VERSION ""

NS_ :

BS_:

BU_: WSGW VCM TBIOM RCIOM FCIOM CCIOM BPMU

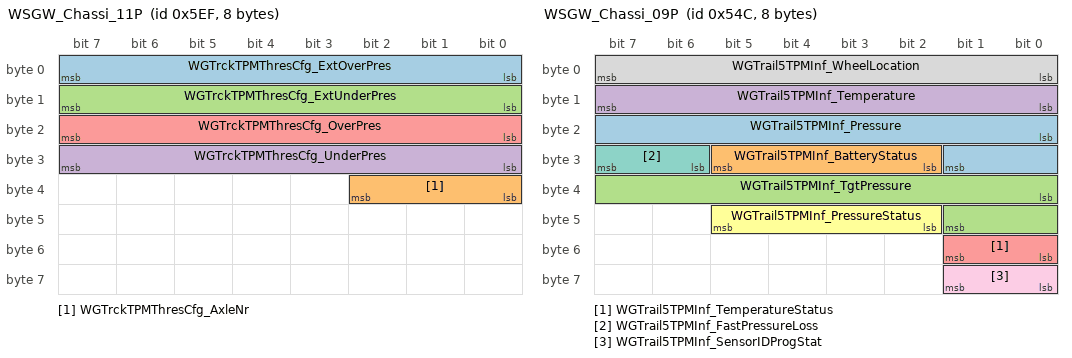
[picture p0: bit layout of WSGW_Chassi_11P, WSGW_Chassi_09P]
BO_ 1519 WSGW_Chassi_11P: 8 WSGW
 SG_ WGTrckTPMThresCfg_ExtOverPres : 0|8@1+ (1,-125) [-125|130] "Percent"  VCM
 SG_ WGTrckTPMThresCfg_AxleNr : 32|3@1+ (1,0) [0|0] ""  VCM
 SG_ WGTrckTPMThresCfg_ExtUnderPres : 8|8@1+ (1,-125) [-125|130] "Percent"  VCM
 SG_ WGTrckTPMThresCfg_UnderPres : 24|8@1+ (1,-125) [-125|130] "Percent"  VCM
 SG_ WGTrckTPMThresCfg_OverPres : 16|8@1+ (1,-125) [-125|130] "Percent"  VCM

BO_ 1513 WSGW_Chassi_10S_C04_FCM: 8 VCM
 SG_ WSGW_Chassi_10S_FCS : 0|64@1+ (1,0) [0|0] ""  WSGW

BO_ 1512 WSGW_Chassi_10S_C04: 21 WSGW
 SG_ PhyDiagTPM2BrkReqSig_ISig_4 : 0|168@1+ (1,0) [0|0] ""  VCM

BO_ 1356 WSGW_Chassi_09P: 8 WSGW
 SG_ WGTrail5TPMInf_Pressure : 16|10@1+ (2,0) [0|2046] "kPa"  VCM
 SG_ WGTrail5TPMInf_BatteryStatus : 26|4@1+ (1,0) [0|0] ""  VCM
 SG_ WGTrail5TPMInf_TgtPressure : 32|10@1+ (2,0) [0|2046] "kPa"  VCM
 SG_ WGTrail5TPMInf_Temperature : 8|8@1+ (1,-40) [-40|215] "DegreeC"  VCM
 SG_ WGTrail5TPMInf_TemperatureStatus : 48|2@1+ (1,0) [0|0] ""  VCM
 SG_ WGTrail5TPMInf_PressureStatus : 42|4@1+ (1,0) [0|0] ""  VCM
 SG_ WGTrail5TPMInf_FastPressureLoss : 30|2@1+ (1,0) [0|0] ""  VCM
 SG_ WGTrail5TPMInf_WheelLocation : 0|8@1+ (1,0) [0|255] "NotApplicable"  VCM
 SG_ WGTrail5TPMInf_SensorIDProgStat : 56|2@1+ (1,0) [0|0] ""  VCM

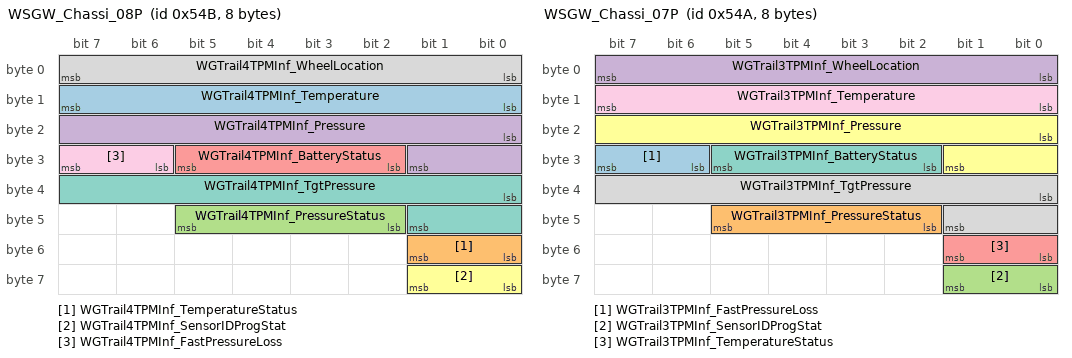
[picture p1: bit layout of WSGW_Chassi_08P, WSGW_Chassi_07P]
BO_ 1355 WSGW_Chassi_08P: 8 WSGW
 SG_ WGTrail4TPMInf_Temperature : 8|8@1+ (1,-40) [-40|215] "DegreeC"  VCM
 SG_ WGTrail4TPMInf_TemperatureStatus : 48|2@1+ (1,0) [0|0] ""  VCM
 SG_ WGTrail4TPMInf_PressureStatus : 42|4@1+ (1,0) [0|0] ""  VCM
 SG_ WGTrail4TPMInf_Pressure : 16|10@1+ (2,0) [0|2046] "kPa"  VCM
 SG_ WGTrail4TPMInf_BatteryStatus : 26|4@1+ (1,0) [0|0] ""  VCM
 SG_ WGTrail4TPMInf_SensorIDProgStat : 56|2@1+ (1,0) [0|0] ""  VCM
 SG_ WGTrail4TPMInf_TgtPressure : 32|10@1+ (2,0) [0|2046] "kPa"  VCM
 SG_ WGTrail4TPMInf_WheelLocation : 0|8@1+ (1,0) [0|255] "NotApplicable"  VCM
 SG_ WGTrail4TPMInf_FastPressureLoss : 30|2@1+ (1,0) [0|0] ""  VCM

BO_ 1354 WSGW_Chassi_07P: 8 WSGW
 SG_ WGTrail3TPMInf_FastPressureLoss : 30|2@1+ (1,0) [0|0] ""  VCM
 SG_ WGTrail3TPMInf_PressureStatus : 42|4@1+ (1,0) [0|0] ""  VCM
 SG_ WGTrail3TPMInf_SensorIDProgStat : 56|2@1+ (1,0) [0|0] ""  VCM
 SG_ WGTrail3TPMInf_WheelLocation : 0|8@1+ (1,0) [0|255] "NotApplicable"  VCM
 SG_ WGTrail3TPMInf_TemperatureStatus : 48|2@1+ (1,0) [0|0] ""  VCM
 SG_ WGTrail3TPMInf_Pressure : 16|10@1+ (2,0) [0|2046] "kPa"  VCM
 SG_ WGTrail3TPMInf_BatteryStatus : 26|4@1+ (1,0) [0|0] ""  VCM
 SG_ WGTrail3TPMInf_TgtPressure : 32|10@1+ (2,0) [0|2046] "kPa"  VCM
 SG_ WGTrail3TPMInf_Temperature : 8|8@1+ (1,-40) [-40|215] "DegreeC"  VCM

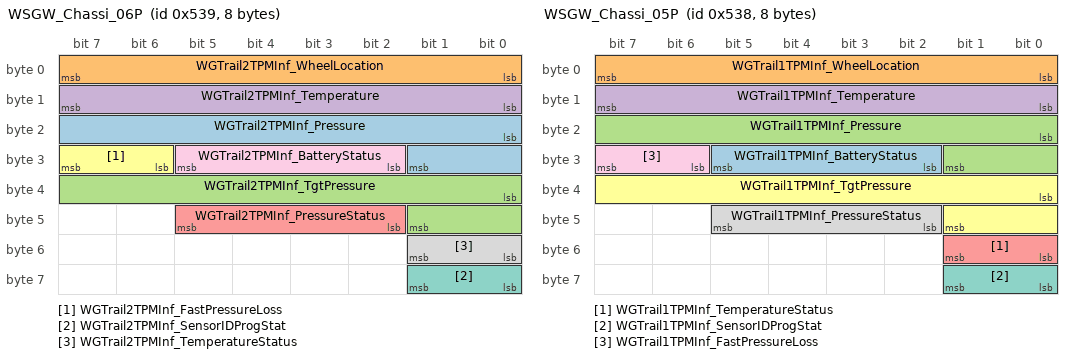
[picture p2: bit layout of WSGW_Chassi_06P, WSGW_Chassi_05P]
BO_ 1337 WSGW_Chassi_06P: 8 WSGW
 SG_ WGTrail2TPMInf_Pressure : 16|10@1+ (2,0) [0|2046] "kPa"  VCM
 SG_ WGTrail2TPMInf_WheelLocation : 0|8@1+ (1,0) [0|255] "NotApplicable"  VCM
 SG_ WGTrail2TPMInf_TgtPressure : 32|10@1+ (2,0) [0|2046] "kPa"  VCM
 SG_ WGTrail2TPMInf_Temperature : 8|8@1+ (1,-40) [-40|215] "DegreeC"  VCM
 SG_ WGTrail2TPMInf_PressureStatus : 42|4@1+ (1,0) [0|0] ""  VCM
 SG_ WGTrail2TPMInf_FastPressureLoss : 30|2@1+ (1,0) [0|0] ""  VCM
 SG_ WGTrail2TPMInf_SensorIDProgStat : 56|2@1+ (1,0) [0|0] ""  VCM
 SG_ WGTrail2TPMInf_TemperatureStatus : 48|2@1+ (1,0) [0|0] ""  VCM
 SG_ WGTrail2TPMInf_BatteryStatus : 26|4@1+ (1,0) [0|0] ""  VCM

BO_ 1336 WSGW_Chassi_05P: 8 WSGW
 SG_ WGTrail1TPMInf_BatteryStatus : 26|4@1+ (1,0) [0|0] ""  VCM
 SG_ WGTrail1TPMInf_WheelLocation : 0|8@1+ (1,0) [0|255] "NotApplicable"  VCM
 SG_ WGTrail1TPMInf_Pressure : 16|10@1+ (2,0) [0|2046] "kPa"  VCM
 SG_ WGTrail1TPMInf_Temperature : 8|8@1+ (1,-40) [-40|215] "DegreeC"  VCM
 SG_ WGTrail1TPMInf_TemperatureStatus : 48|2@1+ (1,0) [0|0] ""  VCM
 SG_ WGTrail1TPMInf_TgtPressure : 32|10@1+ (2,0) [0|2046] "kPa"  VCM
 SG_ WGTrail1TPMInf_SensorIDProgStat : 56|2@1+ (1,0) [0|0] ""  VCM
 SG_ WGTrail1TPMInf_PressureStatus : 42|4@1+ (1,0) [0|0] ""  VCM
 SG_ WGTrail1TPMInf_FastPressureLoss : 30|2@1+ (1,0) [0|0] ""  VCM

BO_ 1283 WSGW_Chassi_04P: 8 WSGW
 SG_ WGTPMPosOfWMResp_VehiclePos : 11|3@1+ (1,0) [0|0] ""  VCM
 SG_ WGTrailer4TPMLostCom : 32|2@1+ (1,0) [0|0] ""  VCM
 SG_ WGTruckTPMFailure : 14|2@1+ (1,0) [0|0] ""  VCM
 SG_ WGTrailer5TPMLostCom : 34|2@1+ (1,0) [0|0] ""  VCM
 SG_ WGTrlr1TPMMatedStatus : 36|2@1+ (1,0) [0|0] ""  VCM
 SG_ WGTrailer5TPMFailure : 24|2@1+ (1,0) [0|0] ""  VCM
 SG_ WGTrlr5TPMMatedStatus : 44|2@1+ (1,0) [0|0] ""  VCM
 SG_ WGTrailer1TPMLostCom : 26|2@1+ (1,0) [0|0] ""  VCM
 SG_ WGTrailer1TPMFailure : 16|2@1+ (1,0) [0|0] ""  VCM
 SG_ WGTrailer2TPMFailure : 18|2@1+ (1,0) [0|0] ""  VCM
 SG_ WGTrailer4TPMFailure : 22|2@1+ (1,0) [0|0] ""  VCM
 SG_ WGTrailer2TPMLostCom : 28|2@1+ (1,0) [0|0] ""  VCM
 SG_ WGTrailer3TPMFailure : 20|2@1+ (1,0) [0|0] ""  VCM
 SG_ WGTrlr3TPMMatedStatus : 40|2@1+ (1,0) [0|0] ""  VCM
 SG_ WGTPMPosOfWMResp_TireId : 0|8@1+ (1,0) [0|255] "NotApplicable"  VCM
 SG_ WGTrailer3TPMLostCom : 30|2@1+ (1,0) [0|0] ""  VCM
 SG_ WGTrlr4TPMMatedStatus : 42|2@1+ (1,0) [0|0] ""  VCM
 SG_ WGTrlr2TPMMatedStatus : 38|2@1+ (1,0) [0|0] ""  VCM
 SG_ WGTPMPosOfWMResp_Status : 8|3@1+ (1,0) [0|0] ""  VCM

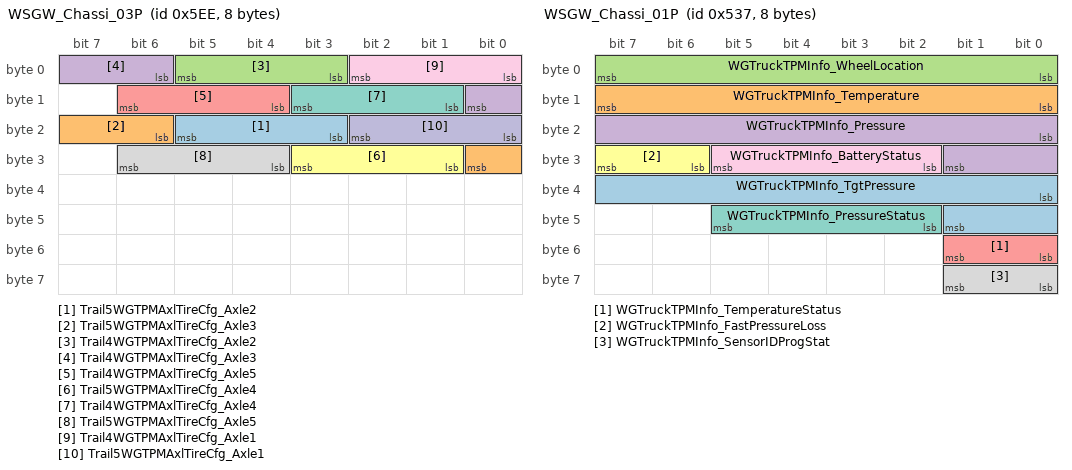
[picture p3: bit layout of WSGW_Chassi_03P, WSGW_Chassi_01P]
BO_ 1518 WSGW_Chassi_03P: 8 WSGW
 SG_ Trail5WGTPMAxlTireCfg_Axle2 : 19|3@1+ (1,0) [0|0] ""  VCM
 SG_ Trail5WGTPMAxlTireCfg_Axle3 : 22|3@1+ (1,0) [0|0] ""  VCM
 SG_ Trail4WGTPMAxlTireCfg_Axle2 : 3|3@1+ (1,0) [0|0] ""  VCM
 SG_ Trail4WGTPMAxlTireCfg_Axle3 : 6|3@1+ (1,0) [0|0] ""  VCM
 SG_ Trail4WGTPMAxlTireCfg_Axle5 : 12|3@1+ (1,0) [0|0] ""  VCM
 SG_ Trail5WGTPMAxlTireCfg_Axle4 : 25|3@1+ (1,0) [0|0] ""  VCM
 SG_ Trail4WGTPMAxlTireCfg_Axle4 : 9|3@1+ (1,0) [0|0] ""  VCM
 SG_ Trail5WGTPMAxlTireCfg_Axle5 : 28|3@1+ (1,0) [0|0] ""  VCM
 SG_ Trail4WGTPMAxlTireCfg_Axle1 : 0|3@1+ (1,0) [0|0] ""  VCM
 SG_ Trail5WGTPMAxlTireCfg_Axle1 : 16|3@1+ (1,0) [0|0] ""  VCM

BO_ 1520 WSGW_Chassi_02P: 8 WSGW
 SG_ WGTruckTPMAxlTireCfg_Axle5 : 12|3@1+ (1,0) [0|0] ""  VCM
 SG_ Trail3WGTPMAxlTireCfg_Axle2 : 51|3@1+ (1,0) [0|0] ""  VCM
 SG_ WGTruckTPMAxlTireCfg_Axle4 : 9|3@1+ (1,0) [0|0] ""  VCM
 SG_ WGTruckTPMAxlTireCfg_Axle3 : 6|3@1+ (1,0) [0|0] ""  VCM
 SG_ Trail3WGTPMAxlTireCfg_Axle3 : 54|3@1+ (1,0) [0|0] ""  VCM
 SG_ Trail1WGTPMAxlTireCfg_Axle4 : 25|3@1+ (1,0) [0|0] ""  VCM
 SG_ WGTruckTPMAxlTireCfg_Axle2 : 3|3@1+ (1,0) [0|0] ""  VCM
 SG_ Trail2WGTPMAxlTireCfg_Axle3 : 38|3@1+ (1,0) [0|0] ""  VCM
 SG_ Trail3WGTPMAxlTireCfg_Axle1 : 48|3@1+ (1,0) [0|0] ""  VCM
 SG_ Trail2WGTPMAxlTireCfg_Axle2 : 35|3@1+ (1,0) [0|0] ""  VCM
 SG_ Trail1WGTPMAxlTireCfg_Axle1 : 16|3@1+ (1,0) [0|0] ""  VCM
 SG_ Trail1WGTPMAxlTireCfg_Axle5 : 28|3@1+ (1,0) [0|0] ""  VCM
 SG_ Trail3WGTPMAxlTireCfg_Axle4 : 57|3@1+ (1,0) [0|0] ""  VCM
 SG_ Trail2WGTPMAxlTireCfg_Axle5 : 44|3@1+ (1,0) [0|0] ""  VCM
 SG_ Trail1WGTPMAxlTireCfg_Axle3 : 22|3@1+ (1,0) [0|0] ""  VCM
 SG_ WGTruckTPMAxlTireCfg_Axle1 : 0|3@1+ (1,0) [0|0] ""  VCM
 SG_ Trail2WGTPMAxlTireCfg_Axle1 : 32|3@1+ (1,0) [0|0] ""  VCM
 SG_ Trail2WGTPMAxlTireCfg_Axle4 : 41|3@1+ (1,0) [0|0] ""  VCM
 SG_ Trail3WGTPMAxlTireCfg_Axle5 : 60|3@1+ (1,0) [0|0] ""  VCM
 SG_ Trail1WGTPMAxlTireCfg_Axle2 : 19|3@1+ (1,0) [0|0] ""  VCM

BO_ 1335 WSGW_Chassi_01P: 8 WSGW
 SG_ WGTruckTPMInfo_TgtPressure : 32|10@1+ (2,0) [0|2046] "kPa"  VCM
 SG_ WGTruckTPMInfo_Temperature : 8|8@1+ (1,-40) [-40|215] "DegreeC"  VCM
 SG_ WGTruckTPMInfo_WheelLocation : 0|8@1+ (1,0) [0|255] "NotApplicable"  VCM
 SG_ WGTruckTPMInfo_Pressure : 16|10@1+ (2,0) [0|2046] "kPa"  VCM
 SG_ WGTruckTPMInfo_TemperatureStatus : 48|2@1+ (1,0) [0|0] ""  VCM
 SG_ WGTruckTPMInfo_FastPressureLoss : 30|2@1+ (1,0) [0|0] ""  VCM
 SG_ WGTruckTPMInfo_PressureStatus : 42|4@1+ (1,0) [0|0] ""  VCM
 SG_ WGTruckTPMInfo_SensorIDProgStat : 56|2@1+ (1,0) [0|0] ""  VCM
 SG_ WGTruckTPMInfo_BatteryStatus : 26|4@1+ (1,0) [0|0] ""  VCM

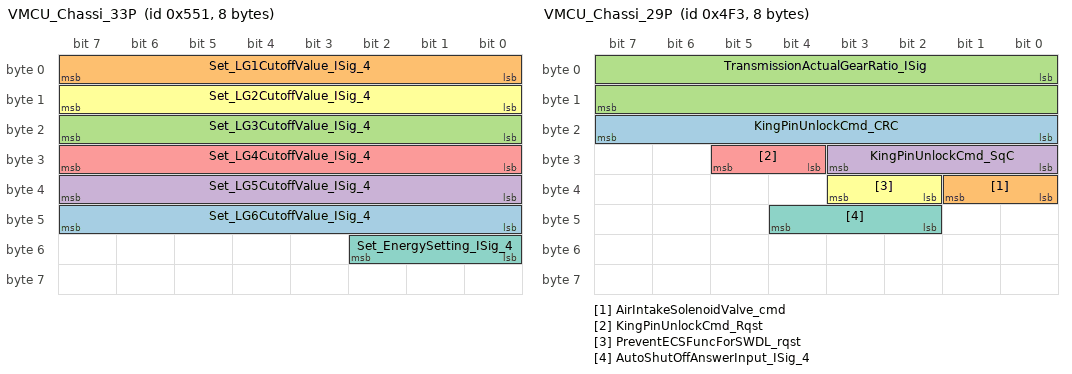
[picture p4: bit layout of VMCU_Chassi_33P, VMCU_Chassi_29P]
BO_ 1361 VMCU_Chassi_33P: 8 VCM
 SG_ Set_LG6CutoffValue_ISig_4 : 40|8@1+ (1,0) [0|255] "Percent"  CCIOM
 SG_ Set_LG1CutoffValue_ISig_4 : 0|8@1+ (1,0) [0|255] "Percent"  CCIOM
 SG_ Set_LG3CutoffValue_ISig_4 : 16|8@1+ (1,0) [0|255] "Percent"  CCIOM
 SG_ Set_LG5CutoffValue_ISig_4 : 32|8@1+ (1,0) [0|255] "Percent"  CCIOM
 SG_ Set_LG4CutoffValue_ISig_4 : 24|8@1+ (1,0) [0|255] "Percent"  CCIOM
 SG_ Set_LG2CutoffValue_ISig_4 : 8|8@1+ (1,0) [0|255] "Percent"  CCIOM
 SG_ Set_EnergySetting_ISig_4 : 48|3@1+ (1,0) [0|0] ""  CCIOM

BO_ 1267 VMCU_Chassi_29P: 8 VCM
 SG_ KingPinUnlockCmd_CRC : 16|8@1+ (1,0) [0|255] ""  CCIOM
 SG_ AirIntakeSolenoidValve_cmd : 32|2@1+ (1,0) [0|0] ""  CCIOM
 SG_ TransmissionActualGearRatio_ISig : 0|16@1+ (0.001,0) [0|65.535] "NotApplicable"  RCIOM
 SG_ KingPinUnlockCmd_SqC : 24|4@1+ (1,0) [0|14] "NotApplicable"  CCIOM
 SG_ KingPinUnlockCmd_Rqst : 28|2@1+ (1,0) [0|0] ""  CCIOM
 SG_ PreventECSFuncForSWDL_rqst : 34|2@1+ (1,0) [0|0] ""  RCIOM
 SG_ AutoShutOffAnswerInput_ISig_4 : 42|3@1+ (1,0) [0|0] ""  CCIOM

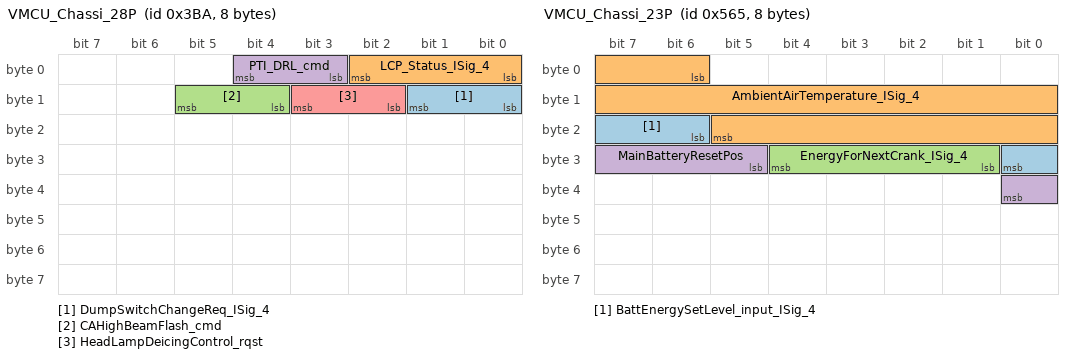
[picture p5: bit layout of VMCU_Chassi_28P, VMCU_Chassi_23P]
BO_ 954 VMCU_Chassi_28P: 8 VCM
 SG_ DumpSwitchChangeReq_ISig_4 : 8|2@1+ (1,0) [0|0] ""  RCIOM
 SG_ LCP_Status_ISig_4 : 0|3@1+ (1,0) [0|0] ""  FCIOM,RCIOM
 SG_ CAHighBeamFlash_cmd : 12|2@1+ (1,0) [0|0] ""  FCIOM
 SG_ PTI_DRL_cmd : 3|2@1+ (1,0) [0|0] ""  FCIOM
 SG_ HeadLampDeicingControl_rqst : 10|2@1+ (1,0) [0|0] ""  FCIOM

BO_ 677 VMCU_Chassi_27P: 8 VCM
 SG_ EngineStarterMode_ISig_4 : 0|4@1+ (1,0) [0|0] ""  CCIOM

BO_ 1363 VMCU_Chassi_26P: 8 VCM
 SG_ PredeliveryModeIndication_cmd_IS : 56|2@1+ (1,0) [0|0] ""  CCIOM

BO_ 535 VMCU_Chassi_24P: 8 VCM
 SG_ DirectionIndicatorLightsStatus_I : 2|4@1+ (1,0) [0|0] ""  FCIOM,RCIOM
 SG_ HeadlightAngle_cmd : 56|8@1+ (0.025,-4) [-4|2.375] "deg"  FCIOM

BO_ 1381 VMCU_Chassi_23P: 8 VCM
 SG_ BattEnergySetLevel_input_ISig_4 : 22|3@1+ (1,0) [0|0] ""  CCIOM
 SG_ AmbientAirTemperature_ISig_4 : 6|16@1+ (0.03125,-273) [-273|1774.96875] "DegreeC"  FCIOM,BPMU,RCIOM,WSGW,CCIOM
 SG_ EnergyForNextCrank_ISig_4 : 25|4@1+ (1,0) [0|15] "Wh"  CCIOM
 SG_ MainBatteryResetPos : 29|4@1+ (1,0) [0|0] ""  CCIOM

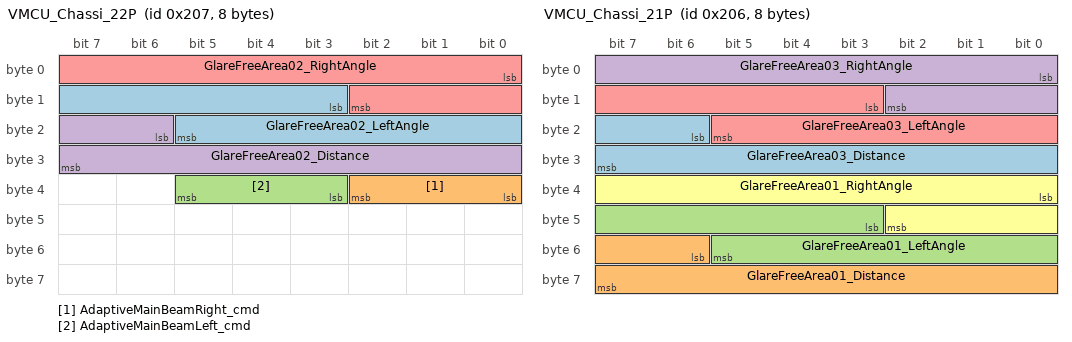
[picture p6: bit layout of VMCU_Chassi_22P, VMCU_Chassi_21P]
BO_ 519 VMCU_Chassi_22P: 8 VCM
 SG_ GlareFreeArea02_LeftAngle : 11|11@1+ (0.0494,-31.65) [-31.65|69.4718] "deg"  FCIOM
 SG_ AdaptiveMainBeamRight_cmd : 32|3@1+ (1,0) [0|0] ""  FCIOM
 SG_ AdaptiveMainBeamLeft_cmd : 35|3@1+ (1,0) [0|0] ""  FCIOM
 SG_ GlareFreeArea02_Distance : 22|10@1+ (0.5,0) [0|511.5] "m"  FCIOM
 SG_ GlareFreeArea02_RightAngle : 0|11@1+ (0.0494,-31.65) [-31.65|69.4718] "deg"  FCIOM

BO_ 518 VMCU_Chassi_21P: 8 VCM
 SG_ GlareFreeArea03_Distance : 22|10@1+ (0.5,0) [0|511.5] "m"  FCIOM
 SG_ GlareFreeArea01_Distance : 54|10@1+ (0.5,0) [0|511.5] "m"  FCIOM
 SG_ GlareFreeArea01_LeftAngle : 43|11@1+ (0.0494,-31.65) [-31.65|69.4718] "deg"  FCIOM
 SG_ GlareFreeArea03_RightAngle : 0|11@1+ (0.0494,-31.65) [-31.65|69.4718] "deg"  FCIOM
 SG_ GlareFreeArea03_LeftAngle : 11|11@1+ (0.0494,-31.65) [-31.65|69.4718] "deg"  FCIOM
 SG_ GlareFreeArea01_RightAngle : 32|11@1+ (0.0494,-31.65) [-31.65|69.4718] "deg"  FCIOM

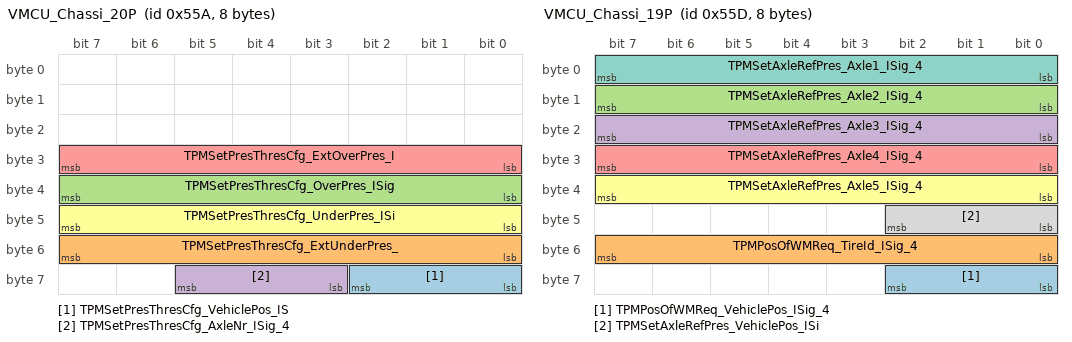
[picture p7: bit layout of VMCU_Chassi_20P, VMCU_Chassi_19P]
BO_ 1370 VMCU_Chassi_20P: 8 VCM
 SG_ TPMSetPresThresCfg_VehiclePos_IS : 56|3@1+ (1,0) [0|0] ""  WSGW
 SG_ TPMSetPresThresCfg_ExtUnderPres_ : 48|8@1+ (1,-125) [-125|130] "Percent"  WSGW
 SG_ TPMSetPresThresCfg_OverPres_ISig : 32|8@1+ (1,-125) [-125|130] "Percent"  WSGW
 SG_ TPMSetPresThresCfg_AxleNr_ISig_4 : 59|3@1+ (1,0) [0|0] ""  WSGW
 SG_ TPMSetPresThresCfg_ExtOverPres_I : 24|8@1+ (1,-125) [-125|130] "Percent"  WSGW
 SG_ TPMSetPresThresCfg_UnderPres_ISi : 40|8@1+ (1,-125) [-125|130] "Percent"  WSGW

BO_ 1373 VMCU_Chassi_19P: 8 VCM
 SG_ TPMPosOfWMReq_VehiclePos_ISig_4 : 56|3@1+ (1,0) [0|0] ""  WSGW
 SG_ TPMPosOfWMReq_TireId_ISig_4 : 48|8@1+ (1,0) [0|255] "NotApplicable"  WSGW
 SG_ TPMSetAxleRefPres_Axle2_ISig_4 : 8|8@1+ (10,0) [0|2550] "kPa"  WSGW
 SG_ TPMSetAxleRefPres_Axle3_ISig_4 : 16|8@1+ (10,0) [0|2550] "kPa"  WSGW
 SG_ TPMSetAxleRefPres_Axle4_ISig_4 : 24|8@1+ (10,0) [0|2550] "kPa"  WSGW
 SG_ TPMSetAxleRefPres_Axle5_ISig_4 : 32|8@1+ (10,0) [0|2550] "kPa"  WSGW
 SG_ TPMSetAxleRefPres_Axle1_ISig_4 : 0|8@1+ (10,0) [0|2550] "kPa"  WSGW
 SG_ TPMSetAxleRefPres_VehiclePos_ISi : 40|3@1+ (1,0) [0|0] ""  WSGW

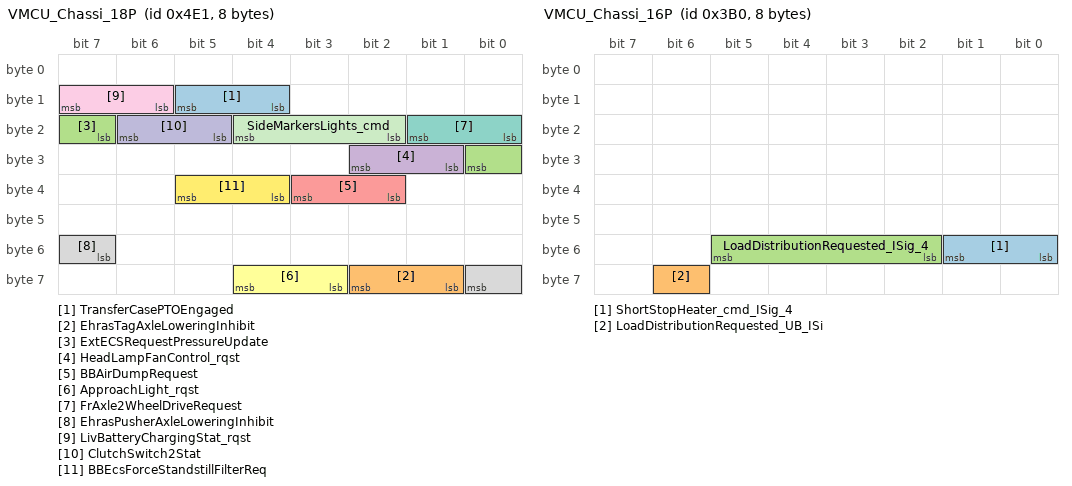
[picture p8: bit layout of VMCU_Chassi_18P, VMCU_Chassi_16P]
BO_ 1249 VMCU_Chassi_18P: 8 VCM
 SG_ TransferCasePTOEngaged : 12|2@1+ (1,0) [0|0] ""  RCIOM
 SG_ EhrasTagAxleLoweringInhibit : 57|2@1+ (1,0) [0|0] ""  RCIOM
 SG_ ExtECSRequestPressureUpdate : 23|2@1+ (1,0) [0|0] ""  RCIOM
 SG_ HeadLampFanControl_rqst : 25|2@1+ (1,0) [0|0] ""  FCIOM
 SG_ BBAirDumpRequest : 34|2@1+ (1,0) [0|0] ""  RCIOM
 SG_ ApproachLight_rqst : 59|2@1+ (1,0) [0|0] ""  RCIOM
 SG_ FrAxle2WheelDriveRequest : 16|2@1+ (1,0) [0|0] ""  CCIOM
 SG_ EhrasPusherAxleLoweringInhibit : 55|2@1+ (1,0) [0|0] ""  RCIOM
 SG_ LivBatteryChargingStat_rqst : 14|2@1+ (1,0) [0|0] ""  CCIOM
 SG_ ClutchSwitch2Stat : 21|2@1+ (1,0) [0|0] ""  CCIOM
 SG_ SideMarkersLights_cmd : 18|3@1+ (1,0) [0|0] ""  CCIOM
 SG_ BBEcsForceStandstillFilterReq : 36|2@1+ (1,0) [0|0] ""  RCIOM,CCIOM

BO_ 944 VMCU_Chassi_16P: 8 VCM
 SG_ ShortStopHeater_cmd_ISig_4 : 48|2@1+ (1,0) [0|0] ""  CCIOM
 SG_ LoadDistributionRequested_UB_ISi : 62|1@1+ (1,0) [0|0] ""  RCIOM
 SG_ LoadDistributionRequested_ISig_4 : 50|4@1+ (1,0) [0|0] ""  RCIOM

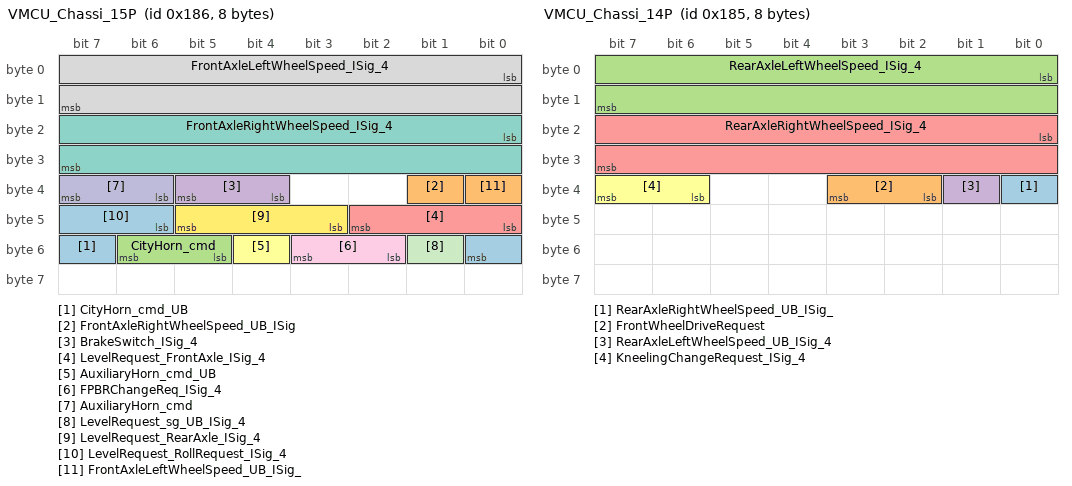
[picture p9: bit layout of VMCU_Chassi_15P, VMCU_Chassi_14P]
BO_ 390 VMCU_Chassi_15P: 8 VCM
 SG_ CityHorn_cmd_UB : 55|1@1+ (1,0) [0|0] ""  FCIOM
 SG_ FrontAxleRightWheelSpeed_UB_ISig : 33|1@1+ (1,0) [0|0] ""  CCIOM
 SG_ CityHorn_cmd : 53|2@1+ (1,0) [0|0] ""  FCIOM
 SG_ BrakeSwitch_ISig_4 : 36|2@1+ (1,0) [0|0] ""  CCIOM
 SG_ LevelRequest_FrontAxle_ISig_4 : 40|3@1+ (1,0) [0|0] ""  RCIOM
 SG_ AuxiliaryHorn_cmd_UB : 52|1@1+ (1,0) [0|0] ""  FCIOM
 SG_ FrontAxleRightWheelSpeed_ISig_4 : 16|16@1+ (0.00390625,0) [0|255.99609375] "Km_per_h"  CCIOM
 SG_ FrontAxleLeftWheelSpeed_ISig_4 : 0|16@1+ (0.00390625,0) [0|255.99609375] "Km_per_h"  CCIOM
 SG_ FPBRChangeReq_ISig_4 : 50|2@1+ (1,0) [0|0] ""  RCIOM
 SG_ AuxiliaryHorn_cmd : 38|2@1+ (1,0) [0|0] ""  FCIOM
 SG_ LevelRequest_sg_UB_ISig_4 : 49|1@1+ (1,0) [0|0] ""  RCIOM
 SG_ LevelRequest_RearAxle_ISig_4 : 43|3@1+ (1,0) [0|0] ""  RCIOM
 SG_ LevelRequest_RollRequest_ISig_4 : 46|3@1+ (1,0) [0|0] ""  RCIOM
 SG_ FrontAxleLeftWheelSpeed_UB_ISig_ : 32|1@1+ (1,0) [0|0] ""  CCIOM

BO_ 389 VMCU_Chassi_14P: 8 VCM
 SG_ RearAxleRightWheelSpeed_UB_ISig_ : 32|1@1+ (1,0) [0|0] ""  CCIOM,RCIOM
 SG_ FrontWheelDriveRequest : 34|2@1+ (1,0) [0|0] ""  CCIOM
 SG_ RearAxleLeftWheelSpeed_ISig_4 : 0|16@1+ (0.00390625,0) [0|255.99609375] "Km_per_h"  RCIOM,CCIOM
 SG_ RearAxleLeftWheelSpeed_UB_ISig_4 : 33|1@1+ (1,0) [0|0] ""  CCIOM,RCIOM
 SG_ RearAxleRightWheelSpeed_ISig_4 : 16|16@1+ (0.00390625,0) [0|255.99609375] "Km_per_h"  RCIOM,CCIOM
 SG_ KneelingChangeRequest_ISig_4 : 38|2@1+ (1,0) [0|0] ""  RCIOM

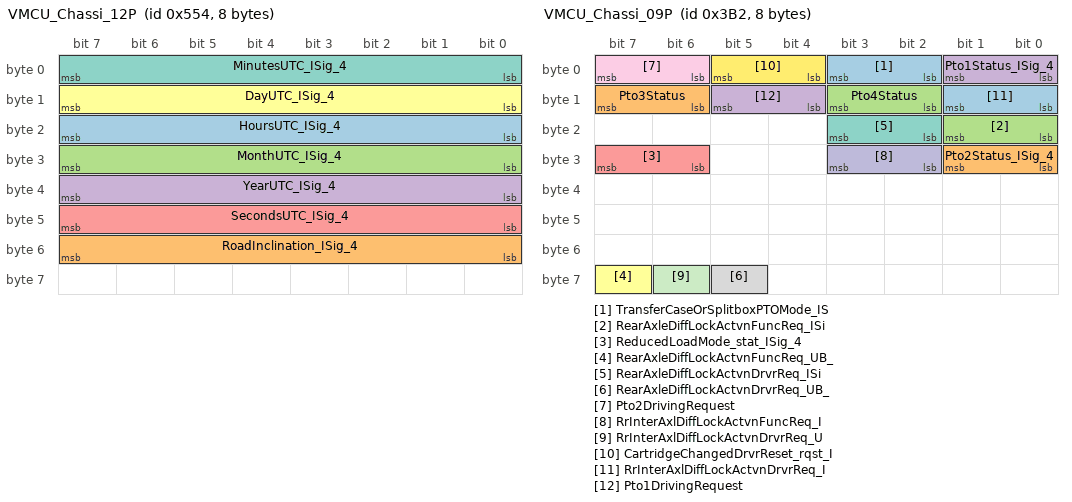
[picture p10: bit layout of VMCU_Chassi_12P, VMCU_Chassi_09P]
BO_ 1364 VMCU_Chassi_12P: 8 VCM
 SG_ HoursUTC_ISig_4 : 16|8@1+ (1,0) [0|255] "h"  FCIOM,RCIOM,CCIOM,BPMU,WSGW
 SG_ RoadInclination_ISig_4 : 48|8@1+ (0.2,-25) [-25|26] "Percent"  RCIOM
 SG_ MonthUTC_ISig_4 : 24|8@1+ (1,0) [0|255] "Months"  BPMU,WSGW,RCIOM,FCIOM,CCIOM
 SG_ YearUTC_ISig_4 : 32|8@1+ (1,1985) [1985|2240] "Years"  CCIOM,FCIOM,RCIOM,WSGW,BPMU
 SG_ SecondsUTC_ISig_4 : 40|8@1+ (0.25,0) [0|63.75] "s"  WSGW,RCIOM,FCIOM,BPMU,CCIOM
 SG_ DayUTC_ISig_4 : 8|8@1+ (0.25,0) [0|63.75] "Days"  RCIOM,CCIOM,FCIOM,BPMU,WSGW
 SG_ MinutesUTC_ISig_4 : 0|8@1+ (1,0) [0|255] "min"  BPMU,CCIOM,RCIOM,WSGW,FCIOM

BO_ 826 VMCU_Chassi_11P: 8 VCM
 SG_ BBContUnlockCmd : 12|2@1+ (1,0) [0|0] ""  CCIOM
 SG_ LampCheck_cmd : 46|2@1+ (1,0) [0|0] ""  FCIOM
 SG_ LampCheck_rqst_ISig_4 : 51|2@1+ (1,0) [0|0] ""  RCIOM
 SG_ BatteryCapacity_ISig_4 : 16|4@1+ (1,0) [0|0] ""  CCIOM
 SG_ AreaInhibit : 10|2@1+ (1,0) [0|0] ""  CCIOM
 SG_ LEDAnimation_cmd : 53|3@1+ (1,0) [0|0] ""  FCIOM
 SG_ ActualDrvlnRetdrPercentTorque_IS : 24|8@1+ (1,-125) [-125|130] "Percent"  RCIOM
 SG_ PloughLampModeStatus_ISig_4 : 56|2@1+ (1,0) [0|0] ""  FCIOM
 SG_ RangeInhibit : 14|2@1+ (1,0) [0|0] ""  CCIOM
 SG_ TrailerBrakeNoEbs_stat : 22|2@1+ (1,0) [0|0] ""  RCIOM
 SG_ LiftAxle1DirectControl_ISig_4 : 60|3@1+ (1,0) [0|0] ""  RCIOM
 SG_ DoorsAjar_stat_ISig_4 : 43|3@1+ (1,0) [0|0] ""  CCIOM
 SG_ BrakeLight_rqst : 32|3@1+ (1,0) [0|0] ""  RCIOM,TBIOM
 SG_ BlackOutandConvoyMode_rqst : 40|3@1+ (1,0) [0|0] ""  RCIOM,CCIOM
 SG_ DoorsAjar_stat_UB_ISig_4 : 7|1@1+ (1,0) [0|0] ""  CCIOM
 SG_ RevLight_cmd : 3|2@1+ (1,0) [0|0] ""  RCIOM,CCIOM
 SG_ LiftAxle1DirectControl_UB_ISig_4 : 63|1@1+ (1,0) [0|0] ""  RCIOM
 SG_ ECSStandByRequest_ISig_4 : 48|3@1+ (1,0) [0|0] ""  RCIOM
 SG_ ChassisInstepLight_cmd : 8|2@1+ (1,0) [0|0] ""  FCIOM
 SG_ BBSlidable5thWheelCmd : 1|2@1+ (1,0) [0|0] ""  CCIOM
 SG_ ParkingBrake_stat_ISig_4 : 58|2@1+ (1,0) [0|0] ""  RCIOM,CCIOM,WSGW
 SG_ MaintBatteryReset : 20|2@1+ (1,0) [0|0] ""  CCIOM

BO_ 1369 VMCU_Chassi_10P: 8 VCM
 SG_ TotalVehicleDistanceHighRes_ISig : 32|32@1+ (5,0) [0|21474836475] "m"  RCIOM,WSGW,CCIOM,FCIOM,BPMU

BO_ 946 VMCU_Chassi_09P: 8 VCM
 SG_ TransferCaseOrSplitboxPTOMode_IS : 2|2@1+ (1,0) [0|0] ""  RCIOM
 SG_ Pto3Status : 14|2@1+ (1,0) [0|0] ""  RCIOM
 SG_ RearAxleDiffLockActvnFuncReq_ISi : 16|2@1+ (1,0) [0|0] ""  RCIOM
 SG_ Pto1Status_ISig_4 : 0|2@1+ (1,0) [0|0] ""  RCIOM
 SG_ ReducedLoadMode_stat_ISig_4 : 30|2@1+ (1,0) [0|0] ""  CCIOM
 SG_ RearAxleDiffLockActvnFuncReq_UB_ : 63|1@1+ (1,0) [0|0] ""  RCIOM
 SG_ RearAxleDiffLockActvnDrvrReq_ISi : 18|2@1+ (1,0) [0|0] ""  RCIOM
 SG_ RearAxleDiffLockActvnDrvrReq_UB_ : 61|1@1+ (1,0) [0|0] ""  RCIOM
 SG_ Pto2DrivingRequest : 6|2@1+ (1,0) [0|0] ""  CCIOM
 SG_ RrInterAxlDiffLockActvnFuncReq_I : 26|2@1+ (1,0) [0|0] ""  RCIOM
 SG_ RrInterAxlDiffLockActvnDrvrReq_U : 62|1@1+ (1,0) [0|0] ""  RCIOM
 SG_ CartridgeChangedDrvrReset_rqst_I : 4|2@1+ (1,0) [0|0] ""  CCIOM
 SG_ RrInterAxlDiffLockActvnDrvrReq_I : 8|2@1+ (1,0) [0|0] ""  RCIOM
 SG_ Pto2Status_ISig_4 : 24|2@1+ (1,0) [0|0] ""  RCIOM
 SG_ Pto4Status : 10|2@1+ (1,0) [0|0] ""  RCIOM
 SG_ Pto1DrivingRequest : 12|2@1+ (1,0) [0|0] ""  CCIOM

CM_ "COM_MATRIX_T3_2.3.0";
CM_ BU_ WSGW "Wireless Sensor Gateway";
CM_ BU_ VCM "Vehicle Control Module";
CM_ BU_ TBIOM "Trailer Body Input Output Module";
CM_ BU_ RCIOM "Rear Chassis Input Output Module";
CM_ BU_ FCIOM "Front Chassis Input Output Module";
CM_ BU_ CCIOM "Center Chassis Input Output Module";
CM_ BU_ BPMU "Battery Power Management Unit";
CM_ BO_ 519 "Sporadic defined on this net, but periodic in reality since triggered every 20ms due to cyclic on BB2";
CM_ BO_ 518 "Sporadic defined on this net, but periodic in reality since triggered every 20ms due to cyclic on BB2";
BA_DEF_ BO_  "GenMsgStartDelayTime" INT 0 0;
BA_DEF_ BO_  "GenMsgDelayTime" INT 0 0;
BA_DEF_ BO_  "GenMsgCycleTime" INT 0 0;
BA_DEF_ BO_  "GenMsgSendType" ENUM  "Cyclic","NotUsed","NotUsed","NotUsed","NotUsed","NotUsed","NotUsed","IfActive","NoMsgSendType","NotUsed";
BA_DEF_ SG_  "GenSigStartValue" INT 0 0;
BA_DEF_ SG_  "GenSigInactiveValue" INT 0 0;
BA_DEF_ SG_  "GenSigCycleTimeActive" INT 0 0;
BA_DEF_ SG_  "GenSigCycleTime" INT 0 0;
BA_DEF_ SG_  "GenSigSendType" ENUM  "Cyclic","OnWrite","OnWriteWithRepetition","OnChange","OnChangeWithRepetition","IfActive","IfActiveWithRepetition","NoSigSendType","NotUsed","NotUsed","NotUsed","NotUsed","NotUsed";
BA_DEF_  "Baudrate" INT 0 1000000;
BA_DEF_  "NmType" STRING ;
BA_DEF_  "Manufacturer" STRING ;
BA_DEF_  "VersionYear" INT 0 99;
BA_DEF_  "VersionNumber" INT 0 99;
BA_DEF_  "VersionMonth" INT 1 12;
BA_DEF_  "VersionDay" INT 1 31;
BA_DEF_ BO_  "VFrameFormat" ENUM  "StandardCAN","ExtendedCAN","reserved","J1939PG","reserved","reserved","reserved","reserved","reserved","reserved","reserved","reserved","reserved","reserved","StandardCAN_FD","ExtendedCAN_FD";
BA_DEF_ BU_  "TpOwnSystemEcuNumber" HEX 0 255;
BA_DEF_ SG_  "SigType" ENUM  "Default","Range","RangeSigned","ASCII","Discrete","Control","ReferencePGN","DTC","StringDelimiter","StringLength","StringLengthControl";
BA_DEF_ SG_  "Platform_Vivis2_Sig" ENUM  "No","Yes";
BA_DEF_ SG_  "Platform_VMCU1_Sig" ENUM  "No","Yes";
BA_DEF_ BU_  "NmStationAddress" INT 0 255;
BA_DEF_  "NmAsrWaitBusSleepTime" INT 0 65535;
BA_DEF_  "NmAsrTimeoutTime" INT 0 65535;
BA_DEF_  "NmAsrRepeatMessageTime" INT 0 65535;
BA_DEF_ BU_  "NmAsrNodeIdentifier" HEX 0 253;
BA_DEF_ BU_  "NmAsrNode" ENUM  "No","Yes";
BA_DEF_  "NmAsrMessageCount" INT 1 256;
BA_DEF_ BO_  "NmAsrMessage" ENUM  "No","Yes";
BA_DEF_  "NmAsrCanMsgCycleTime" INT 0 65535;
BA_DEF_  "NmAsrBaseAddress" HEX 0 536870911;
BA_DEF_ SG_  "NeedsUpdateBit" ENUM  "No","Yes";
BA_DEF_ SG_  "MmAnSignal" ENUM  "No","Yes";
BA_DEF_ BU_  "IsOBDrelevant" ENUM  "No","Yes";
BA_DEF_ SG_  "GenSigMaxLatency" INT 0 65535;
BA_DEF_ SG_  "GenSigILSupport" ENUM  "Yes","No";
BA_DEF_ BO_  "GenMsgILSupport" ENUM  "No","Yes";
BA_DEF_ SG_  "E2EProfile" STRING ;
BA_DEF_  "E2EP05WindowSize" INT 0 65535;
BA_DEF_  "E2EP05ProfileName" STRING ;
BA_DEF_  "E2EP05MinOkStateValid" INT 0 65535;
BA_DEF_  "E2EP05MinOkStateInvalid" INT 0 65535;
BA_DEF_  "E2EP05MinOkStateInit" INT 0 65535;
BA_DEF_  "E2EP05MaxErrorStateValid" INT 0 65535;
BA_DEF_  "E2EP05MaxErrorStateInvalid" INT 0 65535;
BA_DEF_  "E2EP05MaxErrorStateInit" INT 0 65535;
BA_DEF_  "E2EP05MaxDeltaCounter" INT 0 65535;
BA_DEF_  "E2EP01WindowSize" INT 0 65535;
BA_DEF_  "E2EP01SyncCounterInit" INT 0 65535;
BA_DEF_  "E2EP01ProfileName" STRING ;
BA_DEF_  "E2EP01MinOkStateValid" INT 0 65535;
BA_DEF_  "E2EP01MinOkStateInvalid" INT 0 65535;
BA_DEF_  "E2EP01MinOkStateInit" INT 0 65535;
BA_DEF_  "E2EP01MaxNoNewOrRepeatedData" INT 0 65535;
BA_DEF_  "E2EP01MaxErrorStateValid" INT 0 65535;
BA_DEF_  "E2EP01MaxErrorStateInvalid" INT 0 65535;
BA_DEF_  "E2EP01MaxErrorStateInit" INT 0 65535;
BA_DEF_  "E2EP01MaxDeltaCounter" INT 0 65535;
BA_DEF_  "E2EP01DataIdMode" ENUM  "all16Bit","alternating8Bit","lower12Bit","lower8Bit";
BA_DEF_  "E2EP01CounterOffset" INT 0 65535;
BA_DEF_ SG_  "E2EDataLength" INT 0 65535;
BA_DEF_ SG_  "E2EDataId" INT 0 65535;
BA_DEF_ BU_  "DiagnosticClientAddress" HEX 0 255;
BA_DEF_ BO_  "DiagUUDTResponse" ENUM  "No","Yes";
BA_DEF_ BO_  "DiagState" ENUM  "No","Yes";
BA_DEF_ BU_  "DiagRole" ENUM  "None","OBDTester","ExternalTester","InternalTester";
BA_DEF_ BO_  "DiagResponse" ENUM  "No","Yes";
BA_DEF_ BO_  "DiagRequest" ENUM  "No","Yes";
BA_DEF_ BO_  "DiagConnection" HEX 0 65535;
BA_DEF_  "DBName" STRING ;
BA_DEF_ BO_  "CanTpFcFrameId" HEX 0 2147483647;
BA_DEF_ BO_  "CanTpBs" INT 0 255;
BA_DEF_  "BusType" STRING ;
BA_DEF_ SG_  "SystemSignalLongSymbol" STRING ;
BA_DEF_REL_ BU_SG_REL_  "GenSigTimeoutTime" INT 0 65535;
BA_DEF_REL_ BU_SG_REL_  "GenSigFirstTimeoutTime" INT 0 65535;
BA_DEF_DEF_  "GenMsgStartDelayTime" 0;
BA_DEF_DEF_  "GenMsgDelayTime" 0;
BA_DEF_DEF_  "GenMsgCycleTime" 0;
BA_DEF_DEF_  "GenMsgSendType" "Cyclic";
BA_DEF_DEF_  "GenSigStartValue" 0;
BA_DEF_DEF_  "GenSigInactiveValue" 0;
BA_DEF_DEF_  "GenSigCycleTimeActive" 0;
BA_DEF_DEF_  "GenSigCycleTime" 0;
BA_DEF_DEF_  "GenSigSendType" "Cyclic";
BA_DEF_DEF_  "Baudrate" 500000;
BA_DEF_DEF_  "NmType" "";
BA_DEF_DEF_  "Manufacturer" "VOLVO_AB";
BA_DEF_DEF_  "VersionYear" 0;
BA_DEF_DEF_  "VersionNumber" 0;
BA_DEF_DEF_  "VersionMonth" 1;
BA_DEF_DEF_  "VersionDay" 1;
BA_DEF_DEF_  "VFrameFormat" "ExtendedCAN";
BA_DEF_DEF_  "TpOwnSystemEcuNumber" 0;
BA_DEF_DEF_  "SigType" "Default";
BA_DEF_DEF_  "Platform_Vivis2_Sig" "No";
BA_DEF_DEF_  "Platform_VMCU1_Sig" "No";
BA_DEF_DEF_  "NmStationAddress" 254;
BA_DEF_DEF_  "NmAsrWaitBusSleepTime" 750;
BA_DEF_DEF_  "NmAsrTimeoutTime" 5000;
BA_DEF_DEF_  "NmAsrRepeatMessageTime" 300;
BA_DEF_DEF_  "NmAsrNodeIdentifier" 0;
BA_DEF_DEF_  "NmAsrNode" "Yes";
BA_DEF_DEF_  "NmAsrMessageCount" 256;
BA_DEF_DEF_  "NmAsrMessage" "No";
BA_DEF_DEF_  "NmAsrCanMsgCycleTime" 200;
BA_DEF_DEF_  "NmAsrBaseAddress" 486506496;
BA_DEF_DEF_  "NeedsUpdateBit" "No";
BA_DEF_DEF_  "MmAnSignal" "No";
BA_DEF_DEF_  "IsOBDrelevant" "No";
BA_DEF_DEF_  "GenSigMaxLatency" 0;
BA_DEF_DEF_  "GenSigILSupport" "Yes";
BA_DEF_DEF_  "GenMsgILSupport" "Yes";
BA_DEF_DEF_  "E2EProfile" "none";
BA_DEF_DEF_  "E2EP05WindowSize" 5;
BA_DEF_DEF_  "E2EP05ProfileName" "PROFILE_05";
BA_DEF_DEF_  "E2EP05MinOkStateValid" 1;
BA_DEF_DEF_  "E2EP05MinOkStateInvalid" 3;
BA_DEF_DEF_  "E2EP05MinOkStateInit" 1;
BA_DEF_DEF_  "E2EP05MaxErrorStateValid" 3;
BA_DEF_DEF_  "E2EP05MaxErrorStateInvalid" 1;
BA_DEF_DEF_  "E2EP05MaxErrorStateInit" 2;
BA_DEF_DEF_  "E2EP05MaxDeltaCounter" 3;
BA_DEF_DEF_  "E2EP01WindowSize" 5;
BA_DEF_DEF_  "E2EP01SyncCounterInit" 1;
BA_DEF_DEF_  "E2EP01ProfileName" "PROFILE_01";
BA_DEF_DEF_  "E2EP01MinOkStateValid" 1;
BA_DEF_DEF_  "E2EP01MinOkStateInvalid" 3;
BA_DEF_DEF_  "E2EP01MinOkStateInit" 1;
BA_DEF_DEF_  "E2EP01MaxNoNewOrRepeatedData" 5;
BA_DEF_DEF_  "E2EP01MaxErrorStateValid" 3;
BA_DEF_DEF_  "E2EP01MaxErrorStateInvalid" 1;
BA_DEF_DEF_  "E2EP01MaxErrorStateInit" 2;
BA_DEF_DEF_  "E2EP01MaxDeltaCounter" 3;
BA_DEF_DEF_  "E2EP01DataIdMode" "all16Bit";
BA_DEF_DEF_  "E2EP01CounterOffset" 8;
BA_DEF_DEF_  "E2EDataLength" 0;
BA_DEF_DEF_  "E2EDataId" 0;
BA_DEF_DEF_  "DiagnosticClientAddress" 0;
BA_DEF_DEF_  "DiagUUDTResponse" "No";
BA_DEF_DEF_  "DiagState" "No";
BA_DEF_DEF_  "DiagRole" "None";
BA_DEF_DEF_  "DiagResponse" "No";
BA_DEF_DEF_  "DiagRequest" "No";
BA_DEF_DEF_  "DiagConnection" 0;
BA_DEF_DEF_  "DBName" "";
BA_DEF_DEF_  "CanTpFcFrameId" 2147483647;
BA_DEF_DEF_  "CanTpBs" 255;
BA_DEF_DEF_  "BusType" "";
BA_DEF_DEF_REL_ "GenSigTimeoutTime" 0;
BA_DEF_DEF_REL_ "GenSigFirstTimeoutTime" 0;
BA_DEF_DEF_  "SystemSignalLongSymbol" "";
BA_ "NmType" "NmAsr";
BA_ "BusType" "CAN";
BA_ "VersionDay" 27;
BA_ "VersionMonth" 2;
BA_ "VersionNumber" 1;
BA_ "VersionYear" 23;
BA_ "DBName" "CAN04";
BA_ "TpOwnSystemEcuNumber" BU_ WSGW 115;
BA_ "NmAsrNodeIdentifier" BU_ WSGW 115;
BA_ "DiagRole" BU_ VCM 3;
BA_ "DiagnosticClientAddress" BU_ VCM 244;
BA_ "IsOBDrelevant" BU_ VCM 1;
BA_ "TpOwnSystemEcuNumber" BU_ VCM 36;
BA_ "NmAsrNodeIdentifier" BU_ VCM 36;
BA_ "TpOwnSystemEcuNumber" BU_ TBIOM 39;
BA_ "NmAsrNodeIdentifier" BU_ TBIOM 39;
BA_ "TpOwnSystemEcuNumber" BU_ RCIOM 34;
BA_ "NmAsrNodeIdentifier" BU_ RCIOM 34;
BA_ "TpOwnSystemEcuNumber" BU_ FCIOM 33;
BA_ "NmAsrNodeIdentifier" BU_ FCIOM 33;
BA_ "TpOwnSystemEcuNumber" BU_ CCIOM 32;
BA_ "NmAsrNodeIdentifier" BU_ CCIOM 32;
BA_ "TpOwnSystemEcuNumber" BU_ BPMU 26;
BA_ "NmAsrNodeIdentifier" BU_ BPMU 26;
BA_ "VFrameFormat" BO_ 1519 0;
BA_ "GenMsgCycleTime" BO_ 1519 1000;
BA_ "GenMsgStartDelayTime" BO_ 1519 50;
BA_ "GenMsgILSupport" BO_ 1513 0;
BA_ "VFrameFormat" BO_ 1513 0;
BA_ "GenMsgSendType" BO_ 1513 8;
BA_ "CanTpFcFrameId" BO_ 1512 1513;
BA_ "VFrameFormat" BO_ 1512 0;
BA_ "GenMsgSendType" BO_ 1512 8;
BA_ "VFrameFormat" BO_ 1356 0;
BA_ "GenMsgCycleTime" BO_ 1356 200;
BA_ "GenMsgStartDelayTime" BO_ 1356 110;
BA_ "VFrameFormat" BO_ 1355 0;
BA_ "GenMsgCycleTime" BO_ 1355 200;
BA_ "GenMsgStartDelayTime" BO_ 1355 85;
BA_ "VFrameFormat" BO_ 1354 0;
BA_ "GenMsgCycleTime" BO_ 1354 200;
BA_ "GenMsgStartDelayTime" BO_ 1354 60;
BA_ "VFrameFormat" BO_ 1337 0;
BA_ "GenMsgCycleTime" BO_ 1337 200;
BA_ "GenMsgStartDelayTime" BO_ 1337 45;
BA_ "VFrameFormat" BO_ 1336 0;
BA_ "GenMsgCycleTime" BO_ 1336 200;
BA_ "GenMsgStartDelayTime" BO_ 1336 25;
BA_ "VFrameFormat" BO_ 1283 0;
BA_ "GenMsgCycleTime" BO_ 1283 200;
BA_ "GenMsgStartDelayTime" BO_ 1283 10;
BA_ "VFrameFormat" BO_ 1518 0;
BA_ "GenMsgCycleTime" BO_ 1518 1000;
BA_ "GenMsgStartDelayTime" BO_ 1518 40;
BA_ "VFrameFormat" BO_ 1520 0;
BA_ "GenMsgCycleTime" BO_ 1520 1000;
BA_ "GenMsgStartDelayTime" BO_ 1520 30;
BA_ "VFrameFormat" BO_ 1335 0;
BA_ "GenMsgCycleTime" BO_ 1335 200;
BA_ "VFrameFormat" BO_ 1361 0;
BA_ "GenMsgCycleTime" BO_ 1361 500;
BA_ "GenMsgStartDelayTime" BO_ 1361 10;
BA_ "VFrameFormat" BO_ 1267 0;
BA_ "GenMsgCycleTime" BO_ 1267 100;
BA_ "GenMsgStartDelayTime" BO_ 1267 75;
BA_ "VFrameFormat" BO_ 954 0;
BA_ "GenMsgCycleTime" BO_ 954 50;
BA_ "GenMsgStartDelayTime" BO_ 954 25;
BA_ "VFrameFormat" BO_ 677 0;
BA_ "GenMsgCycleTime" BO_ 677 20;
BA_ "GenMsgStartDelayTime" BO_ 677 10;
BA_ "VFrameFormat" BO_ 1363 0;
BA_ "GenMsgCycleTime" BO_ 1363 1000;
BA_ "GenMsgStartDelayTime" BO_ 1363 55;
BA_ "VFrameFormat" BO_ 535 0;
BA_ "GenMsgCycleTime" BO_ 535 30;
BA_ "GenMsgStartDelayTime" BO_ 535 25;
BA_ "VFrameFormat" BO_ 1381 0;
BA_ "GenMsgCycleTime" BO_ 1381 500;
BA_ "GenMsgStartDelayTime" BO_ 1381 65;
BA_ "VFrameFormat" BO_ 519 0;
BA_ "GenMsgSendType" BO_ 519 8;
BA_ "VFrameFormat" BO_ 518 0;
BA_ "GenMsgSendType" BO_ 518 8;
BA_ "VFrameFormat" BO_ 1370 0;
BA_ "GenMsgCycleTime" BO_ 1370 500;
BA_ "GenMsgStartDelayTime" BO_ 1370 180;
BA_ "VFrameFormat" BO_ 1373 0;
BA_ "GenMsgCycleTime" BO_ 1373 500;
BA_ "GenMsgStartDelayTime" BO_ 1373 165;
BA_ "VFrameFormat" BO_ 1249 0;
BA_ "GenMsgCycleTime" BO_ 1249 100;
BA_ "GenMsgStartDelayTime" BO_ 1249 70;
BA_ "VFrameFormat" BO_ 944 0;
BA_ "GenMsgCycleTime" BO_ 944 50;
BA_ "GenMsgStartDelayTime" BO_ 944 20;
BA_ "VFrameFormat" BO_ 390 0;
BA_ "GenMsgCycleTime" BO_ 390 10;
BA_ "GenMsgStartDelayTime" BO_ 390 5;
BA_ "VFrameFormat" BO_ 389 0;
BA_ "GenMsgCycleTime" BO_ 389 10;
BA_ "VFrameFormat" BO_ 1364 0;
BA_ "GenMsgCycleTime" BO_ 1364 250;
BA_ "GenMsgStartDelayTime" BO_ 1364 50;
BA_ "VFrameFormat" BO_ 826 0;
BA_ "GenMsgCycleTime" BO_ 826 30;
BA_ "GenMsgStartDelayTime" BO_ 826 5;
BA_ "VFrameFormat" BO_ 1369 0;
BA_ "GenMsgCycleTime" BO_ 1369 500;
BA_ "GenMsgStartDelayTime" BO_ 1369 135;
BA_ "VFrameFormat" BO_ 946 0;
BA_ "GenMsgCycleTime" BO_ 946 50;
BA_ "GenMsgStartDelayTime" BO_ 946 40;
BA_ "GenSigCycleTime" SG_ 1519 WGTrckTPMThresCfg_ExtOverPres 100;
BA_ "GenSigCycleTimeActive" SG_ 1519 WGTrckTPMThresCfg_ExtOverPres 100;
BA_ "GenSigStartValue" SG_ 1519 WGTrckTPMThresCfg_ExtOverPres 255;
BA_ "GenSigCycleTime" SG_ 1519 WGTrckTPMThresCfg_AxleNr 100;
BA_ "GenSigCycleTimeActive" SG_ 1519 WGTrckTPMThresCfg_AxleNr 100;
BA_ "GenSigStartValue" SG_ 1519 WGTrckTPMThresCfg_AxleNr 7;
BA_ "GenSigCycleTime" SG_ 1519 WGTrckTPMThresCfg_ExtUnderPres 100;
BA_ "GenSigCycleTimeActive" SG_ 1519 WGTrckTPMThresCfg_ExtUnderPres 100;
BA_ "GenSigStartValue" SG_ 1519 WGTrckTPMThresCfg_ExtUnderPres 255;
BA_ "GenSigCycleTime" SG_ 1519 WGTrckTPMThresCfg_UnderPres 100;
BA_ "GenSigCycleTimeActive" SG_ 1519 WGTrckTPMThresCfg_UnderPres 100;
BA_ "GenSigStartValue" SG_ 1519 WGTrckTPMThresCfg_UnderPres 255;
BA_ "GenSigCycleTime" SG_ 1519 WGTrckTPMThresCfg_OverPres 100;
BA_ "GenSigCycleTimeActive" SG_ 1519 WGTrckTPMThresCfg_OverPres 100;
BA_ "GenSigStartValue" SG_ 1519 WGTrckTPMThresCfg_OverPres 255;
BA_ "GenSigSendType" SG_ 1513 WSGW_Chassi_10S_FCS 7;
BA_ "GenSigSendType" SG_ 1512 PhyDiagTPM2BrkReqSig_ISig_4 1;
BA_ "GenSigCycleTime" SG_ 1512 PhyDiagTPM2BrkReqSig_ISig_4 100;
BA_ "GenSigCycleTimeActive" SG_ 1512 PhyDiagTPM2BrkReqSig_ISig_4 100;
BA_ "GenSigCycleTime" SG_ 1356 WGTrail5TPMInf_Pressure 100;
BA_ "GenSigCycleTimeActive" SG_ 1356 WGTrail5TPMInf_Pressure 100;
BA_ "GenSigStartValue" SG_ 1356 WGTrail5TPMInf_Pressure 1023;
BA_ "GenSigCycleTime" SG_ 1356 WGTrail5TPMInf_BatteryStatus 100;
BA_ "GenSigCycleTimeActive" SG_ 1356 WGTrail5TPMInf_BatteryStatus 100;
BA_ "GenSigStartValue" SG_ 1356 WGTrail5TPMInf_BatteryStatus 15;
BA_ "GenSigCycleTime" SG_ 1356 WGTrail5TPMInf_TgtPressure 100;
BA_ "GenSigCycleTimeActive" SG_ 1356 WGTrail5TPMInf_TgtPressure 100;
BA_ "GenSigStartValue" SG_ 1356 WGTrail5TPMInf_TgtPressure 1023;
BA_ "GenSigCycleTime" SG_ 1356 WGTrail5TPMInf_Temperature 100;
BA_ "GenSigCycleTimeActive" SG_ 1356 WGTrail5TPMInf_Temperature 100;
BA_ "GenSigStartValue" SG_ 1356 WGTrail5TPMInf_Temperature 255;
BA_ "GenSigCycleTime" SG_ 1356 WGTrail5TPMInf_TemperatureStatus 100;
BA_ "GenSigCycleTimeActive" SG_ 1356 WGTrail5TPMInf_TemperatureStatus 100;
BA_ "GenSigStartValue" SG_ 1356 WGTrail5TPMInf_TemperatureStatus 3;
BA_ "GenSigCycleTime" SG_ 1356 WGTrail5TPMInf_PressureStatus 100;
BA_ "GenSigCycleTimeActive" SG_ 1356 WGTrail5TPMInf_PressureStatus 100;
BA_ "GenSigStartValue" SG_ 1356 WGTrail5TPMInf_PressureStatus 15;
BA_ "GenSigCycleTime" SG_ 1356 WGTrail5TPMInf_FastPressureLoss 100;
BA_ "GenSigCycleTimeActive" SG_ 1356 WGTrail5TPMInf_FastPressureLoss 100;
BA_ "GenSigStartValue" SG_ 1356 WGTrail5TPMInf_FastPressureLoss 3;
BA_ "GenSigCycleTime" SG_ 1356 WGTrail5TPMInf_WheelLocation 100;
BA_ "GenSigCycleTimeActive" SG_ 1356 WGTrail5TPMInf_WheelLocation 100;
BA_ "GenSigStartValue" SG_ 1356 WGTrail5TPMInf_WheelLocation 255;
BA_ "GenSigCycleTime" SG_ 1356 WGTrail5TPMInf_SensorIDProgStat 100;
BA_ "GenSigCycleTimeActive" SG_ 1356 WGTrail5TPMInf_SensorIDProgStat 100;
BA_ "GenSigStartValue" SG_ 1356 WGTrail5TPMInf_SensorIDProgStat 3;
BA_ "GenSigCycleTime" SG_ 1355 WGTrail4TPMInf_Temperature 100;
BA_ "GenSigCycleTimeActive" SG_ 1355 WGTrail4TPMInf_Temperature 100;
BA_ "GenSigStartValue" SG_ 1355 WGTrail4TPMInf_Temperature 255;
BA_ "GenSigCycleTime" SG_ 1355 WGTrail4TPMInf_TemperatureStatus 100;
BA_ "GenSigCycleTimeActive" SG_ 1355 WGTrail4TPMInf_TemperatureStatus 100;
BA_ "GenSigStartValue" SG_ 1355 WGTrail4TPMInf_TemperatureStatus 3;
BA_ "GenSigCycleTime" SG_ 1355 WGTrail4TPMInf_PressureStatus 100;
BA_ "GenSigCycleTimeActive" SG_ 1355 WGTrail4TPMInf_PressureStatus 100;
BA_ "GenSigStartValue" SG_ 1355 WGTrail4TPMInf_PressureStatus 15;
BA_ "GenSigCycleTime" SG_ 1355 WGTrail4TPMInf_Pressure 100;
BA_ "GenSigCycleTimeActive" SG_ 1355 WGTrail4TPMInf_Pressure 100;
BA_ "GenSigStartValue" SG_ 1355 WGTrail4TPMInf_Pressure 1023;
BA_ "GenSigCycleTime" SG_ 1355 WGTrail4TPMInf_BatteryStatus 100;
BA_ "GenSigCycleTimeActive" SG_ 1355 WGTrail4TPMInf_BatteryStatus 100;
BA_ "GenSigStartValue" SG_ 1355 WGTrail4TPMInf_BatteryStatus 15;
BA_ "GenSigCycleTime" SG_ 1355 WGTrail4TPMInf_SensorIDProgStat 100;
BA_ "GenSigCycleTimeActive" SG_ 1355 WGTrail4TPMInf_SensorIDProgStat 100;
BA_ "GenSigStartValue" SG_ 1355 WGTrail4TPMInf_SensorIDProgStat 3;
BA_ "GenSigCycleTime" SG_ 1355 WGTrail4TPMInf_TgtPressure 100;
BA_ "GenSigCycleTimeActive" SG_ 1355 WGTrail4TPMInf_TgtPressure 100;
BA_ "GenSigStartValue" SG_ 1355 WGTrail4TPMInf_TgtPressure 1023;
BA_ "GenSigCycleTime" SG_ 1355 WGTrail4TPMInf_WheelLocation 100;
BA_ "GenSigCycleTimeActive" SG_ 1355 WGTrail4TPMInf_WheelLocation 100;
BA_ "GenSigStartValue" SG_ 1355 WGTrail4TPMInf_WheelLocation 255;
BA_ "GenSigCycleTime" SG_ 1355 WGTrail4TPMInf_FastPressureLoss 100;
BA_ "GenSigCycleTimeActive" SG_ 1355 WGTrail4TPMInf_FastPressureLoss 100;
BA_ "GenSigStartValue" SG_ 1355 WGTrail4TPMInf_FastPressureLoss 3;
BA_ "GenSigCycleTime" SG_ 1354 WGTrail3TPMInf_FastPressureLoss 100;
BA_ "GenSigCycleTimeActive" SG_ 1354 WGTrail3TPMInf_FastPressureLoss 100;
BA_ "GenSigStartValue" SG_ 1354 WGTrail3TPMInf_FastPressureLoss 3;
BA_ "GenSigCycleTime" SG_ 1354 WGTrail3TPMInf_PressureStatus 100;
BA_ "GenSigCycleTimeActive" SG_ 1354 WGTrail3TPMInf_PressureStatus 100;
BA_ "GenSigStartValue" SG_ 1354 WGTrail3TPMInf_PressureStatus 15;
BA_ "GenSigCycleTime" SG_ 1354 WGTrail3TPMInf_SensorIDProgStat 100;
BA_ "GenSigCycleTimeActive" SG_ 1354 WGTrail3TPMInf_SensorIDProgStat 100;
BA_ "GenSigStartValue" SG_ 1354 WGTrail3TPMInf_SensorIDProgStat 3;
BA_ "GenSigCycleTime" SG_ 1354 WGTrail3TPMInf_WheelLocation 100;
BA_ "GenSigCycleTimeActive" SG_ 1354 WGTrail3TPMInf_WheelLocation 100;
BA_ "GenSigStartValue" SG_ 1354 WGTrail3TPMInf_WheelLocation 255;
BA_ "GenSigCycleTime" SG_ 1354 WGTrail3TPMInf_TemperatureStatus 100;
BA_ "GenSigCycleTimeActive" SG_ 1354 WGTrail3TPMInf_TemperatureStatus 100;
BA_ "GenSigStartValue" SG_ 1354 WGTrail3TPMInf_TemperatureStatus 3;
BA_ "GenSigCycleTime" SG_ 1354 WGTrail3TPMInf_Pressure 100;
BA_ "GenSigCycleTimeActive" SG_ 1354 WGTrail3TPMInf_Pressure 100;
BA_ "GenSigStartValue" SG_ 1354 WGTrail3TPMInf_Pressure 1023;
BA_ "GenSigCycleTime" SG_ 1354 WGTrail3TPMInf_BatteryStatus 100;
BA_ "GenSigCycleTimeActive" SG_ 1354 WGTrail3TPMInf_BatteryStatus 100;
BA_ "GenSigStartValue" SG_ 1354 WGTrail3TPMInf_BatteryStatus 15;
BA_ "GenSigCycleTime" SG_ 1354 WGTrail3TPMInf_TgtPressure 100;
BA_ "GenSigCycleTimeActive" SG_ 1354 WGTrail3TPMInf_TgtPressure 100;
BA_ "GenSigStartValue" SG_ 1354 WGTrail3TPMInf_TgtPressure 1023;
BA_ "GenSigCycleTime" SG_ 1354 WGTrail3TPMInf_Temperature 100;
BA_ "GenSigCycleTimeActive" SG_ 1354 WGTrail3TPMInf_Temperature 100;
BA_ "GenSigStartValue" SG_ 1354 WGTrail3TPMInf_Temperature 255;
BA_ "GenSigCycleTime" SG_ 1337 WGTrail2TPMInf_Pressure 100;
BA_ "GenSigCycleTimeActive" SG_ 1337 WGTrail2TPMInf_Pressure 100;
BA_ "GenSigStartValue" SG_ 1337 WGTrail2TPMInf_Pressure 1023;
BA_ "GenSigCycleTime" SG_ 1337 WGTrail2TPMInf_WheelLocation 100;
BA_ "GenSigCycleTimeActive" SG_ 1337 WGTrail2TPMInf_WheelLocation 100;
BA_ "GenSigStartValue" SG_ 1337 WGTrail2TPMInf_WheelLocation 255;
BA_ "GenSigCycleTime" SG_ 1337 WGTrail2TPMInf_TgtPressure 100;
BA_ "GenSigCycleTimeActive" SG_ 1337 WGTrail2TPMInf_TgtPressure 100;
BA_ "GenSigStartValue" SG_ 1337 WGTrail2TPMInf_TgtPressure 1023;
BA_ "GenSigCycleTime" SG_ 1337 WGTrail2TPMInf_Temperature 100;
BA_ "GenSigCycleTimeActive" SG_ 1337 WGTrail2TPMInf_Temperature 100;
BA_ "GenSigStartValue" SG_ 1337 WGTrail2TPMInf_Temperature 255;
BA_ "GenSigCycleTime" SG_ 1337 WGTrail2TPMInf_PressureStatus 100;
BA_ "GenSigCycleTimeActive" SG_ 1337 WGTrail2TPMInf_PressureStatus 100;
BA_ "GenSigStartValue" SG_ 1337 WGTrail2TPMInf_PressureStatus 15;
BA_ "GenSigCycleTime" SG_ 1337 WGTrail2TPMInf_FastPressureLoss 100;
BA_ "GenSigCycleTimeActive" SG_ 1337 WGTrail2TPMInf_FastPressureLoss 100;
BA_ "GenSigStartValue" SG_ 1337 WGTrail2TPMInf_FastPressureLoss 3;
BA_ "GenSigCycleTime" SG_ 1337 WGTrail2TPMInf_SensorIDProgStat 100;
BA_ "GenSigCycleTimeActive" SG_ 1337 WGTrail2TPMInf_SensorIDProgStat 100;
BA_ "GenSigStartValue" SG_ 1337 WGTrail2TPMInf_SensorIDProgStat 3;
BA_ "GenSigCycleTime" SG_ 1337 WGTrail2TPMInf_TemperatureStatus 100;
BA_ "GenSigCycleTimeActive" SG_ 1337 WGTrail2TPMInf_TemperatureStatus 100;
BA_ "GenSigStartValue" SG_ 1337 WGTrail2TPMInf_TemperatureStatus 3;
BA_ "GenSigCycleTime" SG_ 1337 WGTrail2TPMInf_BatteryStatus 100;
BA_ "GenSigCycleTimeActive" SG_ 1337 WGTrail2TPMInf_BatteryStatus 100;
BA_ "GenSigStartValue" SG_ 1337 WGTrail2TPMInf_BatteryStatus 15;
BA_ "GenSigCycleTime" SG_ 1336 WGTrail1TPMInf_BatteryStatus 100;
BA_ "GenSigCycleTimeActive" SG_ 1336 WGTrail1TPMInf_BatteryStatus 100;
BA_ "GenSigStartValue" SG_ 1336 WGTrail1TPMInf_BatteryStatus 15;
BA_ "GenSigCycleTime" SG_ 1336 WGTrail1TPMInf_WheelLocation 100;
BA_ "GenSigCycleTimeActive" SG_ 1336 WGTrail1TPMInf_WheelLocation 100;
BA_ "GenSigStartValue" SG_ 1336 WGTrail1TPMInf_WheelLocation 255;
BA_ "GenSigCycleTime" SG_ 1336 WGTrail1TPMInf_Pressure 100;
BA_ "GenSigCycleTimeActive" SG_ 1336 WGTrail1TPMInf_Pressure 100;
BA_ "GenSigStartValue" SG_ 1336 WGTrail1TPMInf_Pressure 1023;
BA_ "GenSigCycleTime" SG_ 1336 WGTrail1TPMInf_Temperature 100;
BA_ "GenSigCycleTimeActive" SG_ 1336 WGTrail1TPMInf_Temperature 100;
BA_ "GenSigStartValue" SG_ 1336 WGTrail1TPMInf_Temperature 255;
BA_ "GenSigCycleTime" SG_ 1336 WGTrail1TPMInf_TemperatureStatus 100;
BA_ "GenSigCycleTimeActive" SG_ 1336 WGTrail1TPMInf_TemperatureStatus 100;
BA_ "GenSigStartValue" SG_ 1336 WGTrail1TPMInf_TemperatureStatus 3;
BA_ "GenSigCycleTime" SG_ 1336 WGTrail1TPMInf_TgtPressure 100;
BA_ "GenSigCycleTimeActive" SG_ 1336 WGTrail1TPMInf_TgtPressure 100;
BA_ "GenSigStartValue" SG_ 1336 WGTrail1TPMInf_TgtPressure 1023;
BA_ "GenSigCycleTime" SG_ 1336 WGTrail1TPMInf_SensorIDProgStat 100;
BA_ "GenSigCycleTimeActive" SG_ 1336 WGTrail1TPMInf_SensorIDProgStat 100;
BA_ "GenSigStartValue" SG_ 1336 WGTrail1TPMInf_SensorIDProgStat 3;
BA_ "GenSigCycleTime" SG_ 1336 WGTrail1TPMInf_PressureStatus 100;
BA_ "GenSigCycleTimeActive" SG_ 1336 WGTrail1TPMInf_PressureStatus 100;
BA_ "GenSigStartValue" SG_ 1336 WGTrail1TPMInf_PressureStatus 15;
BA_ "GenSigCycleTime" SG_ 1336 WGTrail1TPMInf_FastPressureLoss 100;
BA_ "GenSigCycleTimeActive" SG_ 1336 WGTrail1TPMInf_FastPressureLoss 100;
BA_ "GenSigStartValue" SG_ 1336 WGTrail1TPMInf_FastPressureLoss 3;
BA_ "GenSigCycleTime" SG_ 1283 WGTPMPosOfWMResp_VehiclePos 100;
BA_ "GenSigCycleTimeActive" SG_ 1283 WGTPMPosOfWMResp_VehiclePos 100;
BA_ "GenSigStartValue" SG_ 1283 WGTPMPosOfWMResp_VehiclePos 7;
BA_ "GenSigCycleTime" SG_ 1283 WGTrailer4TPMLostCom 100;
BA_ "GenSigCycleTimeActive" SG_ 1283 WGTrailer4TPMLostCom 100;
BA_ "GenSigStartValue" SG_ 1283 WGTrailer4TPMLostCom 3;
BA_ "GenSigCycleTime" SG_ 1283 WGTruckTPMFailure 100;
BA_ "GenSigCycleTimeActive" SG_ 1283 WGTruckTPMFailure 100;
BA_ "GenSigStartValue" SG_ 1283 WGTruckTPMFailure 3;
BA_ "GenSigCycleTime" SG_ 1283 WGTrailer5TPMLostCom 100;
BA_ "GenSigCycleTimeActive" SG_ 1283 WGTrailer5TPMLostCom 100;
BA_ "GenSigStartValue" SG_ 1283 WGTrailer5TPMLostCom 3;
BA_ "GenSigCycleTime" SG_ 1283 WGTrlr1TPMMatedStatus 100;
BA_ "GenSigCycleTimeActive" SG_ 1283 WGTrlr1TPMMatedStatus 100;
BA_ "GenSigStartValue" SG_ 1283 WGTrlr1TPMMatedStatus 3;
BA_ "GenSigCycleTime" SG_ 1283 WGTrailer5TPMFailure 100;
BA_ "GenSigCycleTimeActive" SG_ 1283 WGTrailer5TPMFailure 100;
BA_ "GenSigStartValue" SG_ 1283 WGTrailer5TPMFailure 3;
BA_ "GenSigCycleTime" SG_ 1283 WGTrlr5TPMMatedStatus 100;
BA_ "GenSigCycleTimeActive" SG_ 1283 WGTrlr5TPMMatedStatus 100;
BA_ "GenSigStartValue" SG_ 1283 WGTrlr5TPMMatedStatus 3;
BA_ "GenSigCycleTime" SG_ 1283 WGTrailer1TPMLostCom 100;
BA_ "GenSigCycleTimeActive" SG_ 1283 WGTrailer1TPMLostCom 100;
BA_ "GenSigStartValue" SG_ 1283 WGTrailer1TPMLostCom 3;
BA_ "GenSigCycleTime" SG_ 1283 WGTrailer1TPMFailure 100;
BA_ "GenSigCycleTimeActive" SG_ 1283 WGTrailer1TPMFailure 100;
BA_ "GenSigStartValue" SG_ 1283 WGTrailer1TPMFailure 3;
BA_ "GenSigCycleTime" SG_ 1283 WGTrailer2TPMFailure 100;
BA_ "GenSigCycleTimeActive" SG_ 1283 WGTrailer2TPMFailure 100;
BA_ "GenSigStartValue" SG_ 1283 WGTrailer2TPMFailure 3;
BA_ "GenSigCycleTime" SG_ 1283 WGTrailer4TPMFailure 100;
BA_ "GenSigCycleTimeActive" SG_ 1283 WGTrailer4TPMFailure 100;
BA_ "GenSigStartValue" SG_ 1283 WGTrailer4TPMFailure 3;
BA_ "GenSigCycleTime" SG_ 1283 WGTrailer2TPMLostCom 100;
BA_ "GenSigCycleTimeActive" SG_ 1283 WGTrailer2TPMLostCom 100;
BA_ "GenSigStartValue" SG_ 1283 WGTrailer2TPMLostCom 3;
BA_ "GenSigCycleTime" SG_ 1283 WGTrailer3TPMFailure 100;
BA_ "GenSigCycleTimeActive" SG_ 1283 WGTrailer3TPMFailure 100;
BA_ "GenSigStartValue" SG_ 1283 WGTrailer3TPMFailure 3;
BA_ "GenSigCycleTime" SG_ 1283 WGTrlr3TPMMatedStatus 100;
BA_ "GenSigCycleTimeActive" SG_ 1283 WGTrlr3TPMMatedStatus 100;
BA_ "GenSigStartValue" SG_ 1283 WGTrlr3TPMMatedStatus 3;
BA_ "GenSigCycleTime" SG_ 1283 WGTPMPosOfWMResp_TireId 100;
BA_ "GenSigCycleTimeActive" SG_ 1283 WGTPMPosOfWMResp_TireId 100;
BA_ "GenSigCycleTime" SG_ 1283 WGTrailer3TPMLostCom 100;
BA_ "GenSigCycleTimeActive" SG_ 1283 WGTrailer3TPMLostCom 100;
BA_ "GenSigStartValue" SG_ 1283 WGTrailer3TPMLostCom 3;
BA_ "GenSigCycleTime" SG_ 1283 WGTrlr4TPMMatedStatus 100;
BA_ "GenSigCycleTimeActive" SG_ 1283 WGTrlr4TPMMatedStatus 100;
BA_ "GenSigStartValue" SG_ 1283 WGTrlr4TPMMatedStatus 3;
BA_ "GenSigCycleTime" SG_ 1283 WGTrlr2TPMMatedStatus 100;
BA_ "GenSigCycleTimeActive" SG_ 1283 WGTrlr2TPMMatedStatus 100;
BA_ "GenSigStartValue" SG_ 1283 WGTrlr2TPMMatedStatus 3;
BA_ "GenSigCycleTime" SG_ 1283 WGTPMPosOfWMResp_Status 100;
BA_ "GenSigCycleTimeActive" SG_ 1283 WGTPMPosOfWMResp_Status 100;
BA_ "GenSigStartValue" SG_ 1283 WGTPMPosOfWMResp_Status 7;
BA_ "GenSigCycleTime" SG_ 1518 Trail5WGTPMAxlTireCfg_Axle2 100;
BA_ "GenSigCycleTimeActive" SG_ 1518 Trail5WGTPMAxlTireCfg_Axle2 100;
BA_ "GenSigStartValue" SG_ 1518 Trail5WGTPMAxlTireCfg_Axle2 7;
BA_ "GenSigCycleTime" SG_ 1518 Trail5WGTPMAxlTireCfg_Axle3 100;
BA_ "GenSigCycleTimeActive" SG_ 1518 Trail5WGTPMAxlTireCfg_Axle3 100;
BA_ "GenSigStartValue" SG_ 1518 Trail5WGTPMAxlTireCfg_Axle3 7;
BA_ "GenSigCycleTime" SG_ 1518 Trail4WGTPMAxlTireCfg_Axle2 100;
BA_ "GenSigCycleTimeActive" SG_ 1518 Trail4WGTPMAxlTireCfg_Axle2 100;
BA_ "GenSigStartValue" SG_ 1518 Trail4WGTPMAxlTireCfg_Axle2 7;
BA_ "GenSigCycleTime" SG_ 1518 Trail4WGTPMAxlTireCfg_Axle3 100;
BA_ "GenSigCycleTimeActive" SG_ 1518 Trail4WGTPMAxlTireCfg_Axle3 100;
BA_ "GenSigStartValue" SG_ 1518 Trail4WGTPMAxlTireCfg_Axle3 7;
BA_ "GenSigCycleTime" SG_ 1518 Trail4WGTPMAxlTireCfg_Axle5 100;
BA_ "GenSigCycleTimeActive" SG_ 1518 Trail4WGTPMAxlTireCfg_Axle5 100;
BA_ "GenSigStartValue" SG_ 1518 Trail4WGTPMAxlTireCfg_Axle5 7;
BA_ "GenSigCycleTime" SG_ 1518 Trail5WGTPMAxlTireCfg_Axle4 100;
BA_ "GenSigCycleTimeActive" SG_ 1518 Trail5WGTPMAxlTireCfg_Axle4 100;
BA_ "GenSigStartValue" SG_ 1518 Trail5WGTPMAxlTireCfg_Axle4 7;
BA_ "GenSigCycleTime" SG_ 1518 Trail4WGTPMAxlTireCfg_Axle4 100;
BA_ "GenSigCycleTimeActive" SG_ 1518 Trail4WGTPMAxlTireCfg_Axle4 100;
BA_ "GenSigStartValue" SG_ 1518 Trail4WGTPMAxlTireCfg_Axle4 7;
BA_ "GenSigCycleTime" SG_ 1518 Trail5WGTPMAxlTireCfg_Axle5 100;
BA_ "GenSigCycleTimeActive" SG_ 1518 Trail5WGTPMAxlTireCfg_Axle5 100;
BA_ "GenSigStartValue" SG_ 1518 Trail5WGTPMAxlTireCfg_Axle5 7;
BA_ "GenSigCycleTime" SG_ 1518 Trail4WGTPMAxlTireCfg_Axle1 100;
BA_ "GenSigCycleTimeActive" SG_ 1518 Trail4WGTPMAxlTireCfg_Axle1 100;
BA_ "GenSigStartValue" SG_ 1518 Trail4WGTPMAxlTireCfg_Axle1 7;
BA_ "GenSigCycleTime" SG_ 1518 Trail5WGTPMAxlTireCfg_Axle1 100;
BA_ "GenSigCycleTimeActive" SG_ 1518 Trail5WGTPMAxlTireCfg_Axle1 100;
BA_ "GenSigStartValue" SG_ 1518 Trail5WGTPMAxlTireCfg_Axle1 7;
BA_ "GenSigCycleTime" SG_ 1520 WGTruckTPMAxlTireCfg_Axle5 100;
BA_ "GenSigCycleTimeActive" SG_ 1520 WGTruckTPMAxlTireCfg_Axle5 100;
BA_ "GenSigStartValue" SG_ 1520 WGTruckTPMAxlTireCfg_Axle5 7;
BA_ "GenSigCycleTime" SG_ 1520 Trail3WGTPMAxlTireCfg_Axle2 100;
BA_ "GenSigCycleTimeActive" SG_ 1520 Trail3WGTPMAxlTireCfg_Axle2 100;
BA_ "GenSigStartValue" SG_ 1520 Trail3WGTPMAxlTireCfg_Axle2 7;
BA_ "GenSigCycleTime" SG_ 1520 WGTruckTPMAxlTireCfg_Axle4 100;
BA_ "GenSigCycleTimeActive" SG_ 1520 WGTruckTPMAxlTireCfg_Axle4 100;
BA_ "GenSigStartValue" SG_ 1520 WGTruckTPMAxlTireCfg_Axle4 7;
BA_ "GenSigCycleTime" SG_ 1520 WGTruckTPMAxlTireCfg_Axle3 100;
BA_ "GenSigCycleTimeActive" SG_ 1520 WGTruckTPMAxlTireCfg_Axle3 100;
BA_ "GenSigStartValue" SG_ 1520 WGTruckTPMAxlTireCfg_Axle3 7;
BA_ "GenSigCycleTime" SG_ 1520 Trail3WGTPMAxlTireCfg_Axle3 100;
BA_ "GenSigCycleTimeActive" SG_ 1520 Trail3WGTPMAxlTireCfg_Axle3 100;
BA_ "GenSigStartValue" SG_ 1520 Trail3WGTPMAxlTireCfg_Axle3 7;
BA_ "GenSigCycleTime" SG_ 1520 Trail1WGTPMAxlTireCfg_Axle4 100;
BA_ "GenSigCycleTimeActive" SG_ 1520 Trail1WGTPMAxlTireCfg_Axle4 100;
BA_ "GenSigStartValue" SG_ 1520 Trail1WGTPMAxlTireCfg_Axle4 7;
BA_ "GenSigCycleTime" SG_ 1520 WGTruckTPMAxlTireCfg_Axle2 100;
BA_ "GenSigCycleTimeActive" SG_ 1520 WGTruckTPMAxlTireCfg_Axle2 100;
BA_ "GenSigStartValue" SG_ 1520 WGTruckTPMAxlTireCfg_Axle2 7;
BA_ "GenSigCycleTime" SG_ 1520 Trail2WGTPMAxlTireCfg_Axle3 100;
BA_ "GenSigCycleTimeActive" SG_ 1520 Trail2WGTPMAxlTireCfg_Axle3 100;
BA_ "GenSigStartValue" SG_ 1520 Trail2WGTPMAxlTireCfg_Axle3 7;
BA_ "GenSigCycleTime" SG_ 1520 Trail3WGTPMAxlTireCfg_Axle1 100;
BA_ "GenSigCycleTimeActive" SG_ 1520 Trail3WGTPMAxlTireCfg_Axle1 100;
BA_ "GenSigStartValue" SG_ 1520 Trail3WGTPMAxlTireCfg_Axle1 7;
BA_ "GenSigCycleTime" SG_ 1520 Trail2WGTPMAxlTireCfg_Axle2 100;
BA_ "GenSigCycleTimeActive" SG_ 1520 Trail2WGTPMAxlTireCfg_Axle2 100;
BA_ "GenSigStartValue" SG_ 1520 Trail2WGTPMAxlTireCfg_Axle2 7;
BA_ "GenSigCycleTime" SG_ 1520 Trail1WGTPMAxlTireCfg_Axle1 100;
BA_ "GenSigCycleTimeActive" SG_ 1520 Trail1WGTPMAxlTireCfg_Axle1 100;
BA_ "GenSigStartValue" SG_ 1520 Trail1WGTPMAxlTireCfg_Axle1 7;
BA_ "GenSigCycleTime" SG_ 1520 Trail1WGTPMAxlTireCfg_Axle5 100;
BA_ "GenSigCycleTimeActive" SG_ 1520 Trail1WGTPMAxlTireCfg_Axle5 100;
BA_ "GenSigStartValue" SG_ 1520 Trail1WGTPMAxlTireCfg_Axle5 7;
BA_ "GenSigCycleTime" SG_ 1520 Trail3WGTPMAxlTireCfg_Axle4 100;
BA_ "GenSigCycleTimeActive" SG_ 1520 Trail3WGTPMAxlTireCfg_Axle4 100;
BA_ "GenSigStartValue" SG_ 1520 Trail3WGTPMAxlTireCfg_Axle4 7;
BA_ "GenSigCycleTime" SG_ 1520 Trail2WGTPMAxlTireCfg_Axle5 100;
BA_ "GenSigCycleTimeActive" SG_ 1520 Trail2WGTPMAxlTireCfg_Axle5 100;
BA_ "GenSigStartValue" SG_ 1520 Trail2WGTPMAxlTireCfg_Axle5 7;
BA_ "GenSigCycleTime" SG_ 1520 Trail1WGTPMAxlTireCfg_Axle3 100;
BA_ "GenSigCycleTimeActive" SG_ 1520 Trail1WGTPMAxlTireCfg_Axle3 100;
BA_ "GenSigStartValue" SG_ 1520 Trail1WGTPMAxlTireCfg_Axle3 7;
BA_ "GenSigCycleTime" SG_ 1520 WGTruckTPMAxlTireCfg_Axle1 100;
BA_ "GenSigCycleTimeActive" SG_ 1520 WGTruckTPMAxlTireCfg_Axle1 100;
BA_ "GenSigStartValue" SG_ 1520 WGTruckTPMAxlTireCfg_Axle1 7;
BA_ "GenSigCycleTime" SG_ 1520 Trail2WGTPMAxlTireCfg_Axle1 100;
BA_ "GenSigCycleTimeActive" SG_ 1520 Trail2WGTPMAxlTireCfg_Axle1 100;
BA_ "GenSigStartValue" SG_ 1520 Trail2WGTPMAxlTireCfg_Axle1 7;
BA_ "GenSigCycleTime" SG_ 1520 Trail2WGTPMAxlTireCfg_Axle4 100;
BA_ "GenSigCycleTimeActive" SG_ 1520 Trail2WGTPMAxlTireCfg_Axle4 100;
BA_ "GenSigStartValue" SG_ 1520 Trail2WGTPMAxlTireCfg_Axle4 7;
BA_ "GenSigCycleTime" SG_ 1520 Trail3WGTPMAxlTireCfg_Axle5 100;
BA_ "GenSigCycleTimeActive" SG_ 1520 Trail3WGTPMAxlTireCfg_Axle5 100;
BA_ "GenSigStartValue" SG_ 1520 Trail3WGTPMAxlTireCfg_Axle5 7;
BA_ "GenSigCycleTime" SG_ 1520 Trail1WGTPMAxlTireCfg_Axle2 100;
BA_ "GenSigCycleTimeActive" SG_ 1520 Trail1WGTPMAxlTireCfg_Axle2 100;
BA_ "GenSigStartValue" SG_ 1520 Trail1WGTPMAxlTireCfg_Axle2 7;
BA_ "GenSigCycleTime" SG_ 1335 WGTruckTPMInfo_TgtPressure 100;
BA_ "GenSigCycleTimeActive" SG_ 1335 WGTruckTPMInfo_TgtPressure 100;
BA_ "GenSigStartValue" SG_ 1335 WGTruckTPMInfo_TgtPressure 1023;
BA_ "GenSigCycleTime" SG_ 1335 WGTruckTPMInfo_Temperature 100;
BA_ "GenSigCycleTimeActive" SG_ 1335 WGTruckTPMInfo_Temperature 100;
BA_ "GenSigStartValue" SG_ 1335 WGTruckTPMInfo_Temperature 255;
BA_ "GenSigCycleTime" SG_ 1335 WGTruckTPMInfo_WheelLocation 100;
BA_ "GenSigCycleTimeActive" SG_ 1335 WGTruckTPMInfo_WheelLocation 100;
BA_ "GenSigStartValue" SG_ 1335 WGTruckTPMInfo_WheelLocation 255;
BA_ "GenSigCycleTime" SG_ 1335 WGTruckTPMInfo_Pressure 100;
BA_ "GenSigCycleTimeActive" SG_ 1335 WGTruckTPMInfo_Pressure 100;
BA_ "GenSigStartValue" SG_ 1335 WGTruckTPMInfo_Pressure 1023;
BA_ "GenSigCycleTime" SG_ 1335 WGTruckTPMInfo_TemperatureStatus 100;
BA_ "GenSigCycleTimeActive" SG_ 1335 WGTruckTPMInfo_TemperatureStatus 100;
BA_ "GenSigStartValue" SG_ 1335 WGTruckTPMInfo_TemperatureStatus 3;
BA_ "GenSigCycleTime" SG_ 1335 WGTruckTPMInfo_FastPressureLoss 100;
BA_ "GenSigCycleTimeActive" SG_ 1335 WGTruckTPMInfo_FastPressureLoss 100;
BA_ "GenSigStartValue" SG_ 1335 WGTruckTPMInfo_FastPressureLoss 3;
BA_ "GenSigCycleTime" SG_ 1335 WGTruckTPMInfo_PressureStatus 100;
BA_ "GenSigCycleTimeActive" SG_ 1335 WGTruckTPMInfo_PressureStatus 100;
BA_ "GenSigStartValue" SG_ 1335 WGTruckTPMInfo_PressureStatus 15;
BA_ "GenSigCycleTime" SG_ 1335 WGTruckTPMInfo_SensorIDProgStat 100;
BA_ "GenSigCycleTimeActive" SG_ 1335 WGTruckTPMInfo_SensorIDProgStat 100;
BA_ "GenSigStartValue" SG_ 1335 WGTruckTPMInfo_SensorIDProgStat 3;
BA_ "GenSigCycleTime" SG_ 1335 WGTruckTPMInfo_BatteryStatus 100;
BA_ "GenSigCycleTimeActive" SG_ 1335 WGTruckTPMInfo_BatteryStatus 100;
BA_ "GenSigStartValue" SG_ 1335 WGTruckTPMInfo_BatteryStatus 15;
BA_ "GenSigCycleTime" SG_ 1361 Set_LG6CutoffValue_ISig_4 100;
BA_ "GenSigCycleTimeActive" SG_ 1361 Set_LG6CutoffValue_ISig_4 100;
BA_ "GenSigStartValue" SG_ 1361 Set_LG6CutoffValue_ISig_4 255;
BA_ "Platform_Vivis2_Sig" SG_ 1361 Set_LG6CutoffValue_ISig_4 1;
BA_ "GenSigCycleTime" SG_ 1361 Set_LG1CutoffValue_ISig_4 100;
BA_ "GenSigCycleTimeActive" SG_ 1361 Set_LG1CutoffValue_ISig_4 100;
BA_ "GenSigStartValue" SG_ 1361 Set_LG1CutoffValue_ISig_4 255;
BA_ "Platform_Vivis2_Sig" SG_ 1361 Set_LG1CutoffValue_ISig_4 1;
BA_ "GenSigCycleTime" SG_ 1361 Set_LG3CutoffValue_ISig_4 100;
BA_ "GenSigCycleTimeActive" SG_ 1361 Set_LG3CutoffValue_ISig_4 100;
BA_ "GenSigStartValue" SG_ 1361 Set_LG3CutoffValue_ISig_4 255;
BA_ "Platform_Vivis2_Sig" SG_ 1361 Set_LG3CutoffValue_ISig_4 1;
BA_ "GenSigCycleTime" SG_ 1361 Set_LG5CutoffValue_ISig_4 100;
BA_ "GenSigCycleTimeActive" SG_ 1361 Set_LG5CutoffValue_ISig_4 100;
BA_ "GenSigStartValue" SG_ 1361 Set_LG5CutoffValue_ISig_4 255;
BA_ "Platform_Vivis2_Sig" SG_ 1361 Set_LG5CutoffValue_ISig_4 1;
BA_ "GenSigCycleTime" SG_ 1361 Set_LG4CutoffValue_ISig_4 100;
BA_ "GenSigCycleTimeActive" SG_ 1361 Set_LG4CutoffValue_ISig_4 100;
BA_ "GenSigStartValue" SG_ 1361 Set_LG4CutoffValue_ISig_4 255;
BA_ "Platform_Vivis2_Sig" SG_ 1361 Set_LG4CutoffValue_ISig_4 1;
BA_ "GenSigCycleTime" SG_ 1361 Set_LG2CutoffValue_ISig_4 100;
BA_ "GenSigCycleTimeActive" SG_ 1361 Set_LG2CutoffValue_ISig_4 100;
BA_ "GenSigStartValue" SG_ 1361 Set_LG2CutoffValue_ISig_4 255;
BA_ "Platform_Vivis2_Sig" SG_ 1361 Set_LG2CutoffValue_ISig_4 1;
BA_ "GenSigCycleTime" SG_ 1361 Set_EnergySetting_ISig_4 100;
BA_ "GenSigCycleTimeActive" SG_ 1361 Set_EnergySetting_ISig_4 100;
BA_ "GenSigStartValue" SG_ 1361 Set_EnergySetting_ISig_4 7;
BA_ "Platform_Vivis2_Sig" SG_ 1361 Set_EnergySetting_ISig_4 1;
BA_ "GenSigCycleTime" SG_ 1267 KingPinUnlockCmd_CRC 100;
BA_ "GenSigCycleTimeActive" SG_ 1267 KingPinUnlockCmd_CRC 100;
BA_ "Platform_Vivis2_Sig" SG_ 1267 KingPinUnlockCmd_CRC 1;
BA_ "E2EDataId" SG_ 1267 KingPinUnlockCmd_CRC 179;
BA_ "E2EDataLength" SG_ 1267 KingPinUnlockCmd_CRC 16;
BA_ "E2EProfile" SG_ 1267 KingPinUnlockCmd_CRC "P01";
BA_ "GenSigCycleTime" SG_ 1267 AirIntakeSolenoidValve_cmd 100;
BA_ "GenSigCycleTimeActive" SG_ 1267 AirIntakeSolenoidValve_cmd 100;
BA_ "GenSigStartValue" SG_ 1267 AirIntakeSolenoidValve_cmd 3;
BA_ "Platform_Vivis2_Sig" SG_ 1267 AirIntakeSolenoidValve_cmd 1;
BA_ "GenSigCycleTime" SG_ 1267 TransmissionActualGearRatio_ISig 100;
BA_ "GenSigCycleTimeActive" SG_ 1267 TransmissionActualGearRatio_ISig 100;
BA_ "GenSigStartValue" SG_ 1267 TransmissionActualGearRatio_ISig 65535;
BA_ "Platform_Vivis2_Sig" SG_ 1267 TransmissionActualGearRatio_ISig 1;
BA_ "SystemSignalLongSymbol" SG_ 1267 TransmissionActualGearRatio_ISig "TransmissionActualGearRatio_ISig_4";
BA_ "GenSigCycleTime" SG_ 1267 KingPinUnlockCmd_SqC 100;
BA_ "GenSigCycleTimeActive" SG_ 1267 KingPinUnlockCmd_SqC 100;
BA_ "Platform_Vivis2_Sig" SG_ 1267 KingPinUnlockCmd_SqC 1;
BA_ "GenSigCycleTime" SG_ 1267 KingPinUnlockCmd_Rqst 100;
BA_ "GenSigCycleTimeActive" SG_ 1267 KingPinUnlockCmd_Rqst 100;
BA_ "GenSigStartValue" SG_ 1267 KingPinUnlockCmd_Rqst 3;
BA_ "Platform_Vivis2_Sig" SG_ 1267 KingPinUnlockCmd_Rqst 1;
BA_ "GenSigCycleTime" SG_ 1267 PreventECSFuncForSWDL_rqst 100;
BA_ "GenSigCycleTimeActive" SG_ 1267 PreventECSFuncForSWDL_rqst 100;
BA_ "GenSigStartValue" SG_ 1267 PreventECSFuncForSWDL_rqst 3;
BA_ "Platform_Vivis2_Sig" SG_ 1267 PreventECSFuncForSWDL_rqst 1;
BA_ "GenSigCycleTime" SG_ 1267 AutoShutOffAnswerInput_ISig_4 100;
BA_ "GenSigCycleTimeActive" SG_ 1267 AutoShutOffAnswerInput_ISig_4 100;
BA_ "GenSigStartValue" SG_ 1267 AutoShutOffAnswerInput_ISig_4 7;
BA_ "Platform_Vivis2_Sig" SG_ 1267 AutoShutOffAnswerInput_ISig_4 1;
BA_ "GenSigCycleTime" SG_ 954 DumpSwitchChangeReq_ISig_4 100;
BA_ "GenSigCycleTimeActive" SG_ 954 DumpSwitchChangeReq_ISig_4 100;
BA_ "GenSigStartValue" SG_ 954 DumpSwitchChangeReq_ISig_4 3;
BA_ "Platform_Vivis2_Sig" SG_ 954 DumpSwitchChangeReq_ISig_4 1;
BA_ "GenSigCycleTime" SG_ 954 LCP_Status_ISig_4 100;
BA_ "GenSigCycleTimeActive" SG_ 954 LCP_Status_ISig_4 100;
BA_ "GenSigStartValue" SG_ 954 LCP_Status_ISig_4 7;
BA_ "GenSigCycleTime" SG_ 954 CAHighBeamFlash_cmd 100;
BA_ "GenSigCycleTimeActive" SG_ 954 CAHighBeamFlash_cmd 100;
BA_ "GenSigStartValue" SG_ 954 CAHighBeamFlash_cmd 3;
BA_ "Platform_Vivis2_Sig" SG_ 954 CAHighBeamFlash_cmd 1;
BA_ "GenSigCycleTime" SG_ 954 PTI_DRL_cmd 100;
BA_ "GenSigCycleTimeActive" SG_ 954 PTI_DRL_cmd 100;
BA_ "GenSigStartValue" SG_ 954 PTI_DRL_cmd 3;
BA_ "GenSigCycleTime" SG_ 954 HeadLampDeicingControl_rqst 100;
BA_ "GenSigCycleTimeActive" SG_ 954 HeadLampDeicingControl_rqst 100;
BA_ "GenSigStartValue" SG_ 954 HeadLampDeicingControl_rqst 3;
BA_ "Platform_Vivis2_Sig" SG_ 954 HeadLampDeicingControl_rqst 1;
BA_ "GenSigCycleTime" SG_ 677 EngineStarterMode_ISig_4 100;
BA_ "GenSigCycleTimeActive" SG_ 677 EngineStarterMode_ISig_4 100;
BA_ "GenSigStartValue" SG_ 677 EngineStarterMode_ISig_4 15;
BA_ "GenSigMaxLatency" SG_ 677 EngineStarterMode_ISig_4 20;
BA_ "Platform_Vivis2_Sig" SG_ 677 EngineStarterMode_ISig_4 1;
BA_ "GenSigCycleTime" SG_ 1363 PredeliveryModeIndication_cmd_IS 100;
BA_ "GenSigCycleTimeActive" SG_ 1363 PredeliveryModeIndication_cmd_IS 100;
BA_ "GenSigStartValue" SG_ 1363 PredeliveryModeIndication_cmd_IS 3;
BA_ "Platform_Vivis2_Sig" SG_ 1363 PredeliveryModeIndication_cmd_IS 1;
BA_ "SystemSignalLongSymbol" SG_ 1363 PredeliveryModeIndication_cmd_IS "PredeliveryModeIndication_cmd_ISig_4";
BA_ "GenSigCycleTime" SG_ 535 DirectionIndicatorLightsStatus_I 100;
BA_ "GenSigCycleTimeActive" SG_ 535 DirectionIndicatorLightsStatus_I 100;
BA_ "GenSigStartValue" SG_ 535 DirectionIndicatorLightsStatus_I 15;
BA_ "GenSigMaxLatency" SG_ 535 DirectionIndicatorLightsStatus_I 25;
BA_ "Platform_Vivis2_Sig" SG_ 535 DirectionIndicatorLightsStatus_I 1;
BA_ "SystemSignalLongSymbol" SG_ 535 DirectionIndicatorLightsStatus_I "DirectionIndicatorLightsStatus_ISig_4";
BA_ "GenSigCycleTime" SG_ 535 HeadlightAngle_cmd 100;
BA_ "GenSigCycleTimeActive" SG_ 535 HeadlightAngle_cmd 100;
BA_ "GenSigStartValue" SG_ 535 HeadlightAngle_cmd 255;
BA_ "Platform_Vivis2_Sig" SG_ 535 HeadlightAngle_cmd 1;
BA_ "GenSigCycleTime" SG_ 1381 BattEnergySetLevel_input_ISig_4 100;
BA_ "GenSigCycleTimeActive" SG_ 1381 BattEnergySetLevel_input_ISig_4 100;
BA_ "GenSigStartValue" SG_ 1381 BattEnergySetLevel_input_ISig_4 7;
BA_ "Platform_Vivis2_Sig" SG_ 1381 BattEnergySetLevel_input_ISig_4 1;
BA_ "GenSigCycleTime" SG_ 1381 AmbientAirTemperature_ISig_4 100;
BA_ "GenSigCycleTimeActive" SG_ 1381 AmbientAirTemperature_ISig_4 100;
BA_ "GenSigStartValue" SG_ 1381 AmbientAirTemperature_ISig_4 65535;
BA_ "GenSigMaxLatency" SG_ 1381 AmbientAirTemperature_ISig_4 59;
BA_ "Platform_VMCU1_Sig" SG_ 1381 AmbientAirTemperature_ISig_4 1;
BA_ "Platform_Vivis2_Sig" SG_ 1381 AmbientAirTemperature_ISig_4 1;
BA_ "GenSigCycleTime" SG_ 1381 EnergyForNextCrank_ISig_4 100;
BA_ "GenSigCycleTimeActive" SG_ 1381 EnergyForNextCrank_ISig_4 100;
BA_ "GenSigStartValue" SG_ 1381 EnergyForNextCrank_ISig_4 15;
BA_ "Platform_Vivis2_Sig" SG_ 1381 EnergyForNextCrank_ISig_4 1;
BA_ "GenSigCycleTime" SG_ 1381 MainBatteryResetPos 100;
BA_ "GenSigCycleTimeActive" SG_ 1381 MainBatteryResetPos 100;
BA_ "GenSigStartValue" SG_ 1381 MainBatteryResetPos 15;
BA_ "Platform_Vivis2_Sig" SG_ 1381 MainBatteryResetPos 1;
BA_ "GenSigSendType" SG_ 519 GlareFreeArea02_LeftAngle 1;
BA_ "GenSigStartValue" SG_ 519 GlareFreeArea02_LeftAngle 2047;
BA_ "Platform_VMCU1_Sig" SG_ 519 GlareFreeArea02_LeftAngle 1;
BA_ "Platform_Vivis2_Sig" SG_ 519 GlareFreeArea02_LeftAngle 1;
BA_ "GenSigSendType" SG_ 519 AdaptiveMainBeamRight_cmd 1;
BA_ "GenSigStartValue" SG_ 519 AdaptiveMainBeamRight_cmd 7;
BA_ "Platform_VMCU1_Sig" SG_ 519 AdaptiveMainBeamRight_cmd 1;
BA_ "Platform_Vivis2_Sig" SG_ 519 AdaptiveMainBeamRight_cmd 1;
BA_ "GenSigSendType" SG_ 519 AdaptiveMainBeamLeft_cmd 1;
BA_ "GenSigStartValue" SG_ 519 AdaptiveMainBeamLeft_cmd 7;
BA_ "Platform_VMCU1_Sig" SG_ 519 AdaptiveMainBeamLeft_cmd 1;
BA_ "Platform_Vivis2_Sig" SG_ 519 AdaptiveMainBeamLeft_cmd 1;
BA_ "GenSigSendType" SG_ 519 GlareFreeArea02_Distance 1;
BA_ "GenSigStartValue" SG_ 519 GlareFreeArea02_Distance 1023;
BA_ "Platform_VMCU1_Sig" SG_ 519 GlareFreeArea02_Distance 1;
BA_ "Platform_Vivis2_Sig" SG_ 519 GlareFreeArea02_Distance 1;
BA_ "GenSigSendType" SG_ 519 GlareFreeArea02_RightAngle 1;
BA_ "GenSigStartValue" SG_ 519 GlareFreeArea02_RightAngle 2047;
BA_ "Platform_VMCU1_Sig" SG_ 519 GlareFreeArea02_RightAngle 1;
BA_ "Platform_Vivis2_Sig" SG_ 519 GlareFreeArea02_RightAngle 1;
BA_ "GenSigSendType" SG_ 518 GlareFreeArea03_Distance 1;
BA_ "GenSigStartValue" SG_ 518 GlareFreeArea03_Distance 1023;
BA_ "Platform_VMCU1_Sig" SG_ 518 GlareFreeArea03_Distance 1;
BA_ "Platform_Vivis2_Sig" SG_ 518 GlareFreeArea03_Distance 1;
BA_ "GenSigSendType" SG_ 518 GlareFreeArea01_Distance 1;
BA_ "GenSigStartValue" SG_ 518 GlareFreeArea01_Distance 1023;
BA_ "GenSigSendType" SG_ 518 GlareFreeArea01_LeftAngle 1;
BA_ "GenSigStartValue" SG_ 518 GlareFreeArea01_LeftAngle 2047;
BA_ "Platform_VMCU1_Sig" SG_ 518 GlareFreeArea01_LeftAngle 1;
BA_ "Platform_Vivis2_Sig" SG_ 518 GlareFreeArea01_LeftAngle 1;
BA_ "GenSigSendType" SG_ 518 GlareFreeArea03_RightAngle 1;
BA_ "GenSigStartValue" SG_ 518 GlareFreeArea03_RightAngle 2047;
BA_ "Platform_VMCU1_Sig" SG_ 518 GlareFreeArea03_RightAngle 1;
BA_ "Platform_Vivis2_Sig" SG_ 518 GlareFreeArea03_RightAngle 1;
BA_ "GenSigSendType" SG_ 518 GlareFreeArea03_LeftAngle 1;
BA_ "GenSigStartValue" SG_ 518 GlareFreeArea03_LeftAngle 2047;
BA_ "Platform_VMCU1_Sig" SG_ 518 GlareFreeArea03_LeftAngle 1;
BA_ "Platform_Vivis2_Sig" SG_ 518 GlareFreeArea03_LeftAngle 1;
BA_ "GenSigSendType" SG_ 518 GlareFreeArea01_RightAngle 1;
BA_ "GenSigStartValue" SG_ 518 GlareFreeArea01_RightAngle 2047;
BA_ "Platform_VMCU1_Sig" SG_ 518 GlareFreeArea01_RightAngle 1;
BA_ "Platform_Vivis2_Sig" SG_ 518 GlareFreeArea01_RightAngle 1;
BA_ "GenSigCycleTime" SG_ 1370 TPMSetPresThresCfg_VehiclePos_IS 100;
BA_ "GenSigCycleTimeActive" SG_ 1370 TPMSetPresThresCfg_VehiclePos_IS 100;
BA_ "GenSigStartValue" SG_ 1370 TPMSetPresThresCfg_VehiclePos_IS 7;
BA_ "SystemSignalLongSymbol" SG_ 1370 TPMSetPresThresCfg_VehiclePos_IS "TPMSetPresThresCfg_VehiclePos_ISig_4";
BA_ "GenSigCycleTime" SG_ 1370 TPMSetPresThresCfg_ExtUnderPres_ 100;
BA_ "GenSigCycleTimeActive" SG_ 1370 TPMSetPresThresCfg_ExtUnderPres_ 100;
BA_ "GenSigStartValue" SG_ 1370 TPMSetPresThresCfg_ExtUnderPres_ 255;
BA_ "SystemSignalLongSymbol" SG_ 1370 TPMSetPresThresCfg_ExtUnderPres_ "TPMSetPresThresCfg_ExtUnderPres_ISig_4";
BA_ "GenSigCycleTime" SG_ 1370 TPMSetPresThresCfg_OverPres_ISig 100;
BA_ "GenSigCycleTimeActive" SG_ 1370 TPMSetPresThresCfg_OverPres_ISig 100;
BA_ "GenSigStartValue" SG_ 1370 TPMSetPresThresCfg_OverPres_ISig 255;
BA_ "SystemSignalLongSymbol" SG_ 1370 TPMSetPresThresCfg_OverPres_ISig "TPMSetPresThresCfg_OverPres_ISig_4";
BA_ "GenSigCycleTime" SG_ 1370 TPMSetPresThresCfg_AxleNr_ISig_4 100;
BA_ "GenSigCycleTimeActive" SG_ 1370 TPMSetPresThresCfg_AxleNr_ISig_4 100;
BA_ "GenSigStartValue" SG_ 1370 TPMSetPresThresCfg_AxleNr_ISig_4 7;
BA_ "GenSigCycleTime" SG_ 1370 TPMSetPresThresCfg_ExtOverPres_I 100;
BA_ "GenSigCycleTimeActive" SG_ 1370 TPMSetPresThresCfg_ExtOverPres_I 100;
BA_ "GenSigStartValue" SG_ 1370 TPMSetPresThresCfg_ExtOverPres_I 255;
BA_ "SystemSignalLongSymbol" SG_ 1370 TPMSetPresThresCfg_ExtOverPres_I "TPMSetPresThresCfg_ExtOverPres_ISig_4";
BA_ "GenSigCycleTime" SG_ 1370 TPMSetPresThresCfg_UnderPres_ISi 100;
BA_ "GenSigCycleTimeActive" SG_ 1370 TPMSetPresThresCfg_UnderPres_ISi 100;
BA_ "GenSigStartValue" SG_ 1370 TPMSetPresThresCfg_UnderPres_ISi 255;
BA_ "SystemSignalLongSymbol" SG_ 1370 TPMSetPresThresCfg_UnderPres_ISi "TPMSetPresThresCfg_UnderPres_ISig_4";
BA_ "GenSigCycleTime" SG_ 1373 TPMPosOfWMReq_VehiclePos_ISig_4 100;
BA_ "GenSigCycleTimeActive" SG_ 1373 TPMPosOfWMReq_VehiclePos_ISig_4 100;
BA_ "GenSigStartValue" SG_ 1373 TPMPosOfWMReq_VehiclePos_ISig_4 7;
BA_ "GenSigCycleTime" SG_ 1373 TPMPosOfWMReq_TireId_ISig_4 100;
BA_ "GenSigCycleTimeActive" SG_ 1373 TPMPosOfWMReq_TireId_ISig_4 100;
BA_ "GenSigCycleTime" SG_ 1373 TPMSetAxleRefPres_Axle2_ISig_4 100;
BA_ "GenSigCycleTimeActive" SG_ 1373 TPMSetAxleRefPres_Axle2_ISig_4 100;
BA_ "GenSigStartValue" SG_ 1373 TPMSetAxleRefPres_Axle2_ISig_4 255;
BA_ "GenSigCycleTime" SG_ 1373 TPMSetAxleRefPres_Axle3_ISig_4 100;
BA_ "GenSigCycleTimeActive" SG_ 1373 TPMSetAxleRefPres_Axle3_ISig_4 100;
BA_ "GenSigStartValue" SG_ 1373 TPMSetAxleRefPres_Axle3_ISig_4 255;
BA_ "GenSigCycleTime" SG_ 1373 TPMSetAxleRefPres_Axle4_ISig_4 100;
BA_ "GenSigCycleTimeActive" SG_ 1373 TPMSetAxleRefPres_Axle4_ISig_4 100;
BA_ "GenSigStartValue" SG_ 1373 TPMSetAxleRefPres_Axle4_ISig_4 255;
BA_ "GenSigCycleTime" SG_ 1373 TPMSetAxleRefPres_Axle5_ISig_4 100;
BA_ "GenSigCycleTimeActive" SG_ 1373 TPMSetAxleRefPres_Axle5_ISig_4 100;
BA_ "GenSigStartValue" SG_ 1373 TPMSetAxleRefPres_Axle5_ISig_4 255;
BA_ "GenSigCycleTime" SG_ 1373 TPMSetAxleRefPres_Axle1_ISig_4 100;
BA_ "GenSigCycleTimeActive" SG_ 1373 TPMSetAxleRefPres_Axle1_ISig_4 100;
BA_ "GenSigStartValue" SG_ 1373 TPMSetAxleRefPres_Axle1_ISig_4 255;
BA_ "GenSigCycleTime" SG_ 1373 TPMSetAxleRefPres_VehiclePos_ISi 100;
BA_ "GenSigCycleTimeActive" SG_ 1373 TPMSetAxleRefPres_VehiclePos_ISi 100;
BA_ "GenSigStartValue" SG_ 1373 TPMSetAxleRefPres_VehiclePos_ISi 7;
BA_ "SystemSignalLongSymbol" SG_ 1373 TPMSetAxleRefPres_VehiclePos_ISi "TPMSetAxleRefPres_VehiclePos_ISig_4";
BA_ "GenSigCycleTime" SG_ 1249 TransferCasePTOEngaged 100;
BA_ "GenSigCycleTimeActive" SG_ 1249 TransferCasePTOEngaged 100;
BA_ "GenSigStartValue" SG_ 1249 TransferCasePTOEngaged 3;
BA_ "Platform_VMCU1_Sig" SG_ 1249 TransferCasePTOEngaged 1;
BA_ "Platform_Vivis2_Sig" SG_ 1249 TransferCasePTOEngaged 1;
BA_ "GenSigCycleTime" SG_ 1249 EhrasTagAxleLoweringInhibit 100;
BA_ "GenSigCycleTimeActive" SG_ 1249 EhrasTagAxleLoweringInhibit 100;
BA_ "GenSigStartValue" SG_ 1249 EhrasTagAxleLoweringInhibit 3;
BA_ "Platform_Vivis2_Sig" SG_ 1249 EhrasTagAxleLoweringInhibit 1;
BA_ "GenSigCycleTime" SG_ 1249 ExtECSRequestPressureUpdate 100;
BA_ "GenSigCycleTimeActive" SG_ 1249 ExtECSRequestPressureUpdate 100;
BA_ "GenSigStartValue" SG_ 1249 ExtECSRequestPressureUpdate 3;
BA_ "Platform_Vivis2_Sig" SG_ 1249 ExtECSRequestPressureUpdate 1;
BA_ "GenSigCycleTime" SG_ 1249 HeadLampFanControl_rqst 100;
BA_ "GenSigCycleTimeActive" SG_ 1249 HeadLampFanControl_rqst 100;
BA_ "GenSigStartValue" SG_ 1249 HeadLampFanControl_rqst 3;
BA_ "Platform_Vivis2_Sig" SG_ 1249 HeadLampFanControl_rqst 1;
BA_ "GenSigCycleTime" SG_ 1249 BBAirDumpRequest 100;
BA_ "GenSigCycleTimeActive" SG_ 1249 BBAirDumpRequest 100;
BA_ "GenSigStartValue" SG_ 1249 BBAirDumpRequest 3;
BA_ "Platform_Vivis2_Sig" SG_ 1249 BBAirDumpRequest 1;
BA_ "GenSigCycleTime" SG_ 1249 ApproachLight_rqst 100;
BA_ "GenSigCycleTimeActive" SG_ 1249 ApproachLight_rqst 100;
BA_ "GenSigStartValue" SG_ 1249 ApproachLight_rqst 3;
BA_ "Platform_Vivis2_Sig" SG_ 1249 ApproachLight_rqst 1;
BA_ "GenSigCycleTime" SG_ 1249 FrAxle2WheelDriveRequest 100;
BA_ "GenSigCycleTimeActive" SG_ 1249 FrAxle2WheelDriveRequest 100;
BA_ "GenSigStartValue" SG_ 1249 FrAxle2WheelDriveRequest 3;
BA_ "Platform_VMCU1_Sig" SG_ 1249 FrAxle2WheelDriveRequest 1;
BA_ "Platform_Vivis2_Sig" SG_ 1249 FrAxle2WheelDriveRequest 1;
BA_ "GenSigCycleTime" SG_ 1249 EhrasPusherAxleLoweringInhibit 100;
BA_ "GenSigCycleTimeActive" SG_ 1249 EhrasPusherAxleLoweringInhibit 100;
BA_ "GenSigStartValue" SG_ 1249 EhrasPusherAxleLoweringInhibit 3;
BA_ "Platform_Vivis2_Sig" SG_ 1249 EhrasPusherAxleLoweringInhibit 1;
BA_ "GenSigCycleTime" SG_ 1249 LivBatteryChargingStat_rqst 100;
BA_ "GenSigCycleTimeActive" SG_ 1249 LivBatteryChargingStat_rqst 100;
BA_ "GenSigStartValue" SG_ 1249 LivBatteryChargingStat_rqst 3;
BA_ "Platform_Vivis2_Sig" SG_ 1249 LivBatteryChargingStat_rqst 1;
BA_ "GenSigCycleTime" SG_ 1249 ClutchSwitch2Stat 100;
BA_ "GenSigCycleTimeActive" SG_ 1249 ClutchSwitch2Stat 100;
BA_ "GenSigStartValue" SG_ 1249 ClutchSwitch2Stat 3;
BA_ "Platform_VMCU1_Sig" SG_ 1249 ClutchSwitch2Stat 1;
BA_ "Platform_Vivis2_Sig" SG_ 1249 ClutchSwitch2Stat 1;
BA_ "GenSigCycleTime" SG_ 1249 SideMarkersLights_cmd 100;
BA_ "GenSigCycleTimeActive" SG_ 1249 SideMarkersLights_cmd 100;
BA_ "GenSigStartValue" SG_ 1249 SideMarkersLights_cmd 7;
BA_ "Platform_VMCU1_Sig" SG_ 1249 SideMarkersLights_cmd 1;
BA_ "Platform_Vivis2_Sig" SG_ 1249 SideMarkersLights_cmd 1;
BA_ "GenSigCycleTime" SG_ 1249 BBEcsForceStandstillFilterReq 100;
BA_ "GenSigCycleTimeActive" SG_ 1249 BBEcsForceStandstillFilterReq 100;
BA_ "GenSigStartValue" SG_ 1249 BBEcsForceStandstillFilterReq 3;
BA_ "Platform_Vivis2_Sig" SG_ 1249 BBEcsForceStandstillFilterReq 1;
BA_ "GenSigCycleTime" SG_ 944 ShortStopHeater_cmd_ISig_4 100;
BA_ "GenSigCycleTimeActive" SG_ 944 ShortStopHeater_cmd_ISig_4 100;
BA_ "GenSigStartValue" SG_ 944 ShortStopHeater_cmd_ISig_4 3;
BA_ "Platform_VMCU1_Sig" SG_ 944 ShortStopHeater_cmd_ISig_4 1;
BA_ "Platform_Vivis2_Sig" SG_ 944 ShortStopHeater_cmd_ISig_4 1;
BA_ "GenSigSendType" SG_ 944 LoadDistributionRequested_UB_ISi 7;
BA_ "Platform_VMCU1_Sig" SG_ 944 LoadDistributionRequested_UB_ISi 1;
BA_ "Platform_Vivis2_Sig" SG_ 944 LoadDistributionRequested_UB_ISi 1;
BA_ "SystemSignalLongSymbol" SG_ 944 LoadDistributionRequested_UB_ISi "LoadDistributionRequested_UB_ISig_4";
BA_ "GenSigCycleTime" SG_ 944 LoadDistributionRequested_ISig_4 100;
BA_ "GenSigCycleTimeActive" SG_ 944 LoadDistributionRequested_ISig_4 100;
BA_ "GenSigStartValue" SG_ 944 LoadDistributionRequested_ISig_4 15;
BA_ "NeedsUpdateBit" SG_ 944 LoadDistributionRequested_ISig_4 1;
BA_ "Platform_VMCU1_Sig" SG_ 944 LoadDistributionRequested_ISig_4 1;
BA_ "Platform_Vivis2_Sig" SG_ 944 LoadDistributionRequested_ISig_4 1;
BA_ "GenSigSendType" SG_ 390 CityHorn_cmd_UB 7;
BA_ "Platform_VMCU1_Sig" SG_ 390 CityHorn_cmd_UB 1;
BA_ "Platform_Vivis2_Sig" SG_ 390 CityHorn_cmd_UB 1;
BA_ "GenSigSendType" SG_ 390 FrontAxleRightWheelSpeed_UB_ISig 7;
BA_ "Platform_VMCU1_Sig" SG_ 390 FrontAxleRightWheelSpeed_UB_ISig 1;
BA_ "Platform_Vivis2_Sig" SG_ 390 FrontAxleRightWheelSpeed_UB_ISig 1;
BA_ "SystemSignalLongSymbol" SG_ 390 FrontAxleRightWheelSpeed_UB_ISig "FrontAxleRightWheelSpeed_UB_ISig_4";
BA_ "GenSigCycleTime" SG_ 390 CityHorn_cmd 100;
BA_ "GenSigCycleTimeActive" SG_ 390 CityHorn_cmd 100;
BA_ "GenSigStartValue" SG_ 390 CityHorn_cmd 3;
BA_ "GenSigMaxLatency" SG_ 390 CityHorn_cmd 23;
BA_ "NeedsUpdateBit" SG_ 390 CityHorn_cmd 1;
BA_ "Platform_VMCU1_Sig" SG_ 390 CityHorn_cmd 1;
BA_ "Platform_Vivis2_Sig" SG_ 390 CityHorn_cmd 1;
BA_ "GenSigCycleTime" SG_ 390 BrakeSwitch_ISig_4 100;
BA_ "GenSigCycleTimeActive" SG_ 390 BrakeSwitch_ISig_4 100;
BA_ "GenSigStartValue" SG_ 390 BrakeSwitch_ISig_4 3;
BA_ "GenSigMaxLatency" SG_ 390 BrakeSwitch_ISig_4 23;
BA_ "Platform_VMCU1_Sig" SG_ 390 BrakeSwitch_ISig_4 1;
BA_ "Platform_Vivis2_Sig" SG_ 390 BrakeSwitch_ISig_4 1;
BA_ "GenSigCycleTime" SG_ 390 LevelRequest_FrontAxle_ISig_4 100;
BA_ "GenSigCycleTimeActive" SG_ 390 LevelRequest_FrontAxle_ISig_4 100;
BA_ "GenSigStartValue" SG_ 390 LevelRequest_FrontAxle_ISig_4 7;
BA_ "NeedsUpdateBit" SG_ 390 LevelRequest_FrontAxle_ISig_4 1;
BA_ "Platform_VMCU1_Sig" SG_ 390 LevelRequest_FrontAxle_ISig_4 1;
BA_ "Platform_Vivis2_Sig" SG_ 390 LevelRequest_FrontAxle_ISig_4 1;
BA_ "GenSigSendType" SG_ 390 AuxiliaryHorn_cmd_UB 7;
BA_ "Platform_VMCU1_Sig" SG_ 390 AuxiliaryHorn_cmd_UB 1;
BA_ "Platform_Vivis2_Sig" SG_ 390 AuxiliaryHorn_cmd_UB 1;
BA_ "GenSigCycleTime" SG_ 390 FrontAxleRightWheelSpeed_ISig_4 100;
BA_ "GenSigCycleTimeActive" SG_ 390 FrontAxleRightWheelSpeed_ISig_4 100;
BA_ "GenSigStartValue" SG_ 390 FrontAxleRightWheelSpeed_ISig_4 65535;
BA_ "NeedsUpdateBit" SG_ 390 FrontAxleRightWheelSpeed_ISig_4 1;
BA_ "Platform_VMCU1_Sig" SG_ 390 FrontAxleRightWheelSpeed_ISig_4 1;
BA_ "Platform_Vivis2_Sig" SG_ 390 FrontAxleRightWheelSpeed_ISig_4 1;
BA_ "GenSigCycleTime" SG_ 390 FrontAxleLeftWheelSpeed_ISig_4 100;
BA_ "GenSigCycleTimeActive" SG_ 390 FrontAxleLeftWheelSpeed_ISig_4 100;
BA_ "GenSigStartValue" SG_ 390 FrontAxleLeftWheelSpeed_ISig_4 65535;
BA_ "NeedsUpdateBit" SG_ 390 FrontAxleLeftWheelSpeed_ISig_4 1;
BA_ "Platform_VMCU1_Sig" SG_ 390 FrontAxleLeftWheelSpeed_ISig_4 1;
BA_ "Platform_Vivis2_Sig" SG_ 390 FrontAxleLeftWheelSpeed_ISig_4 1;
BA_ "GenSigCycleTime" SG_ 390 FPBRChangeReq_ISig_4 100;
BA_ "GenSigCycleTimeActive" SG_ 390 FPBRChangeReq_ISig_4 100;
BA_ "GenSigStartValue" SG_ 390 FPBRChangeReq_ISig_4 3;
BA_ "Platform_VMCU1_Sig" SG_ 390 FPBRChangeReq_ISig_4 1;
BA_ "Platform_Vivis2_Sig" SG_ 390 FPBRChangeReq_ISig_4 1;
BA_ "GenSigCycleTime" SG_ 390 AuxiliaryHorn_cmd 100;
BA_ "GenSigCycleTimeActive" SG_ 390 AuxiliaryHorn_cmd 100;
BA_ "GenSigStartValue" SG_ 390 AuxiliaryHorn_cmd 3;
BA_ "GenSigMaxLatency" SG_ 390 AuxiliaryHorn_cmd 23;
BA_ "NeedsUpdateBit" SG_ 390 AuxiliaryHorn_cmd 1;
BA_ "Platform_VMCU1_Sig" SG_ 390 AuxiliaryHorn_cmd 1;
BA_ "Platform_Vivis2_Sig" SG_ 390 AuxiliaryHorn_cmd 1;
BA_ "GenSigSendType" SG_ 390 LevelRequest_sg_UB_ISig_4 7;
BA_ "Platform_VMCU1_Sig" SG_ 390 LevelRequest_sg_UB_ISig_4 1;
BA_ "Platform_Vivis2_Sig" SG_ 390 LevelRequest_sg_UB_ISig_4 1;
BA_ "GenSigCycleTime" SG_ 390 LevelRequest_RearAxle_ISig_4 100;
BA_ "GenSigCycleTimeActive" SG_ 390 LevelRequest_RearAxle_ISig_4 100;
BA_ "GenSigStartValue" SG_ 390 LevelRequest_RearAxle_ISig_4 7;
BA_ "NeedsUpdateBit" SG_ 390 LevelRequest_RearAxle_ISig_4 1;
BA_ "Platform_VMCU1_Sig" SG_ 390 LevelRequest_RearAxle_ISig_4 1;
BA_ "Platform_Vivis2_Sig" SG_ 390 LevelRequest_RearAxle_ISig_4 1;
BA_ "GenSigCycleTime" SG_ 390 LevelRequest_RollRequest_ISig_4 100;
BA_ "GenSigCycleTimeActive" SG_ 390 LevelRequest_RollRequest_ISig_4 100;
BA_ "GenSigStartValue" SG_ 390 LevelRequest_RollRequest_ISig_4 7;
BA_ "NeedsUpdateBit" SG_ 390 LevelRequest_RollRequest_ISig_4 1;
BA_ "Platform_VMCU1_Sig" SG_ 390 LevelRequest_RollRequest_ISig_4 1;
BA_ "Platform_Vivis2_Sig" SG_ 390 LevelRequest_RollRequest_ISig_4 1;
BA_ "GenSigSendType" SG_ 390 FrontAxleLeftWheelSpeed_UB_ISig_ 7;
BA_ "Platform_VMCU1_Sig" SG_ 390 FrontAxleLeftWheelSpeed_UB_ISig_ 1;
BA_ "Platform_Vivis2_Sig" SG_ 390 FrontAxleLeftWheelSpeed_UB_ISig_ 1;
BA_ "SystemSignalLongSymbol" SG_ 390 FrontAxleLeftWheelSpeed_UB_ISig_ "FrontAxleLeftWheelSpeed_UB_ISig_4";
BA_ "GenSigSendType" SG_ 389 RearAxleRightWheelSpeed_UB_ISig_ 7;
BA_ "Platform_VMCU1_Sig" SG_ 389 RearAxleRightWheelSpeed_UB_ISig_ 1;
BA_ "Platform_Vivis2_Sig" SG_ 389 RearAxleRightWheelSpeed_UB_ISig_ 1;
BA_ "SystemSignalLongSymbol" SG_ 389 RearAxleRightWheelSpeed_UB_ISig_ "RearAxleRightWheelSpeed_UB_ISig_4";
BA_ "GenSigCycleTime" SG_ 389 FrontWheelDriveRequest 100;
BA_ "GenSigCycleTimeActive" SG_ 389 FrontWheelDriveRequest 100;
BA_ "GenSigStartValue" SG_ 389 FrontWheelDriveRequest 3;
BA_ "Platform_VMCU1_Sig" SG_ 389 FrontWheelDriveRequest 1;
BA_ "Platform_Vivis2_Sig" SG_ 389 FrontWheelDriveRequest 1;
BA_ "GenSigCycleTime" SG_ 389 RearAxleLeftWheelSpeed_ISig_4 100;
BA_ "GenSigCycleTimeActive" SG_ 389 RearAxleLeftWheelSpeed_ISig_4 100;
BA_ "GenSigStartValue" SG_ 389 RearAxleLeftWheelSpeed_ISig_4 65535;
BA_ "GenSigMaxLatency" SG_ 389 RearAxleLeftWheelSpeed_ISig_4 51;
BA_ "NeedsUpdateBit" SG_ 389 RearAxleLeftWheelSpeed_ISig_4 1;
BA_ "Platform_VMCU1_Sig" SG_ 389 RearAxleLeftWheelSpeed_ISig_4 1;
BA_ "Platform_Vivis2_Sig" SG_ 389 RearAxleLeftWheelSpeed_ISig_4 1;
BA_ "GenSigSendType" SG_ 389 RearAxleLeftWheelSpeed_UB_ISig_4 7;
BA_ "Platform_VMCU1_Sig" SG_ 389 RearAxleLeftWheelSpeed_UB_ISig_4 1;
BA_ "Platform_Vivis2_Sig" SG_ 389 RearAxleLeftWheelSpeed_UB_ISig_4 1;
BA_ "GenSigCycleTime" SG_ 389 RearAxleRightWheelSpeed_ISig_4 100;
BA_ "GenSigCycleTimeActive" SG_ 389 RearAxleRightWheelSpeed_ISig_4 100;
BA_ "GenSigStartValue" SG_ 389 RearAxleRightWheelSpeed_ISig_4 65535;
BA_ "GenSigMaxLatency" SG_ 389 RearAxleRightWheelSpeed_ISig_4 51;
BA_ "NeedsUpdateBit" SG_ 389 RearAxleRightWheelSpeed_ISig_4 1;
BA_ "Platform_VMCU1_Sig" SG_ 389 RearAxleRightWheelSpeed_ISig_4 1;
BA_ "Platform_Vivis2_Sig" SG_ 389 RearAxleRightWheelSpeed_ISig_4 1;
BA_ "GenSigCycleTime" SG_ 389 KneelingChangeRequest_ISig_4 100;
BA_ "GenSigCycleTimeActive" SG_ 389 KneelingChangeRequest_ISig_4 100;
BA_ "GenSigStartValue" SG_ 389 KneelingChangeRequest_ISig_4 3;
BA_ "Platform_VMCU1_Sig" SG_ 389 KneelingChangeRequest_ISig_4 1;
BA_ "Platform_Vivis2_Sig" SG_ 389 KneelingChangeRequest_ISig_4 1;
BA_ "GenSigCycleTime" SG_ 1364 HoursUTC_ISig_4 100;
BA_ "GenSigCycleTimeActive" SG_ 1364 HoursUTC_ISig_4 100;
BA_ "GenSigStartValue" SG_ 1364 HoursUTC_ISig_4 255;
BA_ "Platform_VMCU1_Sig" SG_ 1364 HoursUTC_ISig_4 1;
BA_ "Platform_Vivis2_Sig" SG_ 1364 HoursUTC_ISig_4 1;
BA_ "GenSigCycleTime" SG_ 1364 RoadInclination_ISig_4 100;
BA_ "GenSigCycleTimeActive" SG_ 1364 RoadInclination_ISig_4 100;
BA_ "GenSigStartValue" SG_ 1364 RoadInclination_ISig_4 255;
BA_ "Platform_VMCU1_Sig" SG_ 1364 RoadInclination_ISig_4 1;
BA_ "Platform_Vivis2_Sig" SG_ 1364 RoadInclination_ISig_4 1;
BA_ "GenSigCycleTime" SG_ 1364 MonthUTC_ISig_4 100;
BA_ "GenSigCycleTimeActive" SG_ 1364 MonthUTC_ISig_4 100;
BA_ "GenSigStartValue" SG_ 1364 MonthUTC_ISig_4 255;
BA_ "Platform_VMCU1_Sig" SG_ 1364 MonthUTC_ISig_4 1;
BA_ "Platform_Vivis2_Sig" SG_ 1364 MonthUTC_ISig_4 1;
BA_ "GenSigCycleTime" SG_ 1364 YearUTC_ISig_4 100;
BA_ "GenSigCycleTimeActive" SG_ 1364 YearUTC_ISig_4 100;
BA_ "GenSigStartValue" SG_ 1364 YearUTC_ISig_4 255;
BA_ "Platform_VMCU1_Sig" SG_ 1364 YearUTC_ISig_4 1;
BA_ "Platform_Vivis2_Sig" SG_ 1364 YearUTC_ISig_4 1;
BA_ "GenSigCycleTime" SG_ 1364 SecondsUTC_ISig_4 100;
BA_ "GenSigCycleTimeActive" SG_ 1364 SecondsUTC_ISig_4 100;
BA_ "GenSigStartValue" SG_ 1364 SecondsUTC_ISig_4 255;
BA_ "Platform_VMCU1_Sig" SG_ 1364 SecondsUTC_ISig_4 1;
BA_ "Platform_Vivis2_Sig" SG_ 1364 SecondsUTC_ISig_4 1;
BA_ "GenSigCycleTime" SG_ 1364 DayUTC_ISig_4 100;
BA_ "GenSigCycleTimeActive" SG_ 1364 DayUTC_ISig_4 100;
BA_ "GenSigStartValue" SG_ 1364 DayUTC_ISig_4 255;
BA_ "Platform_VMCU1_Sig" SG_ 1364 DayUTC_ISig_4 1;
BA_ "Platform_Vivis2_Sig" SG_ 1364 DayUTC_ISig_4 1;
BA_ "GenSigCycleTime" SG_ 1364 MinutesUTC_ISig_4 100;
BA_ "GenSigCycleTimeActive" SG_ 1364 MinutesUTC_ISig_4 100;
BA_ "GenSigStartValue" SG_ 1364 MinutesUTC_ISig_4 255;
BA_ "Platform_VMCU1_Sig" SG_ 1364 MinutesUTC_ISig_4 1;
BA_ "Platform_Vivis2_Sig" SG_ 1364 MinutesUTC_ISig_4 1;
BA_ "GenSigCycleTime" SG_ 826 BBContUnlockCmd 100;
BA_ "GenSigCycleTimeActive" SG_ 826 BBContUnlockCmd 100;
BA_ "GenSigStartValue" SG_ 826 BBContUnlockCmd 3;
BA_ "GenSigMaxLatency" SG_ 826 BBContUnlockCmd 35;
BA_ "Platform_VMCU1_Sig" SG_ 826 BBContUnlockCmd 1;
BA_ "Platform_Vivis2_Sig" SG_ 826 BBContUnlockCmd 1;
BA_ "GenSigCycleTime" SG_ 826 LampCheck_cmd 100;
BA_ "GenSigCycleTimeActive" SG_ 826 LampCheck_cmd 100;
BA_ "GenSigStartValue" SG_ 826 LampCheck_cmd 3;
BA_ "Platform_VMCU1_Sig" SG_ 826 LampCheck_cmd 1;
BA_ "Platform_Vivis2_Sig" SG_ 826 LampCheck_cmd 1;
BA_ "GenSigCycleTime" SG_ 826 LampCheck_rqst_ISig_4 100;
BA_ "GenSigCycleTimeActive" SG_ 826 LampCheck_rqst_ISig_4 100;
BA_ "GenSigStartValue" SG_ 826 LampCheck_rqst_ISig_4 3;
BA_ "Platform_VMCU1_Sig" SG_ 826 LampCheck_rqst_ISig_4 1;
BA_ "Platform_Vivis2_Sig" SG_ 826 LampCheck_rqst_ISig_4 1;
BA_ "GenSigCycleTime" SG_ 826 BatteryCapacity_ISig_4 100;
BA_ "GenSigCycleTimeActive" SG_ 826 BatteryCapacity_ISig_4 100;
BA_ "GenSigStartValue" SG_ 826 BatteryCapacity_ISig_4 15;
BA_ "Platform_VMCU1_Sig" SG_ 826 BatteryCapacity_ISig_4 1;
BA_ "Platform_Vivis2_Sig" SG_ 826 BatteryCapacity_ISig_4 1;
BA_ "GenSigCycleTime" SG_ 826 AreaInhibit 100;
BA_ "GenSigCycleTimeActive" SG_ 826 AreaInhibit 100;
BA_ "GenSigStartValue" SG_ 826 AreaInhibit 3;
BA_ "GenSigMaxLatency" SG_ 826 AreaInhibit 35;
BA_ "Platform_VMCU1_Sig" SG_ 826 AreaInhibit 1;
BA_ "Platform_Vivis2_Sig" SG_ 826 AreaInhibit 1;
BA_ "GenSigCycleTime" SG_ 826 LEDAnimation_cmd 100;
BA_ "GenSigCycleTimeActive" SG_ 826 LEDAnimation_cmd 100;
BA_ "GenSigInactiveValue" SG_ 826 LEDAnimation_cmd 7;
BA_ "GenSigStartValue" SG_ 826 LEDAnimation_cmd 7;
BA_ "Platform_VMCU1_Sig" SG_ 826 LEDAnimation_cmd 1;
BA_ "Platform_Vivis2_Sig" SG_ 826 LEDAnimation_cmd 1;
BA_ "GenSigCycleTime" SG_ 826 ActualDrvlnRetdrPercentTorque_IS 100;
BA_ "GenSigCycleTimeActive" SG_ 826 ActualDrvlnRetdrPercentTorque_IS 100;
BA_ "GenSigStartValue" SG_ 826 ActualDrvlnRetdrPercentTorque_IS 255;
BA_ "GenSigMaxLatency" SG_ 826 ActualDrvlnRetdrPercentTorque_IS 35;
BA_ "Platform_VMCU1_Sig" SG_ 826 ActualDrvlnRetdrPercentTorque_IS 1;
BA_ "Platform_Vivis2_Sig" SG_ 826 ActualDrvlnRetdrPercentTorque_IS 1;
BA_ "SystemSignalLongSymbol" SG_ 826 ActualDrvlnRetdrPercentTorque_IS "ActualDrvlnRetdrPercentTorque_ISig_4";
BA_ "GenSigCycleTime" SG_ 826 PloughLampModeStatus_ISig_4 100;
BA_ "GenSigCycleTimeActive" SG_ 826 PloughLampModeStatus_ISig_4 100;
BA_ "GenSigStartValue" SG_ 826 PloughLampModeStatus_ISig_4 3;
BA_ "Platform_VMCU1_Sig" SG_ 826 PloughLampModeStatus_ISig_4 1;
BA_ "Platform_Vivis2_Sig" SG_ 826 PloughLampModeStatus_ISig_4 1;
BA_ "GenSigCycleTime" SG_ 826 RangeInhibit 100;
BA_ "GenSigCycleTimeActive" SG_ 826 RangeInhibit 100;
BA_ "GenSigStartValue" SG_ 826 RangeInhibit 3;
BA_ "GenSigMaxLatency" SG_ 826 RangeInhibit 35;
BA_ "Platform_VMCU1_Sig" SG_ 826 RangeInhibit 1;
BA_ "Platform_Vivis2_Sig" SG_ 826 RangeInhibit 1;
BA_ "GenSigCycleTime" SG_ 826 TrailerBrakeNoEbs_stat 100;
BA_ "GenSigCycleTimeActive" SG_ 826 TrailerBrakeNoEbs_stat 100;
BA_ "GenSigStartValue" SG_ 826 TrailerBrakeNoEbs_stat 3;
BA_ "GenSigMaxLatency" SG_ 826 TrailerBrakeNoEbs_stat 35;
BA_ "Platform_VMCU1_Sig" SG_ 826 TrailerBrakeNoEbs_stat 1;
BA_ "Platform_Vivis2_Sig" SG_ 826 TrailerBrakeNoEbs_stat 1;
BA_ "GenSigCycleTime" SG_ 826 LiftAxle1DirectControl_ISig_4 100;
BA_ "GenSigCycleTimeActive" SG_ 826 LiftAxle1DirectControl_ISig_4 100;
BA_ "GenSigStartValue" SG_ 826 LiftAxle1DirectControl_ISig_4 7;
BA_ "NeedsUpdateBit" SG_ 826 LiftAxle1DirectControl_ISig_4 1;
BA_ "Platform_VMCU1_Sig" SG_ 826 LiftAxle1DirectControl_ISig_4 1;
BA_ "Platform_Vivis2_Sig" SG_ 826 LiftAxle1DirectControl_ISig_4 1;
BA_ "GenSigCycleTime" SG_ 826 DoorsAjar_stat_ISig_4 100;
BA_ "GenSigCycleTimeActive" SG_ 826 DoorsAjar_stat_ISig_4 100;
BA_ "GenSigInactiveValue" SG_ 826 DoorsAjar_stat_ISig_4 7;
BA_ "GenSigStartValue" SG_ 826 DoorsAjar_stat_ISig_4 7;
BA_ "NeedsUpdateBit" SG_ 826 DoorsAjar_stat_ISig_4 1;
BA_ "Platform_VMCU1_Sig" SG_ 826 DoorsAjar_stat_ISig_4 1;
BA_ "Platform_Vivis2_Sig" SG_ 826 DoorsAjar_stat_ISig_4 1;
BA_ "GenSigCycleTime" SG_ 826 BrakeLight_rqst 100;
BA_ "GenSigCycleTimeActive" SG_ 826 BrakeLight_rqst 100;
BA_ "GenSigStartValue" SG_ 826 BrakeLight_rqst 7;
BA_ "GenSigMaxLatency" SG_ 826 BrakeLight_rqst 35;
BA_ "NeedsUpdateBit" SG_ 826 BrakeLight_rqst 1;
BA_ "Platform_VMCU1_Sig" SG_ 826 BrakeLight_rqst 1;
BA_ "Platform_Vivis2_Sig" SG_ 826 BrakeLight_rqst 1;
BA_ "GenSigCycleTime" SG_ 826 BlackOutandConvoyMode_rqst 100;
BA_ "GenSigCycleTimeActive" SG_ 826 BlackOutandConvoyMode_rqst 100;
BA_ "GenSigInactiveValue" SG_ 826 BlackOutandConvoyMode_rqst 7;
BA_ "GenSigStartValue" SG_ 826 BlackOutandConvoyMode_rqst 7;
BA_ "Platform_VMCU1_Sig" SG_ 826 BlackOutandConvoyMode_rqst 1;
BA_ "Platform_Vivis2_Sig" SG_ 826 BlackOutandConvoyMode_rqst 1;
BA_ "GenSigSendType" SG_ 826 DoorsAjar_stat_UB_ISig_4 7;
BA_ "Platform_VMCU1_Sig" SG_ 826 DoorsAjar_stat_UB_ISig_4 1;
BA_ "Platform_Vivis2_Sig" SG_ 826 DoorsAjar_stat_UB_ISig_4 1;
BA_ "GenSigCycleTime" SG_ 826 RevLight_cmd 100;
BA_ "GenSigCycleTimeActive" SG_ 826 RevLight_cmd 100;
BA_ "GenSigStartValue" SG_ 826 RevLight_cmd 3;
BA_ "GenSigMaxLatency" SG_ 826 RevLight_cmd 35;
BA_ "Platform_VMCU1_Sig" SG_ 826 RevLight_cmd 1;
BA_ "Platform_Vivis2_Sig" SG_ 826 RevLight_cmd 1;
BA_ "GenSigSendType" SG_ 826 LiftAxle1DirectControl_UB_ISig_4 7;
BA_ "Platform_VMCU1_Sig" SG_ 826 LiftAxle1DirectControl_UB_ISig_4 1;
BA_ "Platform_Vivis2_Sig" SG_ 826 LiftAxle1DirectControl_UB_ISig_4 1;
BA_ "GenSigCycleTime" SG_ 826 ECSStandByRequest_ISig_4 100;
BA_ "GenSigCycleTimeActive" SG_ 826 ECSStandByRequest_ISig_4 100;
BA_ "GenSigInactiveValue" SG_ 826 ECSStandByRequest_ISig_4 7;
BA_ "GenSigStartValue" SG_ 826 ECSStandByRequest_ISig_4 7;
BA_ "Platform_VMCU1_Sig" SG_ 826 ECSStandByRequest_ISig_4 1;
BA_ "Platform_Vivis2_Sig" SG_ 826 ECSStandByRequest_ISig_4 1;
BA_ "GenSigCycleTime" SG_ 826 ChassisInstepLight_cmd 100;
BA_ "GenSigCycleTimeActive" SG_ 826 ChassisInstepLight_cmd 100;
BA_ "GenSigStartValue" SG_ 826 ChassisInstepLight_cmd 3;
BA_ "GenSigMaxLatency" SG_ 826 ChassisInstepLight_cmd 35;
BA_ "Platform_VMCU1_Sig" SG_ 826 ChassisInstepLight_cmd 1;
BA_ "Platform_Vivis2_Sig" SG_ 826 ChassisInstepLight_cmd 1;
BA_ "GenSigCycleTime" SG_ 826 BBSlidable5thWheelCmd 100;
BA_ "GenSigCycleTimeActive" SG_ 826 BBSlidable5thWheelCmd 100;
BA_ "GenSigStartValue" SG_ 826 BBSlidable5thWheelCmd 3;
BA_ "GenSigMaxLatency" SG_ 826 BBSlidable5thWheelCmd 35;
BA_ "Platform_VMCU1_Sig" SG_ 826 BBSlidable5thWheelCmd 1;
BA_ "Platform_Vivis2_Sig" SG_ 826 BBSlidable5thWheelCmd 1;
BA_ "GenSigCycleTime" SG_ 826 ParkingBrake_stat_ISig_4 100;
BA_ "GenSigCycleTimeActive" SG_ 826 ParkingBrake_stat_ISig_4 100;
BA_ "GenSigStartValue" SG_ 826 ParkingBrake_stat_ISig_4 3;
BA_ "Platform_Vivis2_Sig" SG_ 826 ParkingBrake_stat_ISig_4 1;
BA_ "GenSigCycleTime" SG_ 826 MaintBatteryReset 100;
BA_ "GenSigCycleTimeActive" SG_ 826 MaintBatteryReset 100;
BA_ "GenSigStartValue" SG_ 826 MaintBatteryReset 3;
BA_ "GenSigMaxLatency" SG_ 826 MaintBatteryReset 35;
BA_ "Platform_VMCU1_Sig" SG_ 826 MaintBatteryReset 1;
BA_ "Platform_Vivis2_Sig" SG_ 826 MaintBatteryReset 1;
BA_ "GenSigCycleTime" SG_ 1369 TotalVehicleDistanceHighRes_ISig 100;
BA_ "GenSigCycleTimeActive" SG_ 1369 TotalVehicleDistanceHighRes_ISig 100;
BA_ "GenSigStartValue" SG_ 1369 TotalVehicleDistanceHighRes_ISig 4294967295;
BA_ "GenSigMaxLatency" SG_ 1369 TotalVehicleDistanceHighRes_ISig 511;
BA_ "Platform_VMCU1_Sig" SG_ 1369 TotalVehicleDistanceHighRes_ISig 1;
BA_ "Platform_Vivis2_Sig" SG_ 1369 TotalVehicleDistanceHighRes_ISig 1;
BA_ "SystemSignalLongSymbol" SG_ 1369 TotalVehicleDistanceHighRes_ISig "TotalVehicleDistanceHighRes_ISig_4";
BA_ "GenSigCycleTime" SG_ 946 TransferCaseOrSplitboxPTOMode_IS 100;
BA_ "GenSigCycleTimeActive" SG_ 946 TransferCaseOrSplitboxPTOMode_IS 100;
BA_ "GenSigStartValue" SG_ 946 TransferCaseOrSplitboxPTOMode_IS 3;
BA_ "GenSigMaxLatency" SG_ 946 TransferCaseOrSplitboxPTOMode_IS 55;
BA_ "Platform_VMCU1_Sig" SG_ 946 TransferCaseOrSplitboxPTOMode_IS 1;
BA_ "Platform_Vivis2_Sig" SG_ 946 TransferCaseOrSplitboxPTOMode_IS 1;
BA_ "SystemSignalLongSymbol" SG_ 946 TransferCaseOrSplitboxPTOMode_IS "TransferCaseOrSplitboxPTOMode_ISig_4";
BA_ "GenSigCycleTime" SG_ 946 Pto3Status 100;
BA_ "GenSigCycleTimeActive" SG_ 946 Pto3Status 100;
BA_ "GenSigStartValue" SG_ 946 Pto3Status 3;
BA_ "GenSigMaxLatency" SG_ 946 Pto3Status 55;
BA_ "Platform_VMCU1_Sig" SG_ 946 Pto3Status 1;
BA_ "Platform_Vivis2_Sig" SG_ 946 Pto3Status 1;
BA_ "GenSigCycleTime" SG_ 946 RearAxleDiffLockActvnFuncReq_ISi 100;
BA_ "GenSigCycleTimeActive" SG_ 946 RearAxleDiffLockActvnFuncReq_ISi 100;
BA_ "GenSigStartValue" SG_ 946 RearAxleDiffLockActvnFuncReq_ISi 3;
BA_ "GenSigMaxLatency" SG_ 946 RearAxleDiffLockActvnFuncReq_ISi 55;
BA_ "NeedsUpdateBit" SG_ 946 RearAxleDiffLockActvnFuncReq_ISi 1;
BA_ "Platform_VMCU1_Sig" SG_ 946 RearAxleDiffLockActvnFuncReq_ISi 1;
BA_ "Platform_Vivis2_Sig" SG_ 946 RearAxleDiffLockActvnFuncReq_ISi 1;
BA_ "SystemSignalLongSymbol" SG_ 946 RearAxleDiffLockActvnFuncReq_ISi "RearAxleDiffLockActvnFuncReq_ISig_4";
BA_ "GenSigCycleTime" SG_ 946 Pto1Status_ISig_4 100;
BA_ "GenSigCycleTimeActive" SG_ 946 Pto1Status_ISig_4 100;
BA_ "GenSigStartValue" SG_ 946 Pto1Status_ISig_4 3;
BA_ "GenSigMaxLatency" SG_ 946 Pto1Status_ISig_4 55;
BA_ "Platform_VMCU1_Sig" SG_ 946 Pto1Status_ISig_4 1;
BA_ "Platform_Vivis2_Sig" SG_ 946 Pto1Status_ISig_4 1;
BA_ "GenSigCycleTime" SG_ 946 ReducedLoadMode_stat_ISig_4 100;
BA_ "GenSigCycleTimeActive" SG_ 946 ReducedLoadMode_stat_ISig_4 100;
BA_ "GenSigStartValue" SG_ 946 ReducedLoadMode_stat_ISig_4 3;
BA_ "Platform_VMCU1_Sig" SG_ 946 ReducedLoadMode_stat_ISig_4 1;
BA_ "Platform_Vivis2_Sig" SG_ 946 ReducedLoadMode_stat_ISig_4 1;
BA_ "GenSigSendType" SG_ 946 RearAxleDiffLockActvnFuncReq_UB_ 7;
BA_ "Platform_VMCU1_Sig" SG_ 946 RearAxleDiffLockActvnFuncReq_UB_ 1;
BA_ "Platform_Vivis2_Sig" SG_ 946 RearAxleDiffLockActvnFuncReq_UB_ 1;
BA_ "SystemSignalLongSymbol" SG_ 946 RearAxleDiffLockActvnFuncReq_UB_ "RearAxleDiffLockActvnFuncReq_UB_ISig_4";
BA_ "GenSigCycleTime" SG_ 946 RearAxleDiffLockActvnDrvrReq_ISi 100;
BA_ "GenSigCycleTimeActive" SG_ 946 RearAxleDiffLockActvnDrvrReq_ISi 100;
BA_ "GenSigStartValue" SG_ 946 RearAxleDiffLockActvnDrvrReq_ISi 3;
BA_ "GenSigMaxLatency" SG_ 946 RearAxleDiffLockActvnDrvrReq_ISi 55;
BA_ "NeedsUpdateBit" SG_ 946 RearAxleDiffLockActvnDrvrReq_ISi 1;
BA_ "Platform_VMCU1_Sig" SG_ 946 RearAxleDiffLockActvnDrvrReq_ISi 1;
BA_ "Platform_Vivis2_Sig" SG_ 946 RearAxleDiffLockActvnDrvrReq_ISi 1;
BA_ "SystemSignalLongSymbol" SG_ 946 RearAxleDiffLockActvnDrvrReq_ISi "RearAxleDiffLockActvnDrvrReq_ISig_4";
BA_ "GenSigSendType" SG_ 946 RearAxleDiffLockActvnDrvrReq_UB_ 7;
BA_ "Platform_VMCU1_Sig" SG_ 946 RearAxleDiffLockActvnDrvrReq_UB_ 1;
BA_ "Platform_Vivis2_Sig" SG_ 946 RearAxleDiffLockActvnDrvrReq_UB_ 1;
BA_ "SystemSignalLongSymbol" SG_ 946 RearAxleDiffLockActvnDrvrReq_UB_ "RearAxleDiffLockActvnDrvrReq_UB_ISig_4";
BA_ "GenSigCycleTime" SG_ 946 Pto2DrivingRequest 100;
BA_ "GenSigCycleTimeActive" SG_ 946 Pto2DrivingRequest 100;
BA_ "GenSigStartValue" SG_ 946 Pto2DrivingRequest 3;
BA_ "GenSigMaxLatency" SG_ 946 Pto2DrivingRequest 55;
BA_ "Platform_VMCU1_Sig" SG_ 946 Pto2DrivingRequest 1;
BA_ "Platform_Vivis2_Sig" SG_ 946 Pto2DrivingRequest 1;
BA_ "GenSigCycleTime" SG_ 946 RrInterAxlDiffLockActvnFuncReq_I 100;
BA_ "GenSigCycleTimeActive" SG_ 946 RrInterAxlDiffLockActvnFuncReq_I 100;
BA_ "GenSigStartValue" SG_ 946 RrInterAxlDiffLockActvnFuncReq_I 3;
BA_ "Platform_Vivis2_Sig" SG_ 946 RrInterAxlDiffLockActvnFuncReq_I 1;
BA_ "SystemSignalLongSymbol" SG_ 946 RrInterAxlDiffLockActvnFuncReq_I "RrInterAxlDiffLockActvnFuncReq_ISig_4";
BA_ "GenSigSendType" SG_ 946 RrInterAxlDiffLockActvnDrvrReq_U 7;
BA_ "Platform_VMCU1_Sig" SG_ 946 RrInterAxlDiffLockActvnDrvrReq_U 1;
BA_ "Platform_Vivis2_Sig" SG_ 946 RrInterAxlDiffLockActvnDrvrReq_U 1;
BA_ "SystemSignalLongSymbol" SG_ 946 RrInterAxlDiffLockActvnDrvrReq_U "RrInterAxlDiffLockActvnDrvrReq_UB_ISig_4";
BA_ "GenSigCycleTime" SG_ 946 CartridgeChangedDrvrReset_rqst_I 100;
BA_ "GenSigCycleTimeActive" SG_ 946 CartridgeChangedDrvrReset_rqst_I 100;
BA_ "GenSigStartValue" SG_ 946 CartridgeChangedDrvrReset_rqst_I 3;
BA_ "GenSigMaxLatency" SG_ 946 CartridgeChangedDrvrReset_rqst_I 55;
BA_ "Platform_VMCU1_Sig" SG_ 946 CartridgeChangedDrvrReset_rqst_I 1;
BA_ "Platform_Vivis2_Sig" SG_ 946 CartridgeChangedDrvrReset_rqst_I 1;
BA_ "SystemSignalLongSymbol" SG_ 946 CartridgeChangedDrvrReset_rqst_I "CartridgeChangedDrvrReset_rqst_ISig_4";
BA_ "GenSigCycleTime" SG_ 946 RrInterAxlDiffLockActvnDrvrReq_I 100;
BA_ "GenSigCycleTimeActive" SG_ 946 RrInterAxlDiffLockActvnDrvrReq_I 100;
BA_ "GenSigStartValue" SG_ 946 RrInterAxlDiffLockActvnDrvrReq_I 3;
BA_ "GenSigMaxLatency" SG_ 946 RrInterAxlDiffLockActvnDrvrReq_I 55;
BA_ "NeedsUpdateBit" SG_ 946 RrInterAxlDiffLockActvnDrvrReq_I 1;
BA_ "Platform_VMCU1_Sig" SG_ 946 RrInterAxlDiffLockActvnDrvrReq_I 1;
BA_ "Platform_Vivis2_Sig" SG_ 946 RrInterAxlDiffLockActvnDrvrReq_I 1;
BA_ "SystemSignalLongSymbol" SG_ 946 RrInterAxlDiffLockActvnDrvrReq_I "RrInterAxlDiffLockActvnDrvrReq_ISig_4";
BA_ "GenSigCycleTime" SG_ 946 Pto2Status_ISig_4 100;
BA_ "GenSigCycleTimeActive" SG_ 946 Pto2Status_ISig_4 100;
BA_ "GenSigStartValue" SG_ 946 Pto2Status_ISig_4 3;
BA_ "GenSigMaxLatency" SG_ 946 Pto2Status_ISig_4 55;
BA_ "Platform_VMCU1_Sig" SG_ 946 Pto2Status_ISig_4 1;
BA_ "Platform_Vivis2_Sig" SG_ 946 Pto2Status_ISig_4 1;
BA_ "GenSigCycleTime" SG_ 946 Pto4Status 100;
BA_ "GenSigCycleTimeActive" SG_ 946 Pto4Status 100;
BA_ "GenSigStartValue" SG_ 946 Pto4Status 3;
BA_ "GenSigMaxLatency" SG_ 946 Pto4Status 55;
BA_ "Platform_VMCU1_Sig" SG_ 946 Pto4Status 1;
BA_ "Platform_Vivis2_Sig" SG_ 946 Pto4Status 1;
BA_ "GenSigCycleTime" SG_ 946 Pto1DrivingRequest 100;
BA_ "GenSigCycleTimeActive" SG_ 946 Pto1DrivingRequest 100;
BA_ "GenSigStartValue" SG_ 946 Pto1DrivingRequest 3;
BA_ "GenSigMaxLatency" SG_ 946 Pto1DrivingRequest 55;
BA_ "Platform_VMCU1_Sig" SG_ 946 Pto1DrivingRequest 1;
BA_ "Platform_Vivis2_Sig" SG_ 946 Pto1DrivingRequest 1;
BA_REL_ "GenSigFirstTimeoutTime" BU_SG_REL_ VCM SG_ 1519 WGTrckTPMThresCfg_ExtOverPres 24000;
BA_REL_ "GenSigTimeoutTime" BU_SG_REL_ VCM SG_ 1519 WGTrckTPMThresCfg_ExtOverPres 6000;
BA_REL_ "GenSigFirstTimeoutTime" BU_SG_REL_ VCM SG_ 1519 WGTrckTPMThresCfg_AxleNr 24000;
BA_REL_ "GenSigTimeoutTime" BU_SG_REL_ VCM SG_ 1519 WGTrckTPMThresCfg_AxleNr 6000;
BA_REL_ "GenSigFirstTimeoutTime" BU_SG_REL_ VCM SG_ 1519 WGTrckTPMThresCfg_ExtUnderPres 24000;
BA_REL_ "GenSigTimeoutTime" BU_SG_REL_ VCM SG_ 1519 WGTrckTPMThresCfg_ExtUnderPres 6000;
BA_REL_ "GenSigFirstTimeoutTime" BU_SG_REL_ VCM SG_ 1519 WGTrckTPMThresCfg_UnderPres 24000;
BA_REL_ "GenSigTimeoutTime" BU_SG_REL_ VCM SG_ 1519 WGTrckTPMThresCfg_UnderPres 6000;
BA_REL_ "GenSigFirstTimeoutTime" BU_SG_REL_ VCM SG_ 1519 WGTrckTPMThresCfg_OverPres 24000;
BA_REL_ "GenSigTimeoutTime" BU_SG_REL_ VCM SG_ 1519 WGTrckTPMThresCfg_OverPres 6000;
BA_REL_ "GenSigFirstTimeoutTime" BU_SG_REL_ VCM SG_ 1356 WGTrail5TPMInf_Pressure 4800;
BA_REL_ "GenSigTimeoutTime" BU_SG_REL_ VCM SG_ 1356 WGTrail5TPMInf_Pressure 1200;
BA_REL_ "GenSigFirstTimeoutTime" BU_SG_REL_ VCM SG_ 1356 WGTrail5TPMInf_BatteryStatus 4800;
BA_REL_ "GenSigTimeoutTime" BU_SG_REL_ VCM SG_ 1356 WGTrail5TPMInf_BatteryStatus 1200;
BA_REL_ "GenSigFirstTimeoutTime" BU_SG_REL_ VCM SG_ 1356 WGTrail5TPMInf_TgtPressure 4800;
BA_REL_ "GenSigTimeoutTime" BU_SG_REL_ VCM SG_ 1356 WGTrail5TPMInf_TgtPressure 1200;
BA_REL_ "GenSigFirstTimeoutTime" BU_SG_REL_ VCM SG_ 1356 WGTrail5TPMInf_Temperature 4800;
BA_REL_ "GenSigTimeoutTime" BU_SG_REL_ VCM SG_ 1356 WGTrail5TPMInf_Temperature 1200;
BA_REL_ "GenSigFirstTimeoutTime" BU_SG_REL_ VCM SG_ 1356 WGTrail5TPMInf_TemperatureStatus 4800;
BA_REL_ "GenSigTimeoutTime" BU_SG_REL_ VCM SG_ 1356 WGTrail5TPMInf_TemperatureStatus 1200;
BA_REL_ "GenSigFirstTimeoutTime" BU_SG_REL_ VCM SG_ 1356 WGTrail5TPMInf_PressureStatus 4800;
BA_REL_ "GenSigTimeoutTime" BU_SG_REL_ VCM SG_ 1356 WGTrail5TPMInf_PressureStatus 1200;
BA_REL_ "GenSigFirstTimeoutTime" BU_SG_REL_ VCM SG_ 1356 WGTrail5TPMInf_FastPressureLoss 4800;
BA_REL_ "GenSigTimeoutTime" BU_SG_REL_ VCM SG_ 1356 WGTrail5TPMInf_FastPressureLoss 1200;
BA_REL_ "GenSigFirstTimeoutTime" BU_SG_REL_ VCM SG_ 1356 WGTrail5TPMInf_WheelLocation 4800;
BA_REL_ "GenSigTimeoutTime" BU_SG_REL_ VCM SG_ 1356 WGTrail5TPMInf_WheelLocation 1200;
BA_REL_ "GenSigFirstTimeoutTime" BU_SG_REL_ VCM SG_ 1356 WGTrail5TPMInf_SensorIDProgStat 4800;
BA_REL_ "GenSigTimeoutTime" BU_SG_REL_ VCM SG_ 1356 WGTrail5TPMInf_SensorIDProgStat 1200;
BA_REL_ "GenSigFirstTimeoutTime" BU_SG_REL_ VCM SG_ 1355 WGTrail4TPMInf_Temperature 4800;
BA_REL_ "GenSigTimeoutTime" BU_SG_REL_ VCM SG_ 1355 WGTrail4TPMInf_Temperature 1200;
BA_REL_ "GenSigFirstTimeoutTime" BU_SG_REL_ VCM SG_ 1355 WGTrail4TPMInf_TemperatureStatus 4800;
BA_REL_ "GenSigTimeoutTime" BU_SG_REL_ VCM SG_ 1355 WGTrail4TPMInf_TemperatureStatus 1200;
BA_REL_ "GenSigFirstTimeoutTime" BU_SG_REL_ VCM SG_ 1355 WGTrail4TPMInf_PressureStatus 4800;
BA_REL_ "GenSigTimeoutTime" BU_SG_REL_ VCM SG_ 1355 WGTrail4TPMInf_PressureStatus 1200;
BA_REL_ "GenSigFirstTimeoutTime" BU_SG_REL_ VCM SG_ 1355 WGTrail4TPMInf_Pressure 4800;
BA_REL_ "GenSigTimeoutTime" BU_SG_REL_ VCM SG_ 1355 WGTrail4TPMInf_Pressure 1200;
BA_REL_ "GenSigFirstTimeoutTime" BU_SG_REL_ VCM SG_ 1355 WGTrail4TPMInf_BatteryStatus 4800;
BA_REL_ "GenSigTimeoutTime" BU_SG_REL_ VCM SG_ 1355 WGTrail4TPMInf_BatteryStatus 1200;
BA_REL_ "GenSigFirstTimeoutTime" BU_SG_REL_ VCM SG_ 1355 WGTrail4TPMInf_SensorIDProgStat 4800;
BA_REL_ "GenSigTimeoutTime" BU_SG_REL_ VCM SG_ 1355 WGTrail4TPMInf_SensorIDProgStat 1200;
BA_REL_ "GenSigFirstTimeoutTime" BU_SG_REL_ VCM SG_ 1355 WGTrail4TPMInf_TgtPressure 4800;
BA_REL_ "GenSigTimeoutTime" BU_SG_REL_ VCM SG_ 1355 WGTrail4TPMInf_TgtPressure 1200;
BA_REL_ "GenSigFirstTimeoutTime" BU_SG_REL_ VCM SG_ 1355 WGTrail4TPMInf_WheelLocation 4800;
BA_REL_ "GenSigTimeoutTime" BU_SG_REL_ VCM SG_ 1355 WGTrail4TPMInf_WheelLocation 1200;
BA_REL_ "GenSigFirstTimeoutTime" BU_SG_REL_ VCM SG_ 1355 WGTrail4TPMInf_FastPressureLoss 4800;
BA_REL_ "GenSigTimeoutTime" BU_SG_REL_ VCM SG_ 1355 WGTrail4TPMInf_FastPressureLoss 1200;
BA_REL_ "GenSigFirstTimeoutTime" BU_SG_REL_ VCM SG_ 1354 WGTrail3TPMInf_FastPressureLoss 4800;
BA_REL_ "GenSigTimeoutTime" BU_SG_REL_ VCM SG_ 1354 WGTrail3TPMInf_FastPressureLoss 1200;
BA_REL_ "GenSigFirstTimeoutTime" BU_SG_REL_ VCM SG_ 1354 WGTrail3TPMInf_PressureStatus 4800;
BA_REL_ "GenSigTimeoutTime" BU_SG_REL_ VCM SG_ 1354 WGTrail3TPMInf_PressureStatus 1200;
BA_REL_ "GenSigFirstTimeoutTime" BU_SG_REL_ VCM SG_ 1354 WGTrail3TPMInf_SensorIDProgStat 4800;
BA_REL_ "GenSigTimeoutTime" BU_SG_REL_ VCM SG_ 1354 WGTrail3TPMInf_SensorIDProgStat 1200;
BA_REL_ "GenSigFirstTimeoutTime" BU_SG_REL_ VCM SG_ 1354 WGTrail3TPMInf_WheelLocation 4800;
BA_REL_ "GenSigTimeoutTime" BU_SG_REL_ VCM SG_ 1354 WGTrail3TPMInf_WheelLocation 1200;
BA_REL_ "GenSigFirstTimeoutTime" BU_SG_REL_ VCM SG_ 1354 WGTrail3TPMInf_TemperatureStatus 4800;
BA_REL_ "GenSigTimeoutTime" BU_SG_REL_ VCM SG_ 1354 WGTrail3TPMInf_TemperatureStatus 1200;
BA_REL_ "GenSigFirstTimeoutTime" BU_SG_REL_ VCM SG_ 1354 WGTrail3TPMInf_Pressure 4800;
BA_REL_ "GenSigTimeoutTime" BU_SG_REL_ VCM SG_ 1354 WGTrail3TPMInf_Pressure 1200;
BA_REL_ "GenSigFirstTimeoutTime" BU_SG_REL_ VCM SG_ 1354 WGTrail3TPMInf_BatteryStatus 4800;
BA_REL_ "GenSigTimeoutTime" BU_SG_REL_ VCM SG_ 1354 WGTrail3TPMInf_BatteryStatus 1200;
BA_REL_ "GenSigFirstTimeoutTime" BU_SG_REL_ VCM SG_ 1354 WGTrail3TPMInf_TgtPressure 4800;
BA_REL_ "GenSigTimeoutTime" BU_SG_REL_ VCM SG_ 1354 WGTrail3TPMInf_TgtPressure 1200;
BA_REL_ "GenSigFirstTimeoutTime" BU_SG_REL_ VCM SG_ 1354 WGTrail3TPMInf_Temperature 4800;
BA_REL_ "GenSigTimeoutTime" BU_SG_REL_ VCM SG_ 1354 WGTrail3TPMInf_Temperature 1200;
BA_REL_ "GenSigFirstTimeoutTime" BU_SG_REL_ VCM SG_ 1337 WGTrail2TPMInf_Pressure 4800;
BA_REL_ "GenSigTimeoutTime" BU_SG_REL_ VCM SG_ 1337 WGTrail2TPMInf_Pressure 1200;
BA_REL_ "GenSigFirstTimeoutTime" BU_SG_REL_ VCM SG_ 1337 WGTrail2TPMInf_WheelLocation 4800;
BA_REL_ "GenSigTimeoutTime" BU_SG_REL_ VCM SG_ 1337 WGTrail2TPMInf_WheelLocation 1200;
BA_REL_ "GenSigFirstTimeoutTime" BU_SG_REL_ VCM SG_ 1337 WGTrail2TPMInf_TgtPressure 4800;
BA_REL_ "GenSigTimeoutTime" BU_SG_REL_ VCM SG_ 1337 WGTrail2TPMInf_TgtPressure 1200;
BA_REL_ "GenSigFirstTimeoutTime" BU_SG_REL_ VCM SG_ 1337 WGTrail2TPMInf_Temperature 4800;
BA_REL_ "GenSigTimeoutTime" BU_SG_REL_ VCM SG_ 1337 WGTrail2TPMInf_Temperature 1200;
BA_REL_ "GenSigFirstTimeoutTime" BU_SG_REL_ VCM SG_ 1337 WGTrail2TPMInf_PressureStatus 4800;
BA_REL_ "GenSigTimeoutTime" BU_SG_REL_ VCM SG_ 1337 WGTrail2TPMInf_PressureStatus 1200;
BA_REL_ "GenSigFirstTimeoutTime" BU_SG_REL_ VCM SG_ 1337 WGTrail2TPMInf_FastPressureLoss 4800;
BA_REL_ "GenSigTimeoutTime" BU_SG_REL_ VCM SG_ 1337 WGTrail2TPMInf_FastPressureLoss 1200;
BA_REL_ "GenSigFirstTimeoutTime" BU_SG_REL_ VCM SG_ 1337 WGTrail2TPMInf_SensorIDProgStat 4800;
BA_REL_ "GenSigTimeoutTime" BU_SG_REL_ VCM SG_ 1337 WGTrail2TPMInf_SensorIDProgStat 1200;
BA_REL_ "GenSigFirstTimeoutTime" BU_SG_REL_ VCM SG_ 1337 WGTrail2TPMInf_TemperatureStatus 4800;
BA_REL_ "GenSigTimeoutTime" BU_SG_REL_ VCM SG_ 1337 WGTrail2TPMInf_TemperatureStatus 1200;
BA_REL_ "GenSigFirstTimeoutTime" BU_SG_REL_ VCM SG_ 1337 WGTrail2TPMInf_BatteryStatus 4800;
BA_REL_ "GenSigTimeoutTime" BU_SG_REL_ VCM SG_ 1337 WGTrail2TPMInf_BatteryStatus 1200;
BA_REL_ "GenSigFirstTimeoutTime" BU_SG_REL_ VCM SG_ 1336 WGTrail1TPMInf_BatteryStatus 4800;
BA_REL_ "GenSigTimeoutTime" BU_SG_REL_ VCM SG_ 1336 WGTrail1TPMInf_BatteryStatus 1200;
BA_REL_ "GenSigFirstTimeoutTime" BU_SG_REL_ VCM SG_ 1336 WGTrail1TPMInf_WheelLocation 4800;
BA_REL_ "GenSigTimeoutTime" BU_SG_REL_ VCM SG_ 1336 WGTrail1TPMInf_WheelLocation 1200;
BA_REL_ "GenSigFirstTimeoutTime" BU_SG_REL_ VCM SG_ 1336 WGTrail1TPMInf_Pressure 4800;
BA_REL_ "GenSigTimeoutTime" BU_SG_REL_ VCM SG_ 1336 WGTrail1TPMInf_Pressure 1200;
BA_REL_ "GenSigFirstTimeoutTime" BU_SG_REL_ VCM SG_ 1336 WGTrail1TPMInf_Temperature 4800;
BA_REL_ "GenSigTimeoutTime" BU_SG_REL_ VCM SG_ 1336 WGTrail1TPMInf_Temperature 1200;
BA_REL_ "GenSigFirstTimeoutTime" BU_SG_REL_ VCM SG_ 1336 WGTrail1TPMInf_TemperatureStatus 4800;
BA_REL_ "GenSigTimeoutTime" BU_SG_REL_ VCM SG_ 1336 WGTrail1TPMInf_TemperatureStatus 1200;
BA_REL_ "GenSigFirstTimeoutTime" BU_SG_REL_ VCM SG_ 1336 WGTrail1TPMInf_TgtPressure 4800;
BA_REL_ "GenSigTimeoutTime" BU_SG_REL_ VCM SG_ 1336 WGTrail1TPMInf_TgtPressure 1200;
BA_REL_ "GenSigFirstTimeoutTime" BU_SG_REL_ VCM SG_ 1336 WGTrail1TPMInf_SensorIDProgStat 4800;
BA_REL_ "GenSigTimeoutTime" BU_SG_REL_ VCM SG_ 1336 WGTrail1TPMInf_SensorIDProgStat 1200;
BA_REL_ "GenSigFirstTimeoutTime" BU_SG_REL_ VCM SG_ 1336 WGTrail1TPMInf_PressureStatus 4800;
BA_REL_ "GenSigTimeoutTime" BU_SG_REL_ VCM SG_ 1336 WGTrail1TPMInf_PressureStatus 1200;
BA_REL_ "GenSigFirstTimeoutTime" BU_SG_REL_ VCM SG_ 1336 WGTrail1TPMInf_FastPressureLoss 4800;
BA_REL_ "GenSigTimeoutTime" BU_SG_REL_ VCM SG_ 1336 WGTrail1TPMInf_FastPressureLoss 1200;
BA_REL_ "GenSigFirstTimeoutTime" BU_SG_REL_ VCM SG_ 1283 WGTPMPosOfWMResp_VehiclePos 4800;
BA_REL_ "GenSigTimeoutTime" BU_SG_REL_ VCM SG_ 1283 WGTPMPosOfWMResp_VehiclePos 1200;
BA_REL_ "GenSigFirstTimeoutTime" BU_SG_REL_ VCM SG_ 1283 WGTrailer4TPMLostCom 4800;
BA_REL_ "GenSigTimeoutTime" BU_SG_REL_ VCM SG_ 1283 WGTrailer4TPMLostCom 1200;
BA_REL_ "GenSigFirstTimeoutTime" BU_SG_REL_ VCM SG_ 1283 WGTruckTPMFailure 4800;
BA_REL_ "GenSigTimeoutTime" BU_SG_REL_ VCM SG_ 1283 WGTruckTPMFailure 1200;
BA_REL_ "GenSigFirstTimeoutTime" BU_SG_REL_ VCM SG_ 1283 WGTrailer5TPMLostCom 4800;
BA_REL_ "GenSigTimeoutTime" BU_SG_REL_ VCM SG_ 1283 WGTrailer5TPMLostCom 1200;
BA_REL_ "GenSigFirstTimeoutTime" BU_SG_REL_ VCM SG_ 1283 WGTrlr1TPMMatedStatus 4800;
BA_REL_ "GenSigTimeoutTime" BU_SG_REL_ VCM SG_ 1283 WGTrlr1TPMMatedStatus 1200;
BA_REL_ "GenSigFirstTimeoutTime" BU_SG_REL_ VCM SG_ 1283 WGTrailer5TPMFailure 4800;
BA_REL_ "GenSigTimeoutTime" BU_SG_REL_ VCM SG_ 1283 WGTrailer5TPMFailure 1200;
BA_REL_ "GenSigFirstTimeoutTime" BU_SG_REL_ VCM SG_ 1283 WGTrlr5TPMMatedStatus 4800;
BA_REL_ "GenSigTimeoutTime" BU_SG_REL_ VCM SG_ 1283 WGTrlr5TPMMatedStatus 1200;
BA_REL_ "GenSigFirstTimeoutTime" BU_SG_REL_ VCM SG_ 1283 WGTrailer1TPMLostCom 4800;
BA_REL_ "GenSigTimeoutTime" BU_SG_REL_ VCM SG_ 1283 WGTrailer1TPMLostCom 1200;
BA_REL_ "GenSigFirstTimeoutTime" BU_SG_REL_ VCM SG_ 1283 WGTrailer1TPMFailure 4800;
BA_REL_ "GenSigTimeoutTime" BU_SG_REL_ VCM SG_ 1283 WGTrailer1TPMFailure 1200;
BA_REL_ "GenSigFirstTimeoutTime" BU_SG_REL_ VCM SG_ 1283 WGTrailer2TPMFailure 4800;
BA_REL_ "GenSigTimeoutTime" BU_SG_REL_ VCM SG_ 1283 WGTrailer2TPMFailure 1200;
BA_REL_ "GenSigFirstTimeoutTime" BU_SG_REL_ VCM SG_ 1283 WGTrailer4TPMFailure 4800;
BA_REL_ "GenSigTimeoutTime" BU_SG_REL_ VCM SG_ 1283 WGTrailer4TPMFailure 1200;
BA_REL_ "GenSigFirstTimeoutTime" BU_SG_REL_ VCM SG_ 1283 WGTrailer2TPMLostCom 4800;
BA_REL_ "GenSigTimeoutTime" BU_SG_REL_ VCM SG_ 1283 WGTrailer2TPMLostCom 1200;
BA_REL_ "GenSigFirstTimeoutTime" BU_SG_REL_ VCM SG_ 1283 WGTrailer3TPMFailure 4800;
BA_REL_ "GenSigTimeoutTime" BU_SG_REL_ VCM SG_ 1283 WGTrailer3TPMFailure 1200;
BA_REL_ "GenSigFirstTimeoutTime" BU_SG_REL_ VCM SG_ 1283 WGTrlr3TPMMatedStatus 4800;
BA_REL_ "GenSigTimeoutTime" BU_SG_REL_ VCM SG_ 1283 WGTrlr3TPMMatedStatus 1200;
BA_REL_ "GenSigFirstTimeoutTime" BU_SG_REL_ VCM SG_ 1283 WGTPMPosOfWMResp_TireId 4800;
BA_REL_ "GenSigTimeoutTime" BU_SG_REL_ VCM SG_ 1283 WGTPMPosOfWMResp_TireId 1200;
BA_REL_ "GenSigFirstTimeoutTime" BU_SG_REL_ VCM SG_ 1283 WGTrailer3TPMLostCom 4800;
BA_REL_ "GenSigTimeoutTime" BU_SG_REL_ VCM SG_ 1283 WGTrailer3TPMLostCom 1200;
BA_REL_ "GenSigFirstTimeoutTime" BU_SG_REL_ VCM SG_ 1283 WGTrlr4TPMMatedStatus 4800;
BA_REL_ "GenSigTimeoutTime" BU_SG_REL_ VCM SG_ 1283 WGTrlr4TPMMatedStatus 1200;
BA_REL_ "GenSigFirstTimeoutTime" BU_SG_REL_ VCM SG_ 1283 WGTrlr2TPMMatedStatus 4800;
BA_REL_ "GenSigTimeoutTime" BU_SG_REL_ VCM SG_ 1283 WGTrlr2TPMMatedStatus 1200;
BA_REL_ "GenSigFirstTimeoutTime" BU_SG_REL_ VCM SG_ 1283 WGTPMPosOfWMResp_Status 4800;
BA_REL_ "GenSigTimeoutTime" BU_SG_REL_ VCM SG_ 1283 WGTPMPosOfWMResp_Status 1200;
BA_REL_ "GenSigFirstTimeoutTime" BU_SG_REL_ VCM SG_ 1518 Trail5WGTPMAxlTireCfg_Axle2 24000;
BA_REL_ "GenSigTimeoutTime" BU_SG_REL_ VCM SG_ 1518 Trail5WGTPMAxlTireCfg_Axle2 6000;
BA_REL_ "GenSigFirstTimeoutTime" BU_SG_REL_ VCM SG_ 1518 Trail5WGTPMAxlTireCfg_Axle3 24000;
BA_REL_ "GenSigTimeoutTime" BU_SG_REL_ VCM SG_ 1518 Trail5WGTPMAxlTireCfg_Axle3 6000;
BA_REL_ "GenSigFirstTimeoutTime" BU_SG_REL_ VCM SG_ 1518 Trail4WGTPMAxlTireCfg_Axle2 24000;
BA_REL_ "GenSigTimeoutTime" BU_SG_REL_ VCM SG_ 1518 Trail4WGTPMAxlTireCfg_Axle2 6000;
BA_REL_ "GenSigFirstTimeoutTime" BU_SG_REL_ VCM SG_ 1518 Trail4WGTPMAxlTireCfg_Axle3 24000;
BA_REL_ "GenSigTimeoutTime" BU_SG_REL_ VCM SG_ 1518 Trail4WGTPMAxlTireCfg_Axle3 6000;
BA_REL_ "GenSigFirstTimeoutTime" BU_SG_REL_ VCM SG_ 1518 Trail4WGTPMAxlTireCfg_Axle5 24000;
BA_REL_ "GenSigTimeoutTime" BU_SG_REL_ VCM SG_ 1518 Trail4WGTPMAxlTireCfg_Axle5 6000;
BA_REL_ "GenSigFirstTimeoutTime" BU_SG_REL_ VCM SG_ 1518 Trail5WGTPMAxlTireCfg_Axle4 24000;
BA_REL_ "GenSigTimeoutTime" BU_SG_REL_ VCM SG_ 1518 Trail5WGTPMAxlTireCfg_Axle4 6000;
BA_REL_ "GenSigFirstTimeoutTime" BU_SG_REL_ VCM SG_ 1518 Trail4WGTPMAxlTireCfg_Axle4 24000;
BA_REL_ "GenSigTimeoutTime" BU_SG_REL_ VCM SG_ 1518 Trail4WGTPMAxlTireCfg_Axle4 6000;
BA_REL_ "GenSigFirstTimeoutTime" BU_SG_REL_ VCM SG_ 1518 Trail5WGTPMAxlTireCfg_Axle5 24000;
BA_REL_ "GenSigTimeoutTime" BU_SG_REL_ VCM SG_ 1518 Trail5WGTPMAxlTireCfg_Axle5 6000;
BA_REL_ "GenSigFirstTimeoutTime" BU_SG_REL_ VCM SG_ 1518 Trail4WGTPMAxlTireCfg_Axle1 24000;
BA_REL_ "GenSigTimeoutTime" BU_SG_REL_ VCM SG_ 1518 Trail4WGTPMAxlTireCfg_Axle1 6000;
BA_REL_ "GenSigFirstTimeoutTime" BU_SG_REL_ VCM SG_ 1518 Trail5WGTPMAxlTireCfg_Axle1 24000;
BA_REL_ "GenSigTimeoutTime" BU_SG_REL_ VCM SG_ 1518 Trail5WGTPMAxlTireCfg_Axle1 6000;
BA_REL_ "GenSigFirstTimeoutTime" BU_SG_REL_ VCM SG_ 1520 WGTruckTPMAxlTireCfg_Axle5 24000;
BA_REL_ "GenSigTimeoutTime" BU_SG_REL_ VCM SG_ 1520 WGTruckTPMAxlTireCfg_Axle5 6000;
BA_REL_ "GenSigFirstTimeoutTime" BU_SG_REL_ VCM SG_ 1520 Trail3WGTPMAxlTireCfg_Axle2 24000;
BA_REL_ "GenSigTimeoutTime" BU_SG_REL_ VCM SG_ 1520 Trail3WGTPMAxlTireCfg_Axle2 6000;
BA_REL_ "GenSigFirstTimeoutTime" BU_SG_REL_ VCM SG_ 1520 WGTruckTPMAxlTireCfg_Axle4 24000;
BA_REL_ "GenSigTimeoutTime" BU_SG_REL_ VCM SG_ 1520 WGTruckTPMAxlTireCfg_Axle4 6000;
BA_REL_ "GenSigFirstTimeoutTime" BU_SG_REL_ VCM SG_ 1520 WGTruckTPMAxlTireCfg_Axle3 24000;
BA_REL_ "GenSigTimeoutTime" BU_SG_REL_ VCM SG_ 1520 WGTruckTPMAxlTireCfg_Axle3 6000;
BA_REL_ "GenSigFirstTimeoutTime" BU_SG_REL_ VCM SG_ 1520 Trail3WGTPMAxlTireCfg_Axle3 24000;
BA_REL_ "GenSigTimeoutTime" BU_SG_REL_ VCM SG_ 1520 Trail3WGTPMAxlTireCfg_Axle3 6000;
BA_REL_ "GenSigFirstTimeoutTime" BU_SG_REL_ VCM SG_ 1520 Trail1WGTPMAxlTireCfg_Axle4 24000;
BA_REL_ "GenSigTimeoutTime" BU_SG_REL_ VCM SG_ 1520 Trail1WGTPMAxlTireCfg_Axle4 6000;
BA_REL_ "GenSigFirstTimeoutTime" BU_SG_REL_ VCM SG_ 1520 WGTruckTPMAxlTireCfg_Axle2 24000;
BA_REL_ "GenSigTimeoutTime" BU_SG_REL_ VCM SG_ 1520 WGTruckTPMAxlTireCfg_Axle2 6000;
BA_REL_ "GenSigFirstTimeoutTime" BU_SG_REL_ VCM SG_ 1520 Trail2WGTPMAxlTireCfg_Axle3 24000;
BA_REL_ "GenSigTimeoutTime" BU_SG_REL_ VCM SG_ 1520 Trail2WGTPMAxlTireCfg_Axle3 6000;
BA_REL_ "GenSigFirstTimeoutTime" BU_SG_REL_ VCM SG_ 1520 Trail3WGTPMAxlTireCfg_Axle1 24000;
BA_REL_ "GenSigTimeoutTime" BU_SG_REL_ VCM SG_ 1520 Trail3WGTPMAxlTireCfg_Axle1 6000;
BA_REL_ "GenSigFirstTimeoutTime" BU_SG_REL_ VCM SG_ 1520 Trail2WGTPMAxlTireCfg_Axle2 24000;
BA_REL_ "GenSigTimeoutTime" BU_SG_REL_ VCM SG_ 1520 Trail2WGTPMAxlTireCfg_Axle2 6000;
BA_REL_ "GenSigFirstTimeoutTime" BU_SG_REL_ VCM SG_ 1520 Trail1WGTPMAxlTireCfg_Axle1 24000;
BA_REL_ "GenSigTimeoutTime" BU_SG_REL_ VCM SG_ 1520 Trail1WGTPMAxlTireCfg_Axle1 6000;
BA_REL_ "GenSigFirstTimeoutTime" BU_SG_REL_ VCM SG_ 1520 Trail1WGTPMAxlTireCfg_Axle5 24000;
BA_REL_ "GenSigTimeoutTime" BU_SG_REL_ VCM SG_ 1520 Trail1WGTPMAxlTireCfg_Axle5 6000;
BA_REL_ "GenSigFirstTimeoutTime" BU_SG_REL_ VCM SG_ 1520 Trail3WGTPMAxlTireCfg_Axle4 24000;
BA_REL_ "GenSigTimeoutTime" BU_SG_REL_ VCM SG_ 1520 Trail3WGTPMAxlTireCfg_Axle4 6000;
BA_REL_ "GenSigFirstTimeoutTime" BU_SG_REL_ VCM SG_ 1520 Trail2WGTPMAxlTireCfg_Axle5 24000;
BA_REL_ "GenSigTimeoutTime" BU_SG_REL_ VCM SG_ 1520 Trail2WGTPMAxlTireCfg_Axle5 6000;
BA_REL_ "GenSigFirstTimeoutTime" BU_SG_REL_ VCM SG_ 1520 Trail1WGTPMAxlTireCfg_Axle3 24000;
BA_REL_ "GenSigTimeoutTime" BU_SG_REL_ VCM SG_ 1520 Trail1WGTPMAxlTireCfg_Axle3 6000;
BA_REL_ "GenSigFirstTimeoutTime" BU_SG_REL_ VCM SG_ 1520 WGTruckTPMAxlTireCfg_Axle1 24000;
BA_REL_ "GenSigTimeoutTime" BU_SG_REL_ VCM SG_ 1520 WGTruckTPMAxlTireCfg_Axle1 6000;
BA_REL_ "GenSigFirstTimeoutTime" BU_SG_REL_ VCM SG_ 1520 Trail2WGTPMAxlTireCfg_Axle1 24000;
BA_REL_ "GenSigTimeoutTime" BU_SG_REL_ VCM SG_ 1520 Trail2WGTPMAxlTireCfg_Axle1 6000;
BA_REL_ "GenSigFirstTimeoutTime" BU_SG_REL_ VCM SG_ 1520 Trail2WGTPMAxlTireCfg_Axle4 24000;
BA_REL_ "GenSigTimeoutTime" BU_SG_REL_ VCM SG_ 1520 Trail2WGTPMAxlTireCfg_Axle4 6000;
BA_REL_ "GenSigFirstTimeoutTime" BU_SG_REL_ VCM SG_ 1520 Trail3WGTPMAxlTireCfg_Axle5 24000;
BA_REL_ "GenSigTimeoutTime" BU_SG_REL_ VCM SG_ 1520 Trail3WGTPMAxlTireCfg_Axle5 6000;
BA_REL_ "GenSigFirstTimeoutTime" BU_SG_REL_ VCM SG_ 1520 Trail1WGTPMAxlTireCfg_Axle2 24000;
BA_REL_ "GenSigTimeoutTime" BU_SG_REL_ VCM SG_ 1520 Trail1WGTPMAxlTireCfg_Axle2 6000;
BA_REL_ "GenSigFirstTimeoutTime" BU_SG_REL_ VCM SG_ 1335 WGTruckTPMInfo_TgtPressure 4800;
BA_REL_ "GenSigTimeoutTime" BU_SG_REL_ VCM SG_ 1335 WGTruckTPMInfo_TgtPressure 1200;
BA_REL_ "GenSigFirstTimeoutTime" BU_SG_REL_ VCM SG_ 1335 WGTruckTPMInfo_Temperature 4800;
BA_REL_ "GenSigTimeoutTime" BU_SG_REL_ VCM SG_ 1335 WGTruckTPMInfo_Temperature 1200;
BA_REL_ "GenSigFirstTimeoutTime" BU_SG_REL_ VCM SG_ 1335 WGTruckTPMInfo_WheelLocation 4800;
BA_REL_ "GenSigTimeoutTime" BU_SG_REL_ VCM SG_ 1335 WGTruckTPMInfo_WheelLocation 1200;
BA_REL_ "GenSigFirstTimeoutTime" BU_SG_REL_ VCM SG_ 1335 WGTruckTPMInfo_Pressure 4800;
BA_REL_ "GenSigTimeoutTime" BU_SG_REL_ VCM SG_ 1335 WGTruckTPMInfo_Pressure 1200;
BA_REL_ "GenSigFirstTimeoutTime" BU_SG_REL_ VCM SG_ 1335 WGTruckTPMInfo_TemperatureStatus 4800;
BA_REL_ "GenSigTimeoutTime" BU_SG_REL_ VCM SG_ 1335 WGTruckTPMInfo_TemperatureStatus 1200;
BA_REL_ "GenSigFirstTimeoutTime" BU_SG_REL_ VCM SG_ 1335 WGTruckTPMInfo_FastPressureLoss 4800;
BA_REL_ "GenSigTimeoutTime" BU_SG_REL_ VCM SG_ 1335 WGTruckTPMInfo_FastPressureLoss 1200;
BA_REL_ "GenSigFirstTimeoutTime" BU_SG_REL_ VCM SG_ 1335 WGTruckTPMInfo_PressureStatus 4800;
BA_REL_ "GenSigTimeoutTime" BU_SG_REL_ VCM SG_ 1335 WGTruckTPMInfo_PressureStatus 1200;
BA_REL_ "GenSigFirstTimeoutTime" BU_SG_REL_ VCM SG_ 1335 WGTruckTPMInfo_SensorIDProgStat 4800;
BA_REL_ "GenSigTimeoutTime" BU_SG_REL_ VCM SG_ 1335 WGTruckTPMInfo_SensorIDProgStat 1200;
BA_REL_ "GenSigFirstTimeoutTime" BU_SG_REL_ VCM SG_ 1335 WGTruckTPMInfo_BatteryStatus 4800;
BA_REL_ "GenSigTimeoutTime" BU_SG_REL_ VCM SG_ 1335 WGTruckTPMInfo_BatteryStatus 1200;
BA_REL_ "GenSigFirstTimeoutTime" BU_SG_REL_ CCIOM SG_ 1361 Set_LG6CutoffValue_ISig_4 12000;
BA_REL_ "GenSigTimeoutTime" BU_SG_REL_ CCIOM SG_ 1361 Set_LG6CutoffValue_ISig_4 3000;
BA_REL_ "GenSigFirstTimeoutTime" BU_SG_REL_ CCIOM SG_ 1361 Set_LG1CutoffValue_ISig_4 12000;
BA_REL_ "GenSigTimeoutTime" BU_SG_REL_ CCIOM SG_ 1361 Set_LG1CutoffValue_ISig_4 3000;
BA_REL_ "GenSigFirstTimeoutTime" BU_SG_REL_ CCIOM SG_ 1361 Set_LG3CutoffValue_ISig_4 12000;
BA_REL_ "GenSigTimeoutTime" BU_SG_REL_ CCIOM SG_ 1361 Set_LG3CutoffValue_ISig_4 3000;
BA_REL_ "GenSigFirstTimeoutTime" BU_SG_REL_ CCIOM SG_ 1361 Set_LG5CutoffValue_ISig_4 12000;
BA_REL_ "GenSigTimeoutTime" BU_SG_REL_ CCIOM SG_ 1361 Set_LG5CutoffValue_ISig_4 3000;
BA_REL_ "GenSigFirstTimeoutTime" BU_SG_REL_ CCIOM SG_ 1361 Set_LG4CutoffValue_ISig_4 12000;
BA_REL_ "GenSigTimeoutTime" BU_SG_REL_ CCIOM SG_ 1361 Set_LG4CutoffValue_ISig_4 3000;
BA_REL_ "GenSigFirstTimeoutTime" BU_SG_REL_ CCIOM SG_ 1361 Set_LG2CutoffValue_ISig_4 12000;
BA_REL_ "GenSigTimeoutTime" BU_SG_REL_ CCIOM SG_ 1361 Set_LG2CutoffValue_ISig_4 3000;
BA_REL_ "GenSigFirstTimeoutTime" BU_SG_REL_ CCIOM SG_ 1361 Set_EnergySetting_ISig_4 12000;
BA_REL_ "GenSigTimeoutTime" BU_SG_REL_ CCIOM SG_ 1361 Set_EnergySetting_ISig_4 3000;
BA_REL_ "GenSigFirstTimeoutTime" BU_SG_REL_ CCIOM SG_ 1267 KingPinUnlockCmd_CRC 3000;
BA_REL_ "GenSigTimeoutTime" BU_SG_REL_ CCIOM SG_ 1267 KingPinUnlockCmd_CRC 600;
BA_REL_ "GenSigFirstTimeoutTime" BU_SG_REL_ CCIOM SG_ 1267 AirIntakeSolenoidValve_cmd 3000;
BA_REL_ "GenSigTimeoutTime" BU_SG_REL_ CCIOM SG_ 1267 AirIntakeSolenoidValve_cmd 600;
BA_REL_ "GenSigFirstTimeoutTime" BU_SG_REL_ RCIOM SG_ 1267 TransmissionActualGearRatio_ISig 3000;
BA_REL_ "GenSigTimeoutTime" BU_SG_REL_ RCIOM SG_ 1267 TransmissionActualGearRatio_ISig 600;
BA_REL_ "GenSigFirstTimeoutTime" BU_SG_REL_ CCIOM SG_ 1267 KingPinUnlockCmd_SqC 3000;
BA_REL_ "GenSigTimeoutTime" BU_SG_REL_ CCIOM SG_ 1267 KingPinUnlockCmd_SqC 600;
BA_REL_ "GenSigFirstTimeoutTime" BU_SG_REL_ CCIOM SG_ 1267 KingPinUnlockCmd_Rqst 3000;
BA_REL_ "GenSigTimeoutTime" BU_SG_REL_ CCIOM SG_ 1267 KingPinUnlockCmd_Rqst 600;
BA_REL_ "GenSigFirstTimeoutTime" BU_SG_REL_ RCIOM SG_ 1267 PreventECSFuncForSWDL_rqst 3000;
BA_REL_ "GenSigTimeoutTime" BU_SG_REL_ RCIOM SG_ 1267 PreventECSFuncForSWDL_rqst 600;
BA_REL_ "GenSigFirstTimeoutTime" BU_SG_REL_ CCIOM SG_ 1267 AutoShutOffAnswerInput_ISig_4 3000;
BA_REL_ "GenSigTimeoutTime" BU_SG_REL_ CCIOM SG_ 1267 AutoShutOffAnswerInput_ISig_4 600;
BA_REL_ "GenSigFirstTimeoutTime" BU_SG_REL_ RCIOM SG_ 954 DumpSwitchChangeReq_ISig_4 3000;
BA_REL_ "GenSigTimeoutTime" BU_SG_REL_ RCIOM SG_ 954 DumpSwitchChangeReq_ISig_4 600;
BA_REL_ "GenSigFirstTimeoutTime" BU_SG_REL_ FCIOM SG_ 954 LCP_Status_ISig_4 3000;
BA_REL_ "GenSigTimeoutTime" BU_SG_REL_ FCIOM SG_ 954 LCP_Status_ISig_4 600;
BA_REL_ "GenSigFirstTimeoutTime" BU_SG_REL_ RCIOM SG_ 954 LCP_Status_ISig_4 3000;
BA_REL_ "GenSigTimeoutTime" BU_SG_REL_ RCIOM SG_ 954 LCP_Status_ISig_4 600;
BA_REL_ "GenSigFirstTimeoutTime" BU_SG_REL_ FCIOM SG_ 954 CAHighBeamFlash_cmd 3000;
BA_REL_ "GenSigTimeoutTime" BU_SG_REL_ FCIOM SG_ 954 CAHighBeamFlash_cmd 600;
BA_REL_ "GenSigFirstTimeoutTime" BU_SG_REL_ FCIOM SG_ 954 PTI_DRL_cmd 3000;
BA_REL_ "GenSigTimeoutTime" BU_SG_REL_ FCIOM SG_ 954 PTI_DRL_cmd 600;
BA_REL_ "GenSigFirstTimeoutTime" BU_SG_REL_ FCIOM SG_ 954 HeadLampDeicingControl_rqst 3000;
BA_REL_ "GenSigTimeoutTime" BU_SG_REL_ FCIOM SG_ 954 HeadLampDeicingControl_rqst 600;
BA_REL_ "GenSigFirstTimeoutTime" BU_SG_REL_ CCIOM SG_ 677 EngineStarterMode_ISig_4 3000;
BA_REL_ "GenSigTimeoutTime" BU_SG_REL_ CCIOM SG_ 677 EngineStarterMode_ISig_4 120;
BA_REL_ "GenSigFirstTimeoutTime" BU_SG_REL_ CCIOM SG_ 1363 PredeliveryModeIndication_cmd_IS 24000;
BA_REL_ "GenSigTimeoutTime" BU_SG_REL_ CCIOM SG_ 1363 PredeliveryModeIndication_cmd_IS 6000;
BA_REL_ "GenSigFirstTimeoutTime" BU_SG_REL_ FCIOM SG_ 535 DirectionIndicatorLightsStatus_I 3000;
BA_REL_ "GenSigTimeoutTime" BU_SG_REL_ FCIOM SG_ 535 DirectionIndicatorLightsStatus_I 180;
BA_REL_ "GenSigFirstTimeoutTime" BU_SG_REL_ RCIOM SG_ 535 DirectionIndicatorLightsStatus_I 3000;
BA_REL_ "GenSigTimeoutTime" BU_SG_REL_ RCIOM SG_ 535 DirectionIndicatorLightsStatus_I 180;
BA_REL_ "GenSigFirstTimeoutTime" BU_SG_REL_ FCIOM SG_ 535 HeadlightAngle_cmd 3000;
BA_REL_ "GenSigTimeoutTime" BU_SG_REL_ FCIOM SG_ 535 HeadlightAngle_cmd 180;
BA_REL_ "GenSigFirstTimeoutTime" BU_SG_REL_ CCIOM SG_ 1381 BattEnergySetLevel_input_ISig_4 12000;
BA_REL_ "GenSigTimeoutTime" BU_SG_REL_ CCIOM SG_ 1381 BattEnergySetLevel_input_ISig_4 3000;
BA_REL_ "GenSigFirstTimeoutTime" BU_SG_REL_ FCIOM SG_ 1381 AmbientAirTemperature_ISig_4 12000;
BA_REL_ "GenSigTimeoutTime" BU_SG_REL_ FCIOM SG_ 1381 AmbientAirTemperature_ISig_4 6000;
BA_REL_ "GenSigFirstTimeoutTime" BU_SG_REL_ BPMU SG_ 1381 AmbientAirTemperature_ISig_4 12000;
BA_REL_ "GenSigTimeoutTime" BU_SG_REL_ BPMU SG_ 1381 AmbientAirTemperature_ISig_4 3000;
BA_REL_ "GenSigFirstTimeoutTime" BU_SG_REL_ RCIOM SG_ 1381 AmbientAirTemperature_ISig_4 12000;
BA_REL_ "GenSigTimeoutTime" BU_SG_REL_ RCIOM SG_ 1381 AmbientAirTemperature_ISig_4 6000;
BA_REL_ "GenSigFirstTimeoutTime" BU_SG_REL_ WSGW SG_ 1381 AmbientAirTemperature_ISig_4 12000;
BA_REL_ "GenSigTimeoutTime" BU_SG_REL_ WSGW SG_ 1381 AmbientAirTemperature_ISig_4 3000;
BA_REL_ "GenSigFirstTimeoutTime" BU_SG_REL_ CCIOM SG_ 1381 AmbientAirTemperature_ISig_4 12000;
BA_REL_ "GenSigTimeoutTime" BU_SG_REL_ CCIOM SG_ 1381 AmbientAirTemperature_ISig_4 3000;
BA_REL_ "GenSigFirstTimeoutTime" BU_SG_REL_ CCIOM SG_ 1381 EnergyForNextCrank_ISig_4 12000;
BA_REL_ "GenSigTimeoutTime" BU_SG_REL_ CCIOM SG_ 1381 EnergyForNextCrank_ISig_4 3000;
BA_REL_ "GenSigFirstTimeoutTime" BU_SG_REL_ CCIOM SG_ 1381 MainBatteryResetPos 12000;
BA_REL_ "GenSigTimeoutTime" BU_SG_REL_ CCIOM SG_ 1381 MainBatteryResetPos 3000;
BA_REL_ "GenSigFirstTimeoutTime" BU_SG_REL_ FCIOM SG_ 519 GlareFreeArea02_LeftAngle 3000;
BA_REL_ "GenSigTimeoutTime" BU_SG_REL_ FCIOM SG_ 519 GlareFreeArea02_LeftAngle 120;
BA_REL_ "GenSigFirstTimeoutTime" BU_SG_REL_ FCIOM SG_ 519 AdaptiveMainBeamRight_cmd 3000;
BA_REL_ "GenSigTimeoutTime" BU_SG_REL_ FCIOM SG_ 519 AdaptiveMainBeamRight_cmd 120;
BA_REL_ "GenSigFirstTimeoutTime" BU_SG_REL_ FCIOM SG_ 519 AdaptiveMainBeamLeft_cmd 3000;
BA_REL_ "GenSigTimeoutTime" BU_SG_REL_ FCIOM SG_ 519 AdaptiveMainBeamLeft_cmd 120;
BA_REL_ "GenSigFirstTimeoutTime" BU_SG_REL_ FCIOM SG_ 519 GlareFreeArea02_Distance 3000;
BA_REL_ "GenSigTimeoutTime" BU_SG_REL_ FCIOM SG_ 519 GlareFreeArea02_Distance 120;
BA_REL_ "GenSigFirstTimeoutTime" BU_SG_REL_ FCIOM SG_ 519 GlareFreeArea02_RightAngle 3000;
BA_REL_ "GenSigTimeoutTime" BU_SG_REL_ FCIOM SG_ 519 GlareFreeArea02_RightAngle 120;
BA_REL_ "GenSigFirstTimeoutTime" BU_SG_REL_ FCIOM SG_ 518 GlareFreeArea03_Distance 3000;
BA_REL_ "GenSigTimeoutTime" BU_SG_REL_ FCIOM SG_ 518 GlareFreeArea03_Distance 120;
BA_REL_ "GenSigFirstTimeoutTime" BU_SG_REL_ FCIOM SG_ 518 GlareFreeArea01_Distance 3000;
BA_REL_ "GenSigTimeoutTime" BU_SG_REL_ FCIOM SG_ 518 GlareFreeArea01_Distance 120;
BA_REL_ "GenSigFirstTimeoutTime" BU_SG_REL_ FCIOM SG_ 518 GlareFreeArea01_LeftAngle 3000;
BA_REL_ "GenSigTimeoutTime" BU_SG_REL_ FCIOM SG_ 518 GlareFreeArea01_LeftAngle 120;
BA_REL_ "GenSigFirstTimeoutTime" BU_SG_REL_ FCIOM SG_ 518 GlareFreeArea03_RightAngle 3000;
BA_REL_ "GenSigTimeoutTime" BU_SG_REL_ FCIOM SG_ 518 GlareFreeArea03_RightAngle 120;
BA_REL_ "GenSigFirstTimeoutTime" BU_SG_REL_ FCIOM SG_ 518 GlareFreeArea03_LeftAngle 3000;
BA_REL_ "GenSigTimeoutTime" BU_SG_REL_ FCIOM SG_ 518 GlareFreeArea03_LeftAngle 120;
BA_REL_ "GenSigFirstTimeoutTime" BU_SG_REL_ FCIOM SG_ 518 GlareFreeArea01_RightAngle 3000;
BA_REL_ "GenSigTimeoutTime" BU_SG_REL_ FCIOM SG_ 518 GlareFreeArea01_RightAngle 120;
BA_REL_ "GenSigFirstTimeoutTime" BU_SG_REL_ WSGW SG_ 1370 TPMSetPresThresCfg_VehiclePos_IS 12000;
BA_REL_ "GenSigTimeoutTime" BU_SG_REL_ WSGW SG_ 1370 TPMSetPresThresCfg_VehiclePos_IS 3000;
BA_REL_ "GenSigFirstTimeoutTime" BU_SG_REL_ WSGW SG_ 1370 TPMSetPresThresCfg_ExtUnderPres_ 12000;
BA_REL_ "GenSigTimeoutTime" BU_SG_REL_ WSGW SG_ 1370 TPMSetPresThresCfg_ExtUnderPres_ 3000;
BA_REL_ "GenSigFirstTimeoutTime" BU_SG_REL_ WSGW SG_ 1370 TPMSetPresThresCfg_OverPres_ISig 12000;
BA_REL_ "GenSigTimeoutTime" BU_SG_REL_ WSGW SG_ 1370 TPMSetPresThresCfg_OverPres_ISig 3000;
BA_REL_ "GenSigFirstTimeoutTime" BU_SG_REL_ WSGW SG_ 1370 TPMSetPresThresCfg_AxleNr_ISig_4 12000;
BA_REL_ "GenSigTimeoutTime" BU_SG_REL_ WSGW SG_ 1370 TPMSetPresThresCfg_AxleNr_ISig_4 3000;
BA_REL_ "GenSigFirstTimeoutTime" BU_SG_REL_ WSGW SG_ 1370 TPMSetPresThresCfg_ExtOverPres_I 12000;
BA_REL_ "GenSigTimeoutTime" BU_SG_REL_ WSGW SG_ 1370 TPMSetPresThresCfg_ExtOverPres_I 3000;
BA_REL_ "GenSigFirstTimeoutTime" BU_SG_REL_ WSGW SG_ 1370 TPMSetPresThresCfg_UnderPres_ISi 12000;
BA_REL_ "GenSigTimeoutTime" BU_SG_REL_ WSGW SG_ 1370 TPMSetPresThresCfg_UnderPres_ISi 3000;
BA_REL_ "GenSigFirstTimeoutTime" BU_SG_REL_ WSGW SG_ 1373 TPMPosOfWMReq_VehiclePos_ISig_4 12000;
BA_REL_ "GenSigTimeoutTime" BU_SG_REL_ WSGW SG_ 1373 TPMPosOfWMReq_VehiclePos_ISig_4 3000;
BA_REL_ "GenSigFirstTimeoutTime" BU_SG_REL_ WSGW SG_ 1373 TPMPosOfWMReq_TireId_ISig_4 12000;
BA_REL_ "GenSigTimeoutTime" BU_SG_REL_ WSGW SG_ 1373 TPMPosOfWMReq_TireId_ISig_4 3000;
BA_REL_ "GenSigFirstTimeoutTime" BU_SG_REL_ WSGW SG_ 1373 TPMSetAxleRefPres_Axle2_ISig_4 12000;
BA_REL_ "GenSigTimeoutTime" BU_SG_REL_ WSGW SG_ 1373 TPMSetAxleRefPres_Axle2_ISig_4 3000;
BA_REL_ "GenSigFirstTimeoutTime" BU_SG_REL_ WSGW SG_ 1373 TPMSetAxleRefPres_Axle3_ISig_4 12000;
BA_REL_ "GenSigTimeoutTime" BU_SG_REL_ WSGW SG_ 1373 TPMSetAxleRefPres_Axle3_ISig_4 3000;
BA_REL_ "GenSigFirstTimeoutTime" BU_SG_REL_ WSGW SG_ 1373 TPMSetAxleRefPres_Axle4_ISig_4 12000;
BA_REL_ "GenSigTimeoutTime" BU_SG_REL_ WSGW SG_ 1373 TPMSetAxleRefPres_Axle4_ISig_4 3000;
BA_REL_ "GenSigFirstTimeoutTime" BU_SG_REL_ WSGW SG_ 1373 TPMSetAxleRefPres_Axle5_ISig_4 12000;
BA_REL_ "GenSigTimeoutTime" BU_SG_REL_ WSGW SG_ 1373 TPMSetAxleRefPres_Axle5_ISig_4 3000;
BA_REL_ "GenSigFirstTimeoutTime" BU_SG_REL_ WSGW SG_ 1373 TPMSetAxleRefPres_Axle1_ISig_4 12000;
BA_REL_ "GenSigTimeoutTime" BU_SG_REL_ WSGW SG_ 1373 TPMSetAxleRefPres_Axle1_ISig_4 3000;
BA_REL_ "GenSigFirstTimeoutTime" BU_SG_REL_ WSGW SG_ 1373 TPMSetAxleRefPres_VehiclePos_ISi 12000;
BA_REL_ "GenSigTimeoutTime" BU_SG_REL_ WSGW SG_ 1373 TPMSetAxleRefPres_VehiclePos_ISi 3000;
BA_REL_ "GenSigFirstTimeoutTime" BU_SG_REL_ RCIOM SG_ 1249 TransferCasePTOEngaged 3000;
BA_REL_ "GenSigTimeoutTime" BU_SG_REL_ RCIOM SG_ 1249 TransferCasePTOEngaged 600;
BA_REL_ "GenSigFirstTimeoutTime" BU_SG_REL_ RCIOM SG_ 1249 EhrasTagAxleLoweringInhibit 3000;
BA_REL_ "GenSigTimeoutTime" BU_SG_REL_ RCIOM SG_ 1249 EhrasTagAxleLoweringInhibit 600;
BA_REL_ "GenSigFirstTimeoutTime" BU_SG_REL_ RCIOM SG_ 1249 ExtECSRequestPressureUpdate 3000;
BA_REL_ "GenSigTimeoutTime" BU_SG_REL_ RCIOM SG_ 1249 ExtECSRequestPressureUpdate 600;
BA_REL_ "GenSigFirstTimeoutTime" BU_SG_REL_ FCIOM SG_ 1249 HeadLampFanControl_rqst 3000;
BA_REL_ "GenSigTimeoutTime" BU_SG_REL_ FCIOM SG_ 1249 HeadLampFanControl_rqst 600;
BA_REL_ "GenSigFirstTimeoutTime" BU_SG_REL_ RCIOM SG_ 1249 BBAirDumpRequest 3000;
BA_REL_ "GenSigTimeoutTime" BU_SG_REL_ RCIOM SG_ 1249 BBAirDumpRequest 600;
BA_REL_ "GenSigFirstTimeoutTime" BU_SG_REL_ RCIOM SG_ 1249 ApproachLight_rqst 3000;
BA_REL_ "GenSigTimeoutTime" BU_SG_REL_ RCIOM SG_ 1249 ApproachLight_rqst 600;
BA_REL_ "GenSigFirstTimeoutTime" BU_SG_REL_ CCIOM SG_ 1249 FrAxle2WheelDriveRequest 3000;
BA_REL_ "GenSigTimeoutTime" BU_SG_REL_ CCIOM SG_ 1249 FrAxle2WheelDriveRequest 600;
BA_REL_ "GenSigFirstTimeoutTime" BU_SG_REL_ RCIOM SG_ 1249 EhrasPusherAxleLoweringInhibit 3000;
BA_REL_ "GenSigTimeoutTime" BU_SG_REL_ RCIOM SG_ 1249 EhrasPusherAxleLoweringInhibit 600;
BA_REL_ "GenSigFirstTimeoutTime" BU_SG_REL_ CCIOM SG_ 1249 LivBatteryChargingStat_rqst 3000;
BA_REL_ "GenSigTimeoutTime" BU_SG_REL_ CCIOM SG_ 1249 LivBatteryChargingStat_rqst 600;
BA_REL_ "GenSigFirstTimeoutTime" BU_SG_REL_ CCIOM SG_ 1249 ClutchSwitch2Stat 3000;
BA_REL_ "GenSigTimeoutTime" BU_SG_REL_ CCIOM SG_ 1249 ClutchSwitch2Stat 600;
BA_REL_ "GenSigFirstTimeoutTime" BU_SG_REL_ CCIOM SG_ 1249 SideMarkersLights_cmd 3000;
BA_REL_ "GenSigTimeoutTime" BU_SG_REL_ CCIOM SG_ 1249 SideMarkersLights_cmd 600;
BA_REL_ "GenSigFirstTimeoutTime" BU_SG_REL_ RCIOM SG_ 1249 BBEcsForceStandstillFilterReq 3000;
BA_REL_ "GenSigTimeoutTime" BU_SG_REL_ RCIOM SG_ 1249 BBEcsForceStandstillFilterReq 600;
BA_REL_ "GenSigFirstTimeoutTime" BU_SG_REL_ CCIOM SG_ 1249 BBEcsForceStandstillFilterReq 3000;
BA_REL_ "GenSigTimeoutTime" BU_SG_REL_ CCIOM SG_ 1249 BBEcsForceStandstillFilterReq 600;
BA_REL_ "GenSigFirstTimeoutTime" BU_SG_REL_ CCIOM SG_ 944 ShortStopHeater_cmd_ISig_4 3000;
BA_REL_ "GenSigTimeoutTime" BU_SG_REL_ CCIOM SG_ 944 ShortStopHeater_cmd_ISig_4 300;
BA_REL_ "GenSigFirstTimeoutTime" BU_SG_REL_ RCIOM SG_ 944 LoadDistributionRequested_ISig_4 3000;
BA_REL_ "GenSigTimeoutTime" BU_SG_REL_ RCIOM SG_ 944 LoadDistributionRequested_ISig_4 500;
BA_REL_ "GenSigFirstTimeoutTime" BU_SG_REL_ CCIOM SG_ 390 FrontAxleRightWheelSpeed_UB_ISig 3000;
BA_REL_ "GenSigTimeoutTime" BU_SG_REL_ CCIOM SG_ 390 FrontAxleRightWheelSpeed_UB_ISig 60;
BA_REL_ "GenSigFirstTimeoutTime" BU_SG_REL_ FCIOM SG_ 390 CityHorn_cmd 3000;
BA_REL_ "GenSigTimeoutTime" BU_SG_REL_ FCIOM SG_ 390 CityHorn_cmd 500;
BA_REL_ "GenSigFirstTimeoutTime" BU_SG_REL_ CCIOM SG_ 390 BrakeSwitch_ISig_4 3000;
BA_REL_ "GenSigTimeoutTime" BU_SG_REL_ CCIOM SG_ 390 BrakeSwitch_ISig_4 60;
BA_REL_ "GenSigFirstTimeoutTime" BU_SG_REL_ RCIOM SG_ 390 LevelRequest_FrontAxle_ISig_4 3000;
BA_REL_ "GenSigTimeoutTime" BU_SG_REL_ RCIOM SG_ 390 LevelRequest_FrontAxle_ISig_4 500;
BA_REL_ "GenSigFirstTimeoutTime" BU_SG_REL_ CCIOM SG_ 390 FrontAxleRightWheelSpeed_ISig_4 3000;
BA_REL_ "GenSigTimeoutTime" BU_SG_REL_ CCIOM SG_ 390 FrontAxleRightWheelSpeed_ISig_4 500;
BA_REL_ "GenSigFirstTimeoutTime" BU_SG_REL_ CCIOM SG_ 390 FrontAxleLeftWheelSpeed_ISig_4 3000;
BA_REL_ "GenSigTimeoutTime" BU_SG_REL_ CCIOM SG_ 390 FrontAxleLeftWheelSpeed_ISig_4 500;
BA_REL_ "GenSigFirstTimeoutTime" BU_SG_REL_ RCIOM SG_ 390 FPBRChangeReq_ISig_4 3000;
BA_REL_ "GenSigTimeoutTime" BU_SG_REL_ RCIOM SG_ 390 FPBRChangeReq_ISig_4 60;
BA_REL_ "GenSigFirstTimeoutTime" BU_SG_REL_ FCIOM SG_ 390 AuxiliaryHorn_cmd 3000;
BA_REL_ "GenSigTimeoutTime" BU_SG_REL_ FCIOM SG_ 390 AuxiliaryHorn_cmd 500;
BA_REL_ "GenSigFirstTimeoutTime" BU_SG_REL_ RCIOM SG_ 390 LevelRequest_RearAxle_ISig_4 3000;
BA_REL_ "GenSigTimeoutTime" BU_SG_REL_ RCIOM SG_ 390 LevelRequest_RearAxle_ISig_4 500;
BA_REL_ "GenSigFirstTimeoutTime" BU_SG_REL_ RCIOM SG_ 390 LevelRequest_RollRequest_ISig_4 3000;
BA_REL_ "GenSigTimeoutTime" BU_SG_REL_ RCIOM SG_ 390 LevelRequest_RollRequest_ISig_4 500;
BA_REL_ "GenSigFirstTimeoutTime" BU_SG_REL_ CCIOM SG_ 390 FrontAxleLeftWheelSpeed_UB_ISig_ 3000;
BA_REL_ "GenSigTimeoutTime" BU_SG_REL_ CCIOM SG_ 390 FrontAxleLeftWheelSpeed_UB_ISig_ 60;
BA_REL_ "GenSigFirstTimeoutTime" BU_SG_REL_ CCIOM SG_ 389 FrontWheelDriveRequest 3000;
BA_REL_ "GenSigTimeoutTime" BU_SG_REL_ CCIOM SG_ 389 FrontWheelDriveRequest 60;
BA_REL_ "GenSigFirstTimeoutTime" BU_SG_REL_ RCIOM SG_ 389 RearAxleLeftWheelSpeed_ISig_4 3000;
BA_REL_ "GenSigTimeoutTime" BU_SG_REL_ RCIOM SG_ 389 RearAxleLeftWheelSpeed_ISig_4 500;
BA_REL_ "GenSigFirstTimeoutTime" BU_SG_REL_ CCIOM SG_ 389 RearAxleLeftWheelSpeed_ISig_4 3000;
BA_REL_ "GenSigTimeoutTime" BU_SG_REL_ CCIOM SG_ 389 RearAxleLeftWheelSpeed_ISig_4 500;
BA_REL_ "GenSigFirstTimeoutTime" BU_SG_REL_ RCIOM SG_ 389 RearAxleRightWheelSpeed_ISig_4 3000;
BA_REL_ "GenSigTimeoutTime" BU_SG_REL_ RCIOM SG_ 389 RearAxleRightWheelSpeed_ISig_4 500;
BA_REL_ "GenSigFirstTimeoutTime" BU_SG_REL_ CCIOM SG_ 389 RearAxleRightWheelSpeed_ISig_4 3000;
BA_REL_ "GenSigTimeoutTime" BU_SG_REL_ CCIOM SG_ 389 RearAxleRightWheelSpeed_ISig_4 500;
BA_REL_ "GenSigFirstTimeoutTime" BU_SG_REL_ RCIOM SG_ 389 KneelingChangeRequest_ISig_4 3000;
BA_REL_ "GenSigTimeoutTime" BU_SG_REL_ RCIOM SG_ 389 KneelingChangeRequest_ISig_4 120;
BA_REL_ "GenSigFirstTimeoutTime" BU_SG_REL_ FCIOM SG_ 1364 HoursUTC_ISig_4 6000;
BA_REL_ "GenSigTimeoutTime" BU_SG_REL_ FCIOM SG_ 1364 HoursUTC_ISig_4 1500;
BA_REL_ "GenSigFirstTimeoutTime" BU_SG_REL_ RCIOM SG_ 1364 HoursUTC_ISig_4 6000;
BA_REL_ "GenSigTimeoutTime" BU_SG_REL_ RCIOM SG_ 1364 HoursUTC_ISig_4 1500;
BA_REL_ "GenSigFirstTimeoutTime" BU_SG_REL_ CCIOM SG_ 1364 HoursUTC_ISig_4 6000;
BA_REL_ "GenSigTimeoutTime" BU_SG_REL_ CCIOM SG_ 1364 HoursUTC_ISig_4 1500;
BA_REL_ "GenSigFirstTimeoutTime" BU_SG_REL_ BPMU SG_ 1364 HoursUTC_ISig_4 6000;
BA_REL_ "GenSigTimeoutTime" BU_SG_REL_ BPMU SG_ 1364 HoursUTC_ISig_4 1500;
BA_REL_ "GenSigFirstTimeoutTime" BU_SG_REL_ WSGW SG_ 1364 HoursUTC_ISig_4 6000;
BA_REL_ "GenSigTimeoutTime" BU_SG_REL_ WSGW SG_ 1364 HoursUTC_ISig_4 1500;
BA_REL_ "GenSigFirstTimeoutTime" BU_SG_REL_ RCIOM SG_ 1364 RoadInclination_ISig_4 6000;
BA_REL_ "GenSigTimeoutTime" BU_SG_REL_ RCIOM SG_ 1364 RoadInclination_ISig_4 1500;
BA_REL_ "GenSigFirstTimeoutTime" BU_SG_REL_ BPMU SG_ 1364 MonthUTC_ISig_4 6000;
BA_REL_ "GenSigTimeoutTime" BU_SG_REL_ BPMU SG_ 1364 MonthUTC_ISig_4 1500;
BA_REL_ "GenSigFirstTimeoutTime" BU_SG_REL_ WSGW SG_ 1364 MonthUTC_ISig_4 6000;
BA_REL_ "GenSigTimeoutTime" BU_SG_REL_ WSGW SG_ 1364 MonthUTC_ISig_4 1500;
BA_REL_ "GenSigFirstTimeoutTime" BU_SG_REL_ RCIOM SG_ 1364 MonthUTC_ISig_4 6000;
BA_REL_ "GenSigTimeoutTime" BU_SG_REL_ RCIOM SG_ 1364 MonthUTC_ISig_4 1500;
BA_REL_ "GenSigFirstTimeoutTime" BU_SG_REL_ FCIOM SG_ 1364 MonthUTC_ISig_4 6000;
BA_REL_ "GenSigTimeoutTime" BU_SG_REL_ FCIOM SG_ 1364 MonthUTC_ISig_4 1500;
BA_REL_ "GenSigFirstTimeoutTime" BU_SG_REL_ CCIOM SG_ 1364 MonthUTC_ISig_4 6000;
BA_REL_ "GenSigTimeoutTime" BU_SG_REL_ CCIOM SG_ 1364 MonthUTC_ISig_4 1500;
BA_REL_ "GenSigFirstTimeoutTime" BU_SG_REL_ CCIOM SG_ 1364 YearUTC_ISig_4 6000;
BA_REL_ "GenSigTimeoutTime" BU_SG_REL_ CCIOM SG_ 1364 YearUTC_ISig_4 1500;
BA_REL_ "GenSigFirstTimeoutTime" BU_SG_REL_ FCIOM SG_ 1364 YearUTC_ISig_4 6000;
BA_REL_ "GenSigTimeoutTime" BU_SG_REL_ FCIOM SG_ 1364 YearUTC_ISig_4 1500;
BA_REL_ "GenSigFirstTimeoutTime" BU_SG_REL_ RCIOM SG_ 1364 YearUTC_ISig_4 6000;
BA_REL_ "GenSigTimeoutTime" BU_SG_REL_ RCIOM SG_ 1364 YearUTC_ISig_4 1500;
BA_REL_ "GenSigFirstTimeoutTime" BU_SG_REL_ WSGW SG_ 1364 YearUTC_ISig_4 6000;
BA_REL_ "GenSigTimeoutTime" BU_SG_REL_ WSGW SG_ 1364 YearUTC_ISig_4 1500;
BA_REL_ "GenSigFirstTimeoutTime" BU_SG_REL_ BPMU SG_ 1364 YearUTC_ISig_4 6000;
BA_REL_ "GenSigTimeoutTime" BU_SG_REL_ BPMU SG_ 1364 YearUTC_ISig_4 1500;
BA_REL_ "GenSigFirstTimeoutTime" BU_SG_REL_ WSGW SG_ 1364 SecondsUTC_ISig_4 6000;
BA_REL_ "GenSigTimeoutTime" BU_SG_REL_ WSGW SG_ 1364 SecondsUTC_ISig_4 1500;
BA_REL_ "GenSigFirstTimeoutTime" BU_SG_REL_ RCIOM SG_ 1364 SecondsUTC_ISig_4 6000;
BA_REL_ "GenSigTimeoutTime" BU_SG_REL_ RCIOM SG_ 1364 SecondsUTC_ISig_4 1500;
BA_REL_ "GenSigFirstTimeoutTime" BU_SG_REL_ FCIOM SG_ 1364 SecondsUTC_ISig_4 6000;
BA_REL_ "GenSigTimeoutTime" BU_SG_REL_ FCIOM SG_ 1364 SecondsUTC_ISig_4 1500;
BA_REL_ "GenSigFirstTimeoutTime" BU_SG_REL_ BPMU SG_ 1364 SecondsUTC_ISig_4 6000;
BA_REL_ "GenSigTimeoutTime" BU_SG_REL_ BPMU SG_ 1364 SecondsUTC_ISig_4 1500;
BA_REL_ "GenSigFirstTimeoutTime" BU_SG_REL_ CCIOM SG_ 1364 SecondsUTC_ISig_4 6000;
BA_REL_ "GenSigTimeoutTime" BU_SG_REL_ CCIOM SG_ 1364 SecondsUTC_ISig_4 1500;
BA_REL_ "GenSigFirstTimeoutTime" BU_SG_REL_ RCIOM SG_ 1364 DayUTC_ISig_4 6000;
BA_REL_ "GenSigTimeoutTime" BU_SG_REL_ RCIOM SG_ 1364 DayUTC_ISig_4 1500;
BA_REL_ "GenSigFirstTimeoutTime" BU_SG_REL_ CCIOM SG_ 1364 DayUTC_ISig_4 6000;
BA_REL_ "GenSigTimeoutTime" BU_SG_REL_ CCIOM SG_ 1364 DayUTC_ISig_4 1500;
BA_REL_ "GenSigFirstTimeoutTime" BU_SG_REL_ FCIOM SG_ 1364 DayUTC_ISig_4 6000;
BA_REL_ "GenSigTimeoutTime" BU_SG_REL_ FCIOM SG_ 1364 DayUTC_ISig_4 1500;
BA_REL_ "GenSigFirstTimeoutTime" BU_SG_REL_ BPMU SG_ 1364 DayUTC_ISig_4 6000;
BA_REL_ "GenSigTimeoutTime" BU_SG_REL_ BPMU SG_ 1364 DayUTC_ISig_4 1500;
BA_REL_ "GenSigFirstTimeoutTime" BU_SG_REL_ WSGW SG_ 1364 DayUTC_ISig_4 6000;
BA_REL_ "GenSigTimeoutTime" BU_SG_REL_ WSGW SG_ 1364 DayUTC_ISig_4 1500;
BA_REL_ "GenSigFirstTimeoutTime" BU_SG_REL_ BPMU SG_ 1364 MinutesUTC_ISig_4 6000;
BA_REL_ "GenSigTimeoutTime" BU_SG_REL_ BPMU SG_ 1364 MinutesUTC_ISig_4 1500;
BA_REL_ "GenSigFirstTimeoutTime" BU_SG_REL_ CCIOM SG_ 1364 MinutesUTC_ISig_4 6000;
BA_REL_ "GenSigTimeoutTime" BU_SG_REL_ CCIOM SG_ 1364 MinutesUTC_ISig_4 1500;
BA_REL_ "GenSigFirstTimeoutTime" BU_SG_REL_ RCIOM SG_ 1364 MinutesUTC_ISig_4 6000;
BA_REL_ "GenSigTimeoutTime" BU_SG_REL_ RCIOM SG_ 1364 MinutesUTC_ISig_4 1500;
BA_REL_ "GenSigFirstTimeoutTime" BU_SG_REL_ WSGW SG_ 1364 MinutesUTC_ISig_4 6000;
BA_REL_ "GenSigTimeoutTime" BU_SG_REL_ WSGW SG_ 1364 MinutesUTC_ISig_4 1500;
BA_REL_ "GenSigFirstTimeoutTime" BU_SG_REL_ FCIOM SG_ 1364 MinutesUTC_ISig_4 6000;
BA_REL_ "GenSigTimeoutTime" BU_SG_REL_ FCIOM SG_ 1364 MinutesUTC_ISig_4 1500;
BA_REL_ "GenSigFirstTimeoutTime" BU_SG_REL_ CCIOM SG_ 826 BBContUnlockCmd 3000;
BA_REL_ "GenSigTimeoutTime" BU_SG_REL_ CCIOM SG_ 826 BBContUnlockCmd 180;
BA_REL_ "GenSigFirstTimeoutTime" BU_SG_REL_ FCIOM SG_ 826 LampCheck_cmd 3000;
BA_REL_ "GenSigTimeoutTime" BU_SG_REL_ FCIOM SG_ 826 LampCheck_cmd 180;
BA_REL_ "GenSigFirstTimeoutTime" BU_SG_REL_ RCIOM SG_ 826 LampCheck_rqst_ISig_4 3000;
BA_REL_ "GenSigTimeoutTime" BU_SG_REL_ RCIOM SG_ 826 LampCheck_rqst_ISig_4 180;
BA_REL_ "GenSigFirstTimeoutTime" BU_SG_REL_ CCIOM SG_ 826 BatteryCapacity_ISig_4 3000;
BA_REL_ "GenSigTimeoutTime" BU_SG_REL_ CCIOM SG_ 826 BatteryCapacity_ISig_4 180;
BA_REL_ "GenSigFirstTimeoutTime" BU_SG_REL_ CCIOM SG_ 826 AreaInhibit 3000;
BA_REL_ "GenSigTimeoutTime" BU_SG_REL_ CCIOM SG_ 826 AreaInhibit 180;
BA_REL_ "GenSigFirstTimeoutTime" BU_SG_REL_ FCIOM SG_ 826 LEDAnimation_cmd 3000;
BA_REL_ "GenSigTimeoutTime" BU_SG_REL_ FCIOM SG_ 826 LEDAnimation_cmd 180;
BA_REL_ "GenSigFirstTimeoutTime" BU_SG_REL_ RCIOM SG_ 826 ActualDrvlnRetdrPercentTorque_IS 3000;
BA_REL_ "GenSigTimeoutTime" BU_SG_REL_ RCIOM SG_ 826 ActualDrvlnRetdrPercentTorque_IS 180;
BA_REL_ "GenSigFirstTimeoutTime" BU_SG_REL_ FCIOM SG_ 826 PloughLampModeStatus_ISig_4 3000;
BA_REL_ "GenSigTimeoutTime" BU_SG_REL_ FCIOM SG_ 826 PloughLampModeStatus_ISig_4 180;
BA_REL_ "GenSigFirstTimeoutTime" BU_SG_REL_ CCIOM SG_ 826 RangeInhibit 3000;
BA_REL_ "GenSigTimeoutTime" BU_SG_REL_ CCIOM SG_ 826 RangeInhibit 180;
BA_REL_ "GenSigFirstTimeoutTime" BU_SG_REL_ RCIOM SG_ 826 TrailerBrakeNoEbs_stat 3000;
BA_REL_ "GenSigTimeoutTime" BU_SG_REL_ RCIOM SG_ 826 TrailerBrakeNoEbs_stat 180;
BA_REL_ "GenSigFirstTimeoutTime" BU_SG_REL_ RCIOM SG_ 826 LiftAxle1DirectControl_ISig_4 3000;
BA_REL_ "GenSigTimeoutTime" BU_SG_REL_ RCIOM SG_ 826 LiftAxle1DirectControl_ISig_4 500;
BA_REL_ "GenSigFirstTimeoutTime" BU_SG_REL_ CCIOM SG_ 826 DoorsAjar_stat_ISig_4 3000;
BA_REL_ "GenSigTimeoutTime" BU_SG_REL_ CCIOM SG_ 826 DoorsAjar_stat_ISig_4 500;
BA_REL_ "GenSigFirstTimeoutTime" BU_SG_REL_ RCIOM SG_ 826 BrakeLight_rqst 3000;
BA_REL_ "GenSigTimeoutTime" BU_SG_REL_ RCIOM SG_ 826 BrakeLight_rqst 180;
BA_REL_ "GenSigFirstTimeoutTime" BU_SG_REL_ TBIOM SG_ 826 BrakeLight_rqst 3000;
BA_REL_ "GenSigTimeoutTime" BU_SG_REL_ TBIOM SG_ 826 BrakeLight_rqst 180;
BA_REL_ "GenSigFirstTimeoutTime" BU_SG_REL_ RCIOM SG_ 826 BlackOutandConvoyMode_rqst 3000;
BA_REL_ "GenSigTimeoutTime" BU_SG_REL_ RCIOM SG_ 826 BlackOutandConvoyMode_rqst 180;
BA_REL_ "GenSigFirstTimeoutTime" BU_SG_REL_ CCIOM SG_ 826 BlackOutandConvoyMode_rqst 3000;
BA_REL_ "GenSigTimeoutTime" BU_SG_REL_ CCIOM SG_ 826 BlackOutandConvoyMode_rqst 180;
BA_REL_ "GenSigFirstTimeoutTime" BU_SG_REL_ CCIOM SG_ 826 DoorsAjar_stat_UB_ISig_4 3000;
BA_REL_ "GenSigTimeoutTime" BU_SG_REL_ CCIOM SG_ 826 DoorsAjar_stat_UB_ISig_4 180;
BA_REL_ "GenSigFirstTimeoutTime" BU_SG_REL_ RCIOM SG_ 826 RevLight_cmd 3000;
BA_REL_ "GenSigTimeoutTime" BU_SG_REL_ RCIOM SG_ 826 RevLight_cmd 180;
BA_REL_ "GenSigFirstTimeoutTime" BU_SG_REL_ CCIOM SG_ 826 RevLight_cmd 3000;
BA_REL_ "GenSigTimeoutTime" BU_SG_REL_ CCIOM SG_ 826 RevLight_cmd 180;
BA_REL_ "GenSigFirstTimeoutTime" BU_SG_REL_ RCIOM SG_ 826 ECSStandByRequest_ISig_4 3000;
BA_REL_ "GenSigTimeoutTime" BU_SG_REL_ RCIOM SG_ 826 ECSStandByRequest_ISig_4 180;
BA_REL_ "GenSigFirstTimeoutTime" BU_SG_REL_ FCIOM SG_ 826 ChassisInstepLight_cmd 3000;
BA_REL_ "GenSigTimeoutTime" BU_SG_REL_ FCIOM SG_ 826 ChassisInstepLight_cmd 180;
BA_REL_ "GenSigFirstTimeoutTime" BU_SG_REL_ CCIOM SG_ 826 BBSlidable5thWheelCmd 3000;
BA_REL_ "GenSigTimeoutTime" BU_SG_REL_ CCIOM SG_ 826 BBSlidable5thWheelCmd 180;
BA_REL_ "GenSigFirstTimeoutTime" BU_SG_REL_ RCIOM SG_ 826 ParkingBrake_stat_ISig_4 3000;
BA_REL_ "GenSigTimeoutTime" BU_SG_REL_ RCIOM SG_ 826 ParkingBrake_stat_ISig_4 180;
BA_REL_ "GenSigFirstTimeoutTime" BU_SG_REL_ CCIOM SG_ 826 ParkingBrake_stat_ISig_4 3000;
BA_REL_ "GenSigTimeoutTime" BU_SG_REL_ CCIOM SG_ 826 ParkingBrake_stat_ISig_4 180;
BA_REL_ "GenSigFirstTimeoutTime" BU_SG_REL_ WSGW SG_ 826 ParkingBrake_stat_ISig_4 3000;
BA_REL_ "GenSigTimeoutTime" BU_SG_REL_ WSGW SG_ 826 ParkingBrake_stat_ISig_4 180;
BA_REL_ "GenSigFirstTimeoutTime" BU_SG_REL_ CCIOM SG_ 826 MaintBatteryReset 3000;
BA_REL_ "GenSigTimeoutTime" BU_SG_REL_ CCIOM SG_ 826 MaintBatteryReset 180;
BA_REL_ "GenSigFirstTimeoutTime" BU_SG_REL_ RCIOM SG_ 1369 TotalVehicleDistanceHighRes_ISig 12000;
BA_REL_ "GenSigTimeoutTime" BU_SG_REL_ RCIOM SG_ 1369 TotalVehicleDistanceHighRes_ISig 3000;
BA_REL_ "GenSigFirstTimeoutTime" BU_SG_REL_ WSGW SG_ 1369 TotalVehicleDistanceHighRes_ISig 12000;
BA_REL_ "GenSigTimeoutTime" BU_SG_REL_ WSGW SG_ 1369 TotalVehicleDistanceHighRes_ISig 3000;
BA_REL_ "GenSigFirstTimeoutTime" BU_SG_REL_ CCIOM SG_ 1369 TotalVehicleDistanceHighRes_ISig 12000;
BA_REL_ "GenSigTimeoutTime" BU_SG_REL_ CCIOM SG_ 1369 TotalVehicleDistanceHighRes_ISig 3000;
BA_REL_ "GenSigFirstTimeoutTime" BU_SG_REL_ FCIOM SG_ 1369 TotalVehicleDistanceHighRes_ISig 12000;
BA_REL_ "GenSigTimeoutTime" BU_SG_REL_ FCIOM SG_ 1369 TotalVehicleDistanceHighRes_ISig 3000;
BA_REL_ "GenSigFirstTimeoutTime" BU_SG_REL_ BPMU SG_ 1369 TotalVehicleDistanceHighRes_ISig 12000;
BA_REL_ "GenSigTimeoutTime" BU_SG_REL_ BPMU SG_ 1369 TotalVehicleDistanceHighRes_ISig 3000;
BA_REL_ "GenSigFirstTimeoutTime" BU_SG_REL_ RCIOM SG_ 946 TransferCaseOrSplitboxPTOMode_IS 3000;
BA_REL_ "GenSigTimeoutTime" BU_SG_REL_ RCIOM SG_ 946 TransferCaseOrSplitboxPTOMode_IS 300;
BA_REL_ "GenSigFirstTimeoutTime" BU_SG_REL_ RCIOM SG_ 946 Pto3Status 3000;
BA_REL_ "GenSigTimeoutTime" BU_SG_REL_ RCIOM SG_ 946 Pto3Status 300;
BA_REL_ "GenSigFirstTimeoutTime" BU_SG_REL_ RCIOM SG_ 946 RearAxleDiffLockActvnFuncReq_ISi 3000;
BA_REL_ "GenSigTimeoutTime" BU_SG_REL_ RCIOM SG_ 946 RearAxleDiffLockActvnFuncReq_ISi 500;
BA_REL_ "GenSigFirstTimeoutTime" BU_SG_REL_ RCIOM SG_ 946 Pto1Status_ISig_4 3000;
BA_REL_ "GenSigTimeoutTime" BU_SG_REL_ RCIOM SG_ 946 Pto1Status_ISig_4 300;
BA_REL_ "GenSigFirstTimeoutTime" BU_SG_REL_ CCIOM SG_ 946 ReducedLoadMode_stat_ISig_4 3000;
BA_REL_ "GenSigTimeoutTime" BU_SG_REL_ CCIOM SG_ 946 ReducedLoadMode_stat_ISig_4 300;
BA_REL_ "GenSigFirstTimeoutTime" BU_SG_REL_ RCIOM SG_ 946 RearAxleDiffLockActvnDrvrReq_ISi 3000;
BA_REL_ "GenSigTimeoutTime" BU_SG_REL_ RCIOM SG_ 946 RearAxleDiffLockActvnDrvrReq_ISi 500;
BA_REL_ "GenSigFirstTimeoutTime" BU_SG_REL_ CCIOM SG_ 946 Pto2DrivingRequest 3000;
BA_REL_ "GenSigTimeoutTime" BU_SG_REL_ CCIOM SG_ 946 Pto2DrivingRequest 300;
BA_REL_ "GenSigFirstTimeoutTime" BU_SG_REL_ RCIOM SG_ 946 RrInterAxlDiffLockActvnFuncReq_I 3000;
BA_REL_ "GenSigTimeoutTime" BU_SG_REL_ RCIOM SG_ 946 RrInterAxlDiffLockActvnFuncReq_I 300;
BA_REL_ "GenSigFirstTimeoutTime" BU_SG_REL_ CCIOM SG_ 946 CartridgeChangedDrvrReset_rqst_I 3000;
BA_REL_ "GenSigTimeoutTime" BU_SG_REL_ CCIOM SG_ 946 CartridgeChangedDrvrReset_rqst_I 300;
BA_REL_ "GenSigFirstTimeoutTime" BU_SG_REL_ RCIOM SG_ 946 RrInterAxlDiffLockActvnDrvrReq_I 3000;
BA_REL_ "GenSigTimeoutTime" BU_SG_REL_ RCIOM SG_ 946 RrInterAxlDiffLockActvnDrvrReq_I 500;
BA_REL_ "GenSigFirstTimeoutTime" BU_SG_REL_ RCIOM SG_ 946 Pto2Status_ISig_4 3000;
BA_REL_ "GenSigTimeoutTime" BU_SG_REL_ RCIOM SG_ 946 Pto2Status_ISig_4 300;
BA_REL_ "GenSigFirstTimeoutTime" BU_SG_REL_ RCIOM SG_ 946 Pto4Status 3000;
BA_REL_ "GenSigTimeoutTime" BU_SG_REL_ RCIOM SG_ 946 Pto4Status 300;
BA_REL_ "GenSigFirstTimeoutTime" BU_SG_REL_ CCIOM SG_ 946 Pto1DrivingRequest 3000;
BA_REL_ "GenSigTimeoutTime" BU_SG_REL_ CCIOM SG_ 946 Pto1DrivingRequest 300;
VAL_ 1519 WGTrckTPMThresCfg_AxleNr 7 "AxleNumber_NotAvailable" 6 "AxleNumber_Error" 5 "AxleNumber_Axle5" 4 "AxleNumber_Axle4" 3 "AxleNumber_Axle3" 2 "AxleNumber_Axle2" 1 "AxleNumber_Axle1" 0 "AxleNumber_NoRequest" ;
VAL_ 1356 WGTrail5TPMInf_BatteryStatus 15 "TPMBatteryStatus2_NotAvailable" 14 "TPMBatteryStatus2_Error" 13 "TPMBatteryStatus2_Spare3" 12 "TPMBatteryStatus2_Spare2" 11 "TPMBatteryStatus2_Spare1" 10 "TPMBatteryStatus2_100PercentBatteryLifeRemaining" 9 "TPMBatteryStatus2_90PercentBatteryLifeRemaining" 8 "TPMBatteryStatus2_80PercentBatteryLifeRemaining" 7 "TPMBatteryStatus2_70PercentBatteryLifeRemaining" 6 "TPMBatteryStatus2_60PercentBatteryLifeRemaining" 5 "TPMBatteryStatus2_50PercentBatteryLifeRemaining" 4 "TPMBatteryStatus2_40PercentBatteryLifeRemaining" 3 "TPMBatteryStatus2_30PercentBatteryLifeRemaining" 2 "TPMBatteryStatus2_20PercentBatteryLifeRemaining" 1 "TPMBatteryStatus2_10PercentBatteryLifeRemaining" 0 "TPMBatteryStatus2_Spare0" ;
VAL_ 1356 WGTrail5TPMInf_TemperatureStatus 3 "TPMTyreTempStat_NotAvailable" 2 "TPMTyreTempStat_Error" 1 "TPMTyreTempStat_OverTemp" 0 "TPMTyreTempStat_SupportedNoOverTemp" ;
VAL_ 1356 WGTrail5TPMInf_PressureStatus 15 "PressureStatus_NotAvailable" 14 "PressureStatus_Error" 13 "PressureStatus_SignalNotSupported" 12 "PressureStatus_Spare6" 11 "PressureStatus_Spare5" 10 "PressureStatus_Spare4" 9 "PressureStatus_Spare3" 8 "PressureStatus_Spare2" 7 "PressureStatus_Spare1" 6 "PressureStatus_ExtremeUnderPressure" 5 "PressureStatus_UnderPressure" 4 "PressureStatus_ECOUnderPressure" 3 "PressureStatus_ExtremeOverPressure" 2 "PressureStatus_OverPressure" 1 "PressureStatus_ECOOverPressure" 0 "PressureStatus_NominalPressureRange" ;
VAL_ 1356 WGTrail5TPMInf_FastPressureLoss 3 "NotDetected_NotAvaliable" 2 "NotDetected_Error" 1 "NotDetected_Detected" 0 "NotDetected_NotDetected" ;
VAL_ 1356 WGTrail5TPMInf_SensorIDProgStat 3 "SensorIDProgStat_NotAvailable" 2 "SensorIDProgStat_Error" 1 "SensorIDProgStat_SensorIDNotProgrammed" 0 "SensorIDProgStat_SensorIDProgrammed" ;
VAL_ 1355 WGTrail4TPMInf_TemperatureStatus 3 "TPMTyreTempStat_NotAvailable" 2 "TPMTyreTempStat_Error" 1 "TPMTyreTempStat_OverTemp" 0 "TPMTyreTempStat_SupportedNoOverTemp" ;
VAL_ 1355 WGTrail4TPMInf_PressureStatus 15 "PressureStatus_NotAvailable" 14 "PressureStatus_Error" 13 "PressureStatus_SignalNotSupported" 12 "PressureStatus_Spare6" 11 "PressureStatus_Spare5" 10 "PressureStatus_Spare4" 9 "PressureStatus_Spare3" 8 "PressureStatus_Spare2" 7 "PressureStatus_Spare1" 6 "PressureStatus_ExtremeUnderPressure" 5 "PressureStatus_UnderPressure" 4 "PressureStatus_ECOUnderPressure" 3 "PressureStatus_ExtremeOverPressure" 2 "PressureStatus_OverPressure" 1 "PressureStatus_ECOOverPressure" 0 "PressureStatus_NominalPressureRange" ;
VAL_ 1355 WGTrail4TPMInf_BatteryStatus 15 "TPMBatteryStatus2_NotAvailable" 14 "TPMBatteryStatus2_Error" 13 "TPMBatteryStatus2_Spare3" 12 "TPMBatteryStatus2_Spare2" 11 "TPMBatteryStatus2_Spare1" 10 "TPMBatteryStatus2_100PercentBatteryLifeRemaining" 9 "TPMBatteryStatus2_90PercentBatteryLifeRemaining" 8 "TPMBatteryStatus2_80PercentBatteryLifeRemaining" 7 "TPMBatteryStatus2_70PercentBatteryLifeRemaining" 6 "TPMBatteryStatus2_60PercentBatteryLifeRemaining" 5 "TPMBatteryStatus2_50PercentBatteryLifeRemaining" 4 "TPMBatteryStatus2_40PercentBatteryLifeRemaining" 3 "TPMBatteryStatus2_30PercentBatteryLifeRemaining" 2 "TPMBatteryStatus2_20PercentBatteryLifeRemaining" 1 "TPMBatteryStatus2_10PercentBatteryLifeRemaining" 0 "TPMBatteryStatus2_Spare0" ;
VAL_ 1355 WGTrail4TPMInf_SensorIDProgStat 3 "SensorIDProgStat_NotAvailable" 2 "SensorIDProgStat_Error" 1 "SensorIDProgStat_SensorIDNotProgrammed" 0 "SensorIDProgStat_SensorIDProgrammed" ;
VAL_ 1355 WGTrail4TPMInf_FastPressureLoss 3 "NotDetected_NotAvaliable" 2 "NotDetected_Error" 1 "NotDetected_Detected" 0 "NotDetected_NotDetected" ;
VAL_ 1354 WGTrail3TPMInf_FastPressureLoss 3 "NotDetected_NotAvaliable" 2 "NotDetected_Error" 1 "NotDetected_Detected" 0 "NotDetected_NotDetected" ;
VAL_ 1354 WGTrail3TPMInf_PressureStatus 15 "PressureStatus_NotAvailable" 14 "PressureStatus_Error" 13 "PressureStatus_SignalNotSupported" 12 "PressureStatus_Spare6" 11 "PressureStatus_Spare5" 10 "PressureStatus_Spare4" 9 "PressureStatus_Spare3" 8 "PressureStatus_Spare2" 7 "PressureStatus_Spare1" 6 "PressureStatus_ExtremeUnderPressure" 5 "PressureStatus_UnderPressure" 4 "PressureStatus_ECOUnderPressure" 3 "PressureStatus_ExtremeOverPressure" 2 "PressureStatus_OverPressure" 1 "PressureStatus_ECOOverPressure" 0 "PressureStatus_NominalPressureRange" ;
VAL_ 1354 WGTrail3TPMInf_SensorIDProgStat 3 "SensorIDProgStat_NotAvailable" 2 "SensorIDProgStat_Error" 1 "SensorIDProgStat_SensorIDNotProgrammed" 0 "SensorIDProgStat_SensorIDProgrammed" ;
VAL_ 1354 WGTrail3TPMInf_TemperatureStatus 3 "TPMTyreTempStat_NotAvailable" 2 "TPMTyreTempStat_Error" 1 "TPMTyreTempStat_OverTemp" 0 "TPMTyreTempStat_SupportedNoOverTemp" ;
VAL_ 1354 WGTrail3TPMInf_BatteryStatus 15 "TPMBatteryStatus2_NotAvailable" 14 "TPMBatteryStatus2_Error" 13 "TPMBatteryStatus2_Spare3" 12 "TPMBatteryStatus2_Spare2" 11 "TPMBatteryStatus2_Spare1" 10 "TPMBatteryStatus2_100PercentBatteryLifeRemaining" 9 "TPMBatteryStatus2_90PercentBatteryLifeRemaining" 8 "TPMBatteryStatus2_80PercentBatteryLifeRemaining" 7 "TPMBatteryStatus2_70PercentBatteryLifeRemaining" 6 "TPMBatteryStatus2_60PercentBatteryLifeRemaining" 5 "TPMBatteryStatus2_50PercentBatteryLifeRemaining" 4 "TPMBatteryStatus2_40PercentBatteryLifeRemaining" 3 "TPMBatteryStatus2_30PercentBatteryLifeRemaining" 2 "TPMBatteryStatus2_20PercentBatteryLifeRemaining" 1 "TPMBatteryStatus2_10PercentBatteryLifeRemaining" 0 "TPMBatteryStatus2_Spare0" ;
VAL_ 1337 WGTrail2TPMInf_PressureStatus 15 "PressureStatus_NotAvailable" 14 "PressureStatus_Error" 13 "PressureStatus_SignalNotSupported" 12 "PressureStatus_Spare6" 11 "PressureStatus_Spare5" 10 "PressureStatus_Spare4" 9 "PressureStatus_Spare3" 8 "PressureStatus_Spare2" 7 "PressureStatus_Spare1" 6 "PressureStatus_ExtremeUnderPressure" 5 "PressureStatus_UnderPressure" 4 "PressureStatus_ECOUnderPressure" 3 "PressureStatus_ExtremeOverPressure" 2 "PressureStatus_OverPressure" 1 "PressureStatus_ECOOverPressure" 0 "PressureStatus_NominalPressureRange" ;
VAL_ 1337 WGTrail2TPMInf_FastPressureLoss 3 "NotDetected_NotAvaliable" 2 "NotDetected_Error" 1 "NotDetected_Detected" 0 "NotDetected_NotDetected" ;
VAL_ 1337 WGTrail2TPMInf_SensorIDProgStat 3 "SensorIDProgStat_NotAvailable" 2 "SensorIDProgStat_Error" 1 "SensorIDProgStat_SensorIDNotProgrammed" 0 "SensorIDProgStat_SensorIDProgrammed" ;
VAL_ 1337 WGTrail2TPMInf_TemperatureStatus 3 "TPMTyreTempStat_NotAvailable" 2 "TPMTyreTempStat_Error" 1 "TPMTyreTempStat_OverTemp" 0 "TPMTyreTempStat_SupportedNoOverTemp" ;
VAL_ 1337 WGTrail2TPMInf_BatteryStatus 15 "TPMBatteryStatus2_NotAvailable" 14 "TPMBatteryStatus2_Error" 13 "TPMBatteryStatus2_Spare3" 12 "TPMBatteryStatus2_Spare2" 11 "TPMBatteryStatus2_Spare1" 10 "TPMBatteryStatus2_100PercentBatteryLifeRemaining" 9 "TPMBatteryStatus2_90PercentBatteryLifeRemaining" 8 "TPMBatteryStatus2_80PercentBatteryLifeRemaining" 7 "TPMBatteryStatus2_70PercentBatteryLifeRemaining" 6 "TPMBatteryStatus2_60PercentBatteryLifeRemaining" 5 "TPMBatteryStatus2_50PercentBatteryLifeRemaining" 4 "TPMBatteryStatus2_40PercentBatteryLifeRemaining" 3 "TPMBatteryStatus2_30PercentBatteryLifeRemaining" 2 "TPMBatteryStatus2_20PercentBatteryLifeRemaining" 1 "TPMBatteryStatus2_10PercentBatteryLifeRemaining" 0 "TPMBatteryStatus2_Spare0" ;
VAL_ 1336 WGTrail1TPMInf_BatteryStatus 15 "TPMBatteryStatus2_NotAvailable" 14 "TPMBatteryStatus2_Error" 13 "TPMBatteryStatus2_Spare3" 12 "TPMBatteryStatus2_Spare2" 11 "TPMBatteryStatus2_Spare1" 10 "TPMBatteryStatus2_100PercentBatteryLifeRemaining" 9 "TPMBatteryStatus2_90PercentBatteryLifeRemaining" 8 "TPMBatteryStatus2_80PercentBatteryLifeRemaining" 7 "TPMBatteryStatus2_70PercentBatteryLifeRemaining" 6 "TPMBatteryStatus2_60PercentBatteryLifeRemaining" 5 "TPMBatteryStatus2_50PercentBatteryLifeRemaining" 4 "TPMBatteryStatus2_40PercentBatteryLifeRemaining" 3 "TPMBatteryStatus2_30PercentBatteryLifeRemaining" 2 "TPMBatteryStatus2_20PercentBatteryLifeRemaining" 1 "TPMBatteryStatus2_10PercentBatteryLifeRemaining" 0 "TPMBatteryStatus2_Spare0" ;
VAL_ 1336 WGTrail1TPMInf_TemperatureStatus 3 "TPMTyreTempStat_NotAvailable" 2 "TPMTyreTempStat_Error" 1 "TPMTyreTempStat_OverTemp" 0 "TPMTyreTempStat_SupportedNoOverTemp" ;
VAL_ 1336 WGTrail1TPMInf_SensorIDProgStat 3 "SensorIDProgStat_NotAvailable" 2 "SensorIDProgStat_Error" 1 "SensorIDProgStat_SensorIDNotProgrammed" 0 "SensorIDProgStat_SensorIDProgrammed" ;
VAL_ 1336 WGTrail1TPMInf_PressureStatus 15 "PressureStatus_NotAvailable" 14 "PressureStatus_Error" 13 "PressureStatus_SignalNotSupported" 12 "PressureStatus_Spare6" 11 "PressureStatus_Spare5" 10 "PressureStatus_Spare4" 9 "PressureStatus_Spare3" 8 "PressureStatus_Spare2" 7 "PressureStatus_Spare1" 6 "PressureStatus_ExtremeUnderPressure" 5 "PressureStatus_UnderPressure" 4 "PressureStatus_ECOUnderPressure" 3 "PressureStatus_ExtremeOverPressure" 2 "PressureStatus_OverPressure" 1 "PressureStatus_ECOOverPressure" 0 "PressureStatus_NominalPressureRange" ;
VAL_ 1336 WGTrail1TPMInf_FastPressureLoss 3 "NotDetected_NotAvaliable" 2 "NotDetected_Error" 1 "NotDetected_Detected" 0 "NotDetected_NotDetected" ;
VAL_ 1283 WGTPMPosOfWMResp_VehiclePos 7 "TPMVehiclePos_NotAvailable" 6 "TPMVehiclePos_Error" 5 "TPMVehiclePos_Trailer5Vehicle" 4 "TPMVehiclePos_Trailer4Vehicle" 3 "TPMVehiclePos_Trailer3Vehicle" 2 "TPMVehiclePos_Trailer2Vehicle" 1 "TPMVehiclePos_Trailer1Vehicle" 0 "TPMVehiclePos_TruckVehicle" ;
VAL_ 1283 WGTrailer4TPMLostCom 3 "NoYes_NotAvailable" 2 "NoYes_Error" 1 "NoYes_Yes" 0 "NoYes_No" ;
VAL_ 1283 WGTruckTPMFailure 3 "InactiveActive_NotAvailable" 2 "InactiveActive_Error" 1 "InactiveActive_Active" 0 "InactiveActive_Inactive" ;
VAL_ 1283 WGTrailer5TPMLostCom 3 "NoYes_NotAvailable" 2 "NoYes_Error" 1 "NoYes_Yes" 0 "NoYes_No" ;
VAL_ 1283 WGTrlr1TPMMatedStatus 3 "NoMatedMated_NotAvailable" 2 "NoMatedMated_Error" 1 "NoMatedMated_Mated" 0 "NoMatedMated_NoMated" ;
VAL_ 1283 WGTrailer5TPMFailure 3 "InactiveActive_NotAvailable" 2 "InactiveActive_Error" 1 "InactiveActive_Active" 0 "InactiveActive_Inactive" ;
VAL_ 1283 WGTrlr5TPMMatedStatus 3 "NoMatedMated_NotAvailable" 2 "NoMatedMated_Error" 1 "NoMatedMated_Mated" 0 "NoMatedMated_NoMated" ;
VAL_ 1283 WGTrailer1TPMLostCom 3 "NoYes_NotAvailable" 2 "NoYes_Error" 1 "NoYes_Yes" 0 "NoYes_No" ;
VAL_ 1283 WGTrailer1TPMFailure 3 "InactiveActive_NotAvailable" 2 "InactiveActive_Error" 1 "InactiveActive_Active" 0 "InactiveActive_Inactive" ;
VAL_ 1283 WGTrailer2TPMFailure 3 "InactiveActive_NotAvailable" 2 "InactiveActive_Error" 1 "InactiveActive_Active" 0 "InactiveActive_Inactive" ;
VAL_ 1283 WGTrailer4TPMFailure 3 "InactiveActive_NotAvailable" 2 "InactiveActive_Error" 1 "InactiveActive_Active" 0 "InactiveActive_Inactive" ;
VAL_ 1283 WGTrailer2TPMLostCom 3 "NoYes_NotAvailable" 2 "NoYes_Error" 1 "NoYes_Yes" 0 "NoYes_No" ;
VAL_ 1283 WGTrailer3TPMFailure 3 "InactiveActive_NotAvailable" 2 "InactiveActive_Error" 1 "InactiveActive_Active" 0 "InactiveActive_Inactive" ;
VAL_ 1283 WGTrlr3TPMMatedStatus 3 "NoMatedMated_NotAvailable" 2 "NoMatedMated_Error" 1 "NoMatedMated_Mated" 0 "NoMatedMated_NoMated" ;
VAL_ 1283 WGTrailer3TPMLostCom 3 "NoYes_NotAvailable" 2 "NoYes_Error" 1 "NoYes_Yes" 0 "NoYes_No" ;
VAL_ 1283 WGTrlr4TPMMatedStatus 3 "NoMatedMated_NotAvailable" 2 "NoMatedMated_Error" 1 "NoMatedMated_Mated" 0 "NoMatedMated_NoMated" ;
VAL_ 1283 WGTrlr2TPMMatedStatus 3 "NoMatedMated_NotAvailable" 2 "NoMatedMated_Error" 1 "NoMatedMated_Mated" 0 "NoMatedMated_NoMated" ;
VAL_ 1283 WGTPMPosOfWMResp_Status 7 "TPMPosStatusResp_NotAvailable" 6 "TPMPosStatusResp_Error" 5 "TPMPosStatusResp_Aborted" 4 "TPMPosStatusResp_Failed" 3 "TPMPosStatusResp_PositionedOK" 2 "TPMPosStatusResp_Timeout" 1 "TPMPosStatusResp_Progressing" 0 "TPMPosStatusResp_NotActive" ;
VAL_ 1518 Trail5WGTPMAxlTireCfg_Axle2 7 "TPMAxleConfig_NotAvailable" 6 "TPMAxleConfig_Error" 5 "TPMAxleConfig_Spare" 4 "TPMAxleConfig_RearAxleWith4Tires" 3 "TPMAxleConfig_RearAxleWith2Tires" 2 "TPMAxleConfig_FrontAxleWith4Tires" 1 "TPMAxleConfig_FrontAxleWith2Tires" 0 "TPMAxleConfig_NotPresent" ;
VAL_ 1518 Trail5WGTPMAxlTireCfg_Axle3 7 "TPMAxleConfig_NotAvailable" 6 "TPMAxleConfig_Error" 5 "TPMAxleConfig_Spare" 4 "TPMAxleConfig_RearAxleWith4Tires" 3 "TPMAxleConfig_RearAxleWith2Tires" 2 "TPMAxleConfig_FrontAxleWith4Tires" 1 "TPMAxleConfig_FrontAxleWith2Tires" 0 "TPMAxleConfig_NotPresent" ;
VAL_ 1518 Trail4WGTPMAxlTireCfg_Axle2 7 "TPMAxleConfig_NotAvailable" 6 "TPMAxleConfig_Error" 5 "TPMAxleConfig_Spare" 4 "TPMAxleConfig_RearAxleWith4Tires" 3 "TPMAxleConfig_RearAxleWith2Tires" 2 "TPMAxleConfig_FrontAxleWith4Tires" 1 "TPMAxleConfig_FrontAxleWith2Tires" 0 "TPMAxleConfig_NotPresent" ;
VAL_ 1518 Trail4WGTPMAxlTireCfg_Axle3 7 "TPMAxleConfig_NotAvailable" 6 "TPMAxleConfig_Error" 5 "TPMAxleConfig_Spare" 4 "TPMAxleConfig_RearAxleWith4Tires" 3 "TPMAxleConfig_RearAxleWith2Tires" 2 "TPMAxleConfig_FrontAxleWith4Tires" 1 "TPMAxleConfig_FrontAxleWith2Tires" 0 "TPMAxleConfig_NotPresent" ;
VAL_ 1518 Trail4WGTPMAxlTireCfg_Axle5 7 "TPMAxleConfig_NotAvailable" 6 "TPMAxleConfig_Error" 5 "TPMAxleConfig_Spare" 4 "TPMAxleConfig_RearAxleWith4Tires" 3 "TPMAxleConfig_RearAxleWith2Tires" 2 "TPMAxleConfig_FrontAxleWith4Tires" 1 "TPMAxleConfig_FrontAxleWith2Tires" 0 "TPMAxleConfig_NotPresent" ;
VAL_ 1518 Trail5WGTPMAxlTireCfg_Axle4 7 "TPMAxleConfig_NotAvailable" 6 "TPMAxleConfig_Error" 5 "TPMAxleConfig_Spare" 4 "TPMAxleConfig_RearAxleWith4Tires" 3 "TPMAxleConfig_RearAxleWith2Tires" 2 "TPMAxleConfig_FrontAxleWith4Tires" 1 "TPMAxleConfig_FrontAxleWith2Tires" 0 "TPMAxleConfig_NotPresent" ;
VAL_ 1518 Trail4WGTPMAxlTireCfg_Axle4 7 "TPMAxleConfig_NotAvailable" 6 "TPMAxleConfig_Error" 5 "TPMAxleConfig_Spare" 4 "TPMAxleConfig_RearAxleWith4Tires" 3 "TPMAxleConfig_RearAxleWith2Tires" 2 "TPMAxleConfig_FrontAxleWith4Tires" 1 "TPMAxleConfig_FrontAxleWith2Tires" 0 "TPMAxleConfig_NotPresent" ;
VAL_ 1518 Trail5WGTPMAxlTireCfg_Axle5 7 "TPMAxleConfig_NotAvailable" 6 "TPMAxleConfig_Error" 5 "TPMAxleConfig_Spare" 4 "TPMAxleConfig_RearAxleWith4Tires" 3 "TPMAxleConfig_RearAxleWith2Tires" 2 "TPMAxleConfig_FrontAxleWith4Tires" 1 "TPMAxleConfig_FrontAxleWith2Tires" 0 "TPMAxleConfig_NotPresent" ;
VAL_ 1518 Trail4WGTPMAxlTireCfg_Axle1 7 "TPMAxleConfig_NotAvailable" 6 "TPMAxleConfig_Error" 5 "TPMAxleConfig_Spare" 4 "TPMAxleConfig_RearAxleWith4Tires" 3 "TPMAxleConfig_RearAxleWith2Tires" 2 "TPMAxleConfig_FrontAxleWith4Tires" 1 "TPMAxleConfig_FrontAxleWith2Tires" 0 "TPMAxleConfig_NotPresent" ;
VAL_ 1518 Trail5WGTPMAxlTireCfg_Axle1 7 "TPMAxleConfig_NotAvailable" 6 "TPMAxleConfig_Error" 5 "TPMAxleConfig_Spare" 4 "TPMAxleConfig_RearAxleWith4Tires" 3 "TPMAxleConfig_RearAxleWith2Tires" 2 "TPMAxleConfig_FrontAxleWith4Tires" 1 "TPMAxleConfig_FrontAxleWith2Tires" 0 "TPMAxleConfig_NotPresent" ;
VAL_ 1520 WGTruckTPMAxlTireCfg_Axle5 7 "TPMAxleConfig_NotAvailable" 6 "TPMAxleConfig_Error" 5 "TPMAxleConfig_Spare" 4 "TPMAxleConfig_RearAxleWith4Tires" 3 "TPMAxleConfig_RearAxleWith2Tires" 2 "TPMAxleConfig_FrontAxleWith4Tires" 1 "TPMAxleConfig_FrontAxleWith2Tires" 0 "TPMAxleConfig_NotPresent" ;
VAL_ 1520 Trail3WGTPMAxlTireCfg_Axle2 7 "TPMAxleConfig_NotAvailable" 6 "TPMAxleConfig_Error" 5 "TPMAxleConfig_Spare" 4 "TPMAxleConfig_RearAxleWith4Tires" 3 "TPMAxleConfig_RearAxleWith2Tires" 2 "TPMAxleConfig_FrontAxleWith4Tires" 1 "TPMAxleConfig_FrontAxleWith2Tires" 0 "TPMAxleConfig_NotPresent" ;
VAL_ 1520 WGTruckTPMAxlTireCfg_Axle4 7 "TPMAxleConfig_NotAvailable" 6 "TPMAxleConfig_Error" 5 "TPMAxleConfig_Spare" 4 "TPMAxleConfig_RearAxleWith4Tires" 3 "TPMAxleConfig_RearAxleWith2Tires" 2 "TPMAxleConfig_FrontAxleWith4Tires" 1 "TPMAxleConfig_FrontAxleWith2Tires" 0 "TPMAxleConfig_NotPresent" ;
VAL_ 1520 WGTruckTPMAxlTireCfg_Axle3 7 "TPMAxleConfig_NotAvailable" 6 "TPMAxleConfig_Error" 5 "TPMAxleConfig_Spare" 4 "TPMAxleConfig_RearAxleWith4Tires" 3 "TPMAxleConfig_RearAxleWith2Tires" 2 "TPMAxleConfig_FrontAxleWith4Tires" 1 "TPMAxleConfig_FrontAxleWith2Tires" 0 "TPMAxleConfig_NotPresent" ;
VAL_ 1520 Trail3WGTPMAxlTireCfg_Axle3 7 "TPMAxleConfig_NotAvailable" 6 "TPMAxleConfig_Error" 5 "TPMAxleConfig_Spare" 4 "TPMAxleConfig_RearAxleWith4Tires" 3 "TPMAxleConfig_RearAxleWith2Tires" 2 "TPMAxleConfig_FrontAxleWith4Tires" 1 "TPMAxleConfig_FrontAxleWith2Tires" 0 "TPMAxleConfig_NotPresent" ;
VAL_ 1520 Trail1WGTPMAxlTireCfg_Axle4 7 "TPMAxleConfig_NotAvailable" 6 "TPMAxleConfig_Error" 5 "TPMAxleConfig_Spare" 4 "TPMAxleConfig_RearAxleWith4Tires" 3 "TPMAxleConfig_RearAxleWith2Tires" 2 "TPMAxleConfig_FrontAxleWith4Tires" 1 "TPMAxleConfig_FrontAxleWith2Tires" 0 "TPMAxleConfig_NotPresent" ;
VAL_ 1520 WGTruckTPMAxlTireCfg_Axle2 7 "TPMAxleConfig_NotAvailable" 6 "TPMAxleConfig_Error" 5 "TPMAxleConfig_Spare" 4 "TPMAxleConfig_RearAxleWith4Tires" 3 "TPMAxleConfig_RearAxleWith2Tires" 2 "TPMAxleConfig_FrontAxleWith4Tires" 1 "TPMAxleConfig_FrontAxleWith2Tires" 0 "TPMAxleConfig_NotPresent" ;
VAL_ 1520 Trail2WGTPMAxlTireCfg_Axle3 7 "TPMAxleConfig_NotAvailable" 6 "TPMAxleConfig_Error" 5 "TPMAxleConfig_Spare" 4 "TPMAxleConfig_RearAxleWith4Tires" 3 "TPMAxleConfig_RearAxleWith2Tires" 2 "TPMAxleConfig_FrontAxleWith4Tires" 1 "TPMAxleConfig_FrontAxleWith2Tires" 0 "TPMAxleConfig_NotPresent" ;
VAL_ 1520 Trail3WGTPMAxlTireCfg_Axle1 7 "TPMAxleConfig_NotAvailable" 6 "TPMAxleConfig_Error" 5 "TPMAxleConfig_Spare" 4 "TPMAxleConfig_RearAxleWith4Tires" 3 "TPMAxleConfig_RearAxleWith2Tires" 2 "TPMAxleConfig_FrontAxleWith4Tires" 1 "TPMAxleConfig_FrontAxleWith2Tires" 0 "TPMAxleConfig_NotPresent" ;
VAL_ 1520 Trail2WGTPMAxlTireCfg_Axle2 7 "TPMAxleConfig_NotAvailable" 6 "TPMAxleConfig_Error" 5 "TPMAxleConfig_Spare" 4 "TPMAxleConfig_RearAxleWith4Tires" 3 "TPMAxleConfig_RearAxleWith2Tires" 2 "TPMAxleConfig_FrontAxleWith4Tires" 1 "TPMAxleConfig_FrontAxleWith2Tires" 0 "TPMAxleConfig_NotPresent" ;
VAL_ 1520 Trail1WGTPMAxlTireCfg_Axle1 7 "TPMAxleConfig_NotAvailable" 6 "TPMAxleConfig_Error" 5 "TPMAxleConfig_Spare" 4 "TPMAxleConfig_RearAxleWith4Tires" 3 "TPMAxleConfig_RearAxleWith2Tires" 2 "TPMAxleConfig_FrontAxleWith4Tires" 1 "TPMAxleConfig_FrontAxleWith2Tires" 0 "TPMAxleConfig_NotPresent" ;
VAL_ 1520 Trail1WGTPMAxlTireCfg_Axle5 7 "TPMAxleConfig_NotAvailable" 6 "TPMAxleConfig_Error" 5 "TPMAxleConfig_Spare" 4 "TPMAxleConfig_RearAxleWith4Tires" 3 "TPMAxleConfig_RearAxleWith2Tires" 2 "TPMAxleConfig_FrontAxleWith4Tires" 1 "TPMAxleConfig_FrontAxleWith2Tires" 0 "TPMAxleConfig_NotPresent" ;
VAL_ 1520 Trail3WGTPMAxlTireCfg_Axle4 7 "TPMAxleConfig_NotAvailable" 6 "TPMAxleConfig_Error" 5 "TPMAxleConfig_Spare" 4 "TPMAxleConfig_RearAxleWith4Tires" 3 "TPMAxleConfig_RearAxleWith2Tires" 2 "TPMAxleConfig_FrontAxleWith4Tires" 1 "TPMAxleConfig_FrontAxleWith2Tires" 0 "TPMAxleConfig_NotPresent" ;
VAL_ 1520 Trail2WGTPMAxlTireCfg_Axle5 7 "TPMAxleConfig_NotAvailable" 6 "TPMAxleConfig_Error" 5 "TPMAxleConfig_Spare" 4 "TPMAxleConfig_RearAxleWith4Tires" 3 "TPMAxleConfig_RearAxleWith2Tires" 2 "TPMAxleConfig_FrontAxleWith4Tires" 1 "TPMAxleConfig_FrontAxleWith2Tires" 0 "TPMAxleConfig_NotPresent" ;
VAL_ 1520 Trail1WGTPMAxlTireCfg_Axle3 7 "TPMAxleConfig_NotAvailable" 6 "TPMAxleConfig_Error" 5 "TPMAxleConfig_Spare" 4 "TPMAxleConfig_RearAxleWith4Tires" 3 "TPMAxleConfig_RearAxleWith2Tires" 2 "TPMAxleConfig_FrontAxleWith4Tires" 1 "TPMAxleConfig_FrontAxleWith2Tires" 0 "TPMAxleConfig_NotPresent" ;
VAL_ 1520 WGTruckTPMAxlTireCfg_Axle1 7 "TPMAxleConfig_NotAvailable" 6 "TPMAxleConfig_Error" 5 "TPMAxleConfig_Spare" 4 "TPMAxleConfig_RearAxleWith4Tires" 3 "TPMAxleConfig_RearAxleWith2Tires" 2 "TPMAxleConfig_FrontAxleWith4Tires" 1 "TPMAxleConfig_FrontAxleWith2Tires" 0 "TPMAxleConfig_NotPresent" ;
VAL_ 1520 Trail2WGTPMAxlTireCfg_Axle1 7 "TPMAxleConfig_NotAvailable" 6 "TPMAxleConfig_Error" 5 "TPMAxleConfig_Spare" 4 "TPMAxleConfig_RearAxleWith4Tires" 3 "TPMAxleConfig_RearAxleWith2Tires" 2 "TPMAxleConfig_FrontAxleWith4Tires" 1 "TPMAxleConfig_FrontAxleWith2Tires" 0 "TPMAxleConfig_NotPresent" ;
VAL_ 1520 Trail2WGTPMAxlTireCfg_Axle4 7 "TPMAxleConfig_NotAvailable" 6 "TPMAxleConfig_Error" 5 "TPMAxleConfig_Spare" 4 "TPMAxleConfig_RearAxleWith4Tires" 3 "TPMAxleConfig_RearAxleWith2Tires" 2 "TPMAxleConfig_FrontAxleWith4Tires" 1 "TPMAxleConfig_FrontAxleWith2Tires" 0 "TPMAxleConfig_NotPresent" ;
VAL_ 1520 Trail3WGTPMAxlTireCfg_Axle5 7 "TPMAxleConfig_NotAvailable" 6 "TPMAxleConfig_Error" 5 "TPMAxleConfig_Spare" 4 "TPMAxleConfig_RearAxleWith4Tires" 3 "TPMAxleConfig_RearAxleWith2Tires" 2 "TPMAxleConfig_FrontAxleWith4Tires" 1 "TPMAxleConfig_FrontAxleWith2Tires" 0 "TPMAxleConfig_NotPresent" ;
VAL_ 1520 Trail1WGTPMAxlTireCfg_Axle2 7 "TPMAxleConfig_NotAvailable" 6 "TPMAxleConfig_Error" 5 "TPMAxleConfig_Spare" 4 "TPMAxleConfig_RearAxleWith4Tires" 3 "TPMAxleConfig_RearAxleWith2Tires" 2 "TPMAxleConfig_FrontAxleWith4Tires" 1 "TPMAxleConfig_FrontAxleWith2Tires" 0 "TPMAxleConfig_NotPresent" ;
VAL_ 1335 WGTruckTPMInfo_TemperatureStatus 3 "TPMTyreTempStat_NotAvailable" 2 "TPMTyreTempStat_Error" 1 "TPMTyreTempStat_OverTemp" 0 "TPMTyreTempStat_SupportedNoOverTemp" ;
VAL_ 1335 WGTruckTPMInfo_FastPressureLoss 3 "NotDetected_NotAvaliable" 2 "NotDetected_Error" 1 "NotDetected_Detected" 0 "NotDetected_NotDetected" ;
VAL_ 1335 WGTruckTPMInfo_PressureStatus 15 "PressureStatus_NotAvailable" 14 "PressureStatus_Error" 13 "PressureStatus_SignalNotSupported" 12 "PressureStatus_Spare6" 11 "PressureStatus_Spare5" 10 "PressureStatus_Spare4" 9 "PressureStatus_Spare3" 8 "PressureStatus_Spare2" 7 "PressureStatus_Spare1" 6 "PressureStatus_ExtremeUnderPressure" 5 "PressureStatus_UnderPressure" 4 "PressureStatus_ECOUnderPressure" 3 "PressureStatus_ExtremeOverPressure" 2 "PressureStatus_OverPressure" 1 "PressureStatus_ECOOverPressure" 0 "PressureStatus_NominalPressureRange" ;
VAL_ 1335 WGTruckTPMInfo_SensorIDProgStat 3 "SensorIDProgStat_NotAvailable" 2 "SensorIDProgStat_Error" 1 "SensorIDProgStat_SensorIDNotProgrammed" 0 "SensorIDProgStat_SensorIDProgrammed" ;
VAL_ 1335 WGTruckTPMInfo_BatteryStatus 15 "TPMBatteryStatus2_NotAvailable" 14 "TPMBatteryStatus2_Error" 13 "TPMBatteryStatus2_Spare3" 12 "TPMBatteryStatus2_Spare2" 11 "TPMBatteryStatus2_Spare1" 10 "TPMBatteryStatus2_100PercentBatteryLifeRemaining" 9 "TPMBatteryStatus2_90PercentBatteryLifeRemaining" 8 "TPMBatteryStatus2_80PercentBatteryLifeRemaining" 7 "TPMBatteryStatus2_70PercentBatteryLifeRemaining" 6 "TPMBatteryStatus2_60PercentBatteryLifeRemaining" 5 "TPMBatteryStatus2_50PercentBatteryLifeRemaining" 4 "TPMBatteryStatus2_40PercentBatteryLifeRemaining" 3 "TPMBatteryStatus2_30PercentBatteryLifeRemaining" 2 "TPMBatteryStatus2_20PercentBatteryLifeRemaining" 1 "TPMBatteryStatus2_10PercentBatteryLifeRemaining" 0 "TPMBatteryStatus2_Spare0" ;
VAL_ 1361 Set_EnergySetting_ISig_4 7 "EnergySetting_NotAvailable" 6 "EnergySetting_Error" 5 "EnergySetting_Spare2" 4 "EnergySetting_Spare1" 3 "EnergySetting_Customise" 2 "EnergySetting_PresetLevel2_HighEnergySaving" 1 "EnergySetting_PresetLevel1_EnergySaving" 0 "EnergySetting_OFF" ;
VAL_ 1267 AirIntakeSolenoidValve_cmd 3 "OffOn_NotAvailable" 2 "OffOn_Error" 1 "OffOn_On" 0 "OffOn_Off" ;
VAL_ 1267 KingPinUnlockCmd_Rqst 3 "NotDriven_Driven_NotAvailable" 2 "NotDriven_Driven_Error" 1 "NotDriven_Driven_Driven" 0 "NotDriven_Driven_NotDriven" ;
VAL_ 1267 PreventECSFuncForSWDL_rqst 3 "InactiveActive_NotAvailable" 2 "InactiveActive_Error" 1 "InactiveActive_Active" 0 "InactiveActive_Inactive" ;
VAL_ 1267 AutoShutOffAnswerInput_ISig_4 7 "AutoShutOffAnswerInput_NotAvailable" 6 "AutoShutOffAnswerInput_Error" 5 "AutoShutOffAnswerInput_Spare3" 4 "AutoShutOffAnswerInput_Spare2" 3 "AutoShutOffAnswerInput_Spare1" 2 "AutoShutOffAnswerInput_Delayed" 1 "AutoShutOffAnswerInput_NoAnswer" 0 "AutoShutOffAnswerInput_Accepted" ;
VAL_ 954 DumpSwitchChangeReq_ISig_4 3 "DumpSwitchChangeReq_NotAvailable" 2 "DumpSwitchChangeReq_Error" 1 "DumpSwitchChangeReq_ChangeDumpFunction" 0 "DumpSwitchChangeReq_NoAction" ;
VAL_ 954 LCP_Status_ISig_4 7 "LCP_Status_NotAvailable" 6 "LCP_Status_Error" 5 "LCP_Status_SpareValue_01" 4 "LCP_Status_SpareValue" 3 "LCP_Status_DrivePlus_Auto" 2 "LCP_Status_Drive" 1 "LCP_Status_Park" 0 "LCP_Status_ZeroDRL" ;
VAL_ 954 CAHighBeamFlash_cmd 3 "CAHighBeamFlash_cmd_NotAvailable" 2 "CAHighBeamFlash_cmd_CrossFlashActive" 1 "CAHighBeamFlash_cmd_SimultaneousFlashActive" 0 "CAHighBeamFlash_cmd_NoFlashActive" ;
VAL_ 954 PTI_DRL_cmd 3 "DeactivateActivate_NotAvailable" 2 "DeactivateActivate_Error" 1 "DeactivateActivate_Activate" 0 "DeactivateActivate_Deactivate" ;
VAL_ 954 HeadLampDeicingControl_rqst 3 "InactiveActive_NotAvailable" 2 "InactiveActive_Error" 1 "InactiveActive_Active" 0 "InactiveActive_Inactive" ;
VAL_ 677 EngineStarterMode_ISig_4 15 "EngineStarterMode_NotAvailable" 14 "EngineStarterMode_Error" 13 "EngineStarterMode_NotToBeUsed" 12 "EngineStarterMode_StarterInhibitedReasonUnknown" 11 "EngineStarterMode_Reserved_02" 10 "EngineStarterMode_Reserved_01" 9 "EngineStarterMode_Reserved" 8 "EngineStarterMode_StarterInhibitedDueToStarterOverTemp" 7 "EngineStarterMode_StarterInhibitedDueToActiveImmobilizer" 6 "EngineStarterMode_StarterInhibitedDueToDrivelineEngagedOrOther" 5 "EngineStarterMode_StarterInhibitedDueToEngineNotReadyForStart" 4 "EngineStarterMode_StarterInhibitedDueToEngineAlreadyRunning" 3 "EngineStarterMode_StartFinishedStarterNotActiveAfterHavingBe" 2 "EngineStarterMode_StarterActiveGearEngaged" 1 "EngineStarterMode_StarterActiveGearNotEngaged" 0 "EngineStarterMode_StartNotRequested" ;
VAL_ 1363 PredeliveryModeIndication_cmd_IS 3 "DeactivateActivate_NotAvailable" 2 "DeactivateActivate_Error" 1 "DeactivateActivate_Activate" 0 "DeactivateActivate_Deactivate" ;
VAL_ 535 DirectionIndicatorLightsStatus_I 15 "DirectionIndicatorLightsStatus_NotAvailable" 14 "DirectionIndicatorLightsStatus_Error" 13 "DirectionIndicatorLightsStatus_Spare7" 12 "DirectionIndicatorLightsStatus_Spare6" 11 "DirectionIndicatorLightsStatus_Spare5" 10 "DirectionIndicatorLightsStatus_Spare4" 9 "DirectionIndicatorLightsStatus_Spare3" 8 "DirectionIndicatorLightsStatus_Spare2" 7 "DirectionIndicatorLightsStatus_Spare1" 6 "DirectionIndicatorLightsStatus_ActiveOtherIndication" 5 "DirectionIndicatorLightsStatus_ActiveHazard" 4 "DirectionIndicatorLightsStatus_ActiveRightAndHazard" 3 "DirectionIndicatorLightsStatus_ActiveLeftAndHazard" 2 "DirectionIndicatorLightsStatus_ActiveRight" 1 "DirectionIndicatorLightsStatus_ActiveLeft" 0 "DirectionIndicatorLightsStatus_NotActive" ;
VAL_ 1381 BattEnergySetLevel_input_ISig_4 7 "BattEnergySetLevel_input_NotAvailable" 6 "BattEnergySetLevel_input_Error" 5 "BattEnergySetLevel_input_Spare" 4 "BattEnergySetLevel_input_Level5" 3 "BattEnergySetLevel_input_Level4" 2 "BattEnergySetLevel_input_Level3" 1 "BattEnergySetLevel_input_Level2" 0 "BattEnergySetLevel_input_Level1" ;
VAL_ 1381 MainBatteryResetPos 15 "MainBatteryResetPos_NotAvailable" 14 "MainBatteryResetPos_Error" 13 "MainBatteryResetPos_NoSelectionMade" 12 "MainBatteryResetPos_Spare09" 11 "MainBatteryResetPos_Spare08" 10 "MainBatteryResetPos_Spare07" 9 "MainBatteryResetPos_Spare06" 8 "MainBatteryResetPos_Spare05" 7 "MainBatteryResetPos_Spare04" 6 "MainBatteryResetPos_Spare03" 5 "MainBatteryResetPos_Spare02" 4 "MainBatteryResetPos_Spare01" 3 "MainBatteryResetPos_3A_and_3B" 2 "MainBatteryResetPos_2A_and_2B" 1 "MainBatteryResetPos_1A_and_1B" 0 "MainBatteryResetPos_AllPosition" ;
VAL_ 519 AdaptiveMainBeamRight_cmd 7 "AdaptiveMainBeam_cmd_NotAvailable" 6 "AdaptiveMainBeam_cmd_Error" 5 "AdaptiveMainBeam_cmd_Spare3" 4 "AdaptiveMainBeam_cmd_Spare2" 3 "AdaptiveMainBeam_cmd_Spare1" 2 "AdaptiveMainBeam_cmd_GlareFreeAllowed" 1 "AdaptiveMainBeam_cmd_MainBeamAllowed" 0 "AdaptiveMainBeam_cmd_MainBeamNotAllowed" ;
VAL_ 519 AdaptiveMainBeamLeft_cmd 7 "AdaptiveMainBeam_cmd_NotAvailable" 6 "AdaptiveMainBeam_cmd_Error" 5 "AdaptiveMainBeam_cmd_Spare3" 4 "AdaptiveMainBeam_cmd_Spare2" 3 "AdaptiveMainBeam_cmd_Spare1" 2 "AdaptiveMainBeam_cmd_GlareFreeAllowed" 1 "AdaptiveMainBeam_cmd_MainBeamAllowed" 0 "AdaptiveMainBeam_cmd_MainBeamNotAllowed" ;
VAL_ 1370 TPMSetPresThresCfg_VehiclePos_IS 7 "TPMVehiclePos_NotAvailable" 6 "TPMVehiclePos_Error" 5 "TPMVehiclePos_Trailer5Vehicle" 4 "TPMVehiclePos_Trailer4Vehicle" 3 "TPMVehiclePos_Trailer3Vehicle" 2 "TPMVehiclePos_Trailer2Vehicle" 1 "TPMVehiclePos_Trailer1Vehicle" 0 "TPMVehiclePos_TruckVehicle" ;
VAL_ 1370 TPMSetPresThresCfg_AxleNr_ISig_4 7 "TPMAxleNr_NotAvailable" 6 "TPMAxleNr_Error" 5 "TPMAxleNr_Axle5" 4 "TPMAxleNr_Axle4" 3 "TPMAxleNr_Axle3" 2 "TPMAxleNr_Axle2" 1 "TPMAxleNr_Axle1" 0 "TPMAxleNr_NoRequest" ;
VAL_ 1373 TPMPosOfWMReq_VehiclePos_ISig_4 7 "TPMVehiclePos_NotAvailable" 6 "TPMVehiclePos_Error" 5 "TPMVehiclePos_Trailer5Vehicle" 4 "TPMVehiclePos_Trailer4Vehicle" 3 "TPMVehiclePos_Trailer3Vehicle" 2 "TPMVehiclePos_Trailer2Vehicle" 1 "TPMVehiclePos_Trailer1Vehicle" 0 "TPMVehiclePos_TruckVehicle" ;
VAL_ 1373 TPMSetAxleRefPres_VehiclePos_ISi 7 "TPMVehiclePos_NotAvailable" 6 "TPMVehiclePos_Error" 5 "TPMVehiclePos_Trailer5Vehicle" 4 "TPMVehiclePos_Trailer4Vehicle" 3 "TPMVehiclePos_Trailer3Vehicle" 2 "TPMVehiclePos_Trailer2Vehicle" 1 "TPMVehiclePos_Trailer1Vehicle" 0 "TPMVehiclePos_TruckVehicle" ;
VAL_ 1249 TransferCasePTOEngaged 3 "NotEngagedEngaged_NotAvailable" 2 "NotEngagedEngaged_Error" 1 "NotEngagedEngaged_Engaged" 0 "NotEngagedEngaged_NotEngaged" ;
VAL_ 1249 EhrasTagAxleLoweringInhibit 3 "InhibitStatus_NotAvailable" 2 "InhibitStatus_Reserved" 1 "InhibitStatus_Inhibited" 0 "InhibitStatus_NotInhibited" ;
VAL_ 1249 ExtECSRequestPressureUpdate 3 "Request_NotAvailable" 2 "Request_Error" 1 "Request_RequestActive" 0 "Request_NotRequested" ;
VAL_ 1249 HeadLampFanControl_rqst 3 "InactiveActive_NotAvailable" 2 "InactiveActive_Error" 1 "InactiveActive_Active" 0 "InactiveActive_Inactive" ;
VAL_ 1249 BBAirDumpRequest 3 "InactiveActive_NotAvailable" 2 "InactiveActive_Error" 1 "InactiveActive_Active" 0 "InactiveActive_Inactive" ;
VAL_ 1249 ApproachLight_rqst 3 "InactiveActive_NotAvailable" 2 "InactiveActive_Error" 1 "InactiveActive_Active" 0 "InactiveActive_Inactive" ;
VAL_ 1249 FrAxle2WheelDriveRequest 3 "DisengageEngage_NotAvailable" 2 "DisengageEngage_Error" 1 "DisengageEngage_Engage" 0 "DisengageEngage_Disengage" ;
VAL_ 1249 EhrasPusherAxleLoweringInhibit 3 "InhibitStatus_NotAvailable" 2 "InhibitStatus_Reserved" 1 "InhibitStatus_Inhibited" 0 "InhibitStatus_NotInhibited" ;
VAL_ 1249 LivBatteryChargingStat_rqst 3 "NotRequested_NotAvailable" 2 "NotRequested_Error" 1 "NotRequested_Requested" 0 "NotRequested_NotRequested" ;
VAL_ 1249 ClutchSwitch2Stat 3 "ClutchSwitch_NotAvailable" 2 "ClutchSwitch_Error" 1 "ClutchSwitch_ClutchPedalDepressed" 0 "ClutchSwitch_ClutchPedalReleased" ;
VAL_ 1249 SideMarkersLights_cmd 7 "SideMarkersLights_cmd_NotAvailable" 6 "SideMarkersLights_cmd_Error" 5 "SideMarkersLights_cmd_Spare2" 4 "SideMarkersLights_cmd_Spare1" 3 "SideMarkersLights_cmd_LeftandRightSideMarkersActive" 2 "SideMarkersLights_cmd_RightSideMarkersActive" 1 "SideMarkersLights_cmd_LeftSideMarkersActive" 0 "SideMarkersLights_cmd_Inactive" ;
VAL_ 1249 BBEcsForceStandstillFilterReq 3 "InactiveActive_NotAvailable" 2 "InactiveActive_Error" 1 "InactiveActive_Active" 0 "InactiveActive_Inactive" ;
VAL_ 944 ShortStopHeater_cmd_ISig_4 3 "Request_NotAvailable" 2 "Request_Error" 1 "Request_RequestActive" 0 "Request_NotRequested" ;
VAL_ 944 LoadDistributionRequested_ISig_4 15 "LoadDistributionRequested_NotAvailable" 14 "LoadDistributionRequested_Error" 13 "LoadDistributionRequested_Reserved5" 12 "LoadDistributionRequested_Reserved4" 11 "LoadDistributionRequested_Reserved3" 10 "LoadDistributionRequested_Reserved2" 9 "LoadDistributionRequested_Reserved1" 8 "LoadDistributionRequested_DelpressLoadDistribution" 7 "LoadDistributionRequested_VariableLoadDistribution" 6 "LoadDistributionRequested_AlternativeLoadDistribution" 5 "LoadDistributionRequested_MaximumTraction2" 4 "LoadDistributionRequested_MaximumTraction1" 3 "LoadDistributionRequested_OptimizedTraction" 2 "LoadDistributionRequested_NormalLoadDistribution" 1 "LoadDistributionRequested_DefaultLoadDistribution" 0 "LoadDistributionRequested_NoAction" ;
VAL_ 390 CityHorn_cmd 3 "OffOn_NotAvailable" 2 "OffOn_Error" 1 "OffOn_On" 0 "OffOn_Off" ;
VAL_ 390 BrakeSwitch_ISig_4 3 "BrakeSwitch_NotAvailable" 2 "BrakeSwitch_Error" 1 "BrakeSwitch_BrakePedalDepressed" 0 "BrakeSwitch_BrakePedalReleased" ;
VAL_ 390 LevelRequest_FrontAxle_ISig_4 7 "LevelChangeRequest_NotAvailable" 6 "LevelChangeRequest_ErrorIndicator" 5 "LevelChangeRequest_NotDefined" 4 "LevelChangeRequest_VehicleBodyDownMinimumMovementLowering" 3 "LevelChangeRequest_VehicleBodyUpMinimumMovementLifting" 2 "LevelChangeRequest_VehicleBodyDownLowering" 1 "LevelChangeRequest_VehicleBodyUpLifting" 0 "LevelChangeRequest_TakeNoAction" ;
VAL_ 390 FPBRChangeReq_ISig_4 3 "FPBRChangeReq_NotAvailable" 2 "FPBRChangeReq_Error" 1 "FPBRChangeReq_ChangeFPBRFunction" 0 "FPBRChangeReq_TakeNoAction" ;
VAL_ 390 AuxiliaryHorn_cmd 3 "OffOn_NotAvailable" 2 "OffOn_Error" 1 "OffOn_On" 0 "OffOn_Off" ;
VAL_ 390 LevelRequest_RearAxle_ISig_4 7 "LevelChangeRequest_NotAvailable" 6 "LevelChangeRequest_ErrorIndicator" 5 "LevelChangeRequest_NotDefined" 4 "LevelChangeRequest_VehicleBodyDownMinimumMovementLowering" 3 "LevelChangeRequest_VehicleBodyUpMinimumMovementLifting" 2 "LevelChangeRequest_VehicleBodyDownLowering" 1 "LevelChangeRequest_VehicleBodyUpLifting" 0 "LevelChangeRequest_TakeNoAction" ;
VAL_ 390 LevelRequest_RollRequest_ISig_4 7 "RollRequest_NotAvailable" 6 "RollRequest_Error" 5 "RollRequest_Reserved" 4 "RollRequest_CounterClockwiseShort" 3 "RollRequest_ClockwiseShort" 2 "RollRequest_CounterClockwise" 1 "RollRequest_Clockwise" 0 "RollRequest_Idle" ;
VAL_ 389 FrontWheelDriveRequest 3 "DisengageEngage_NotAvailable" 2 "DisengageEngage_Error" 1 "DisengageEngage_Engage" 0 "DisengageEngage_Disengage" ;
VAL_ 389 KneelingChangeRequest_ISig_4 3 "KneelingChangeRequest_NotAvailable" 2 "KneelingChangeRequest_Error" 1 "KneelingChangeRequest_ChangeKneelFunction" 0 "KneelingChangeRequest_TakeNoAction" ;
VAL_ 826 BBContUnlockCmd 3 "NotDriven_Driven_NotAvailable" 2 "NotDriven_Driven_Error" 1 "NotDriven_Driven_Driven" 0 "NotDriven_Driven_NotDriven" ;
VAL_ 826 LampCheck_cmd 3 "LampCheck_NotAvailable" 2 "LampCheck_Error" 1 "LampCheck_PerformLampCheck" 0 "LampCheck_NoAction" ;
VAL_ 826 LampCheck_rqst_ISig_4 3 "LampCheck_NotAvailable" 2 "LampCheck_Error" 1 "LampCheck_PerformLampCheck" 0 "LampCheck_NoAction" ;
VAL_ 826 BatteryCapacity_ISig_4 15 "BatteryType_NotAvailable" 14 "BatteryType_Error" 13 "BatteryType_NoSelectionMade" 12 "BatteryType_OtherBatteryType" 11 "BatteryType_BatteryType11" 10 "BatteryType_BatteryType10" 9 "BatteryType_BatteryType9" 8 "BatteryType_BatteryType8" 7 "BatteryType_BatteryType7" 6 "BatteryType_BatteryType6" 5 "BatteryType_BatteryType5" 4 "BatteryType_BatteryType4" 3 "BatteryType_BatteryType3" 2 "BatteryType_BatteryType2" 1 "BatteryType_BatteryType1" 0 "BatteryType_BatteryType0" ;
VAL_ 826 AreaInhibit 3 "Inhibit_NotAvailable" 2 "Inhibit_Error" 1 "Inhibit_InhibitActive" 0 "Inhibit_NoInhibit" ;
VAL_ 826 LEDAnimation_cmd 7 "LEDAnimation_cmd_NotAvailable" 6 "LEDAnimation_cmd_Error" 2 "LEDAnimation_cmd_UnlockAnimation" 1 "LEDAnimation_cmd_LockAnimation" 0 "LEDAnimation_cmd_NoAction" ;
VAL_ 826 PloughLampModeStatus_ISig_4 3 "InactiveActive_NotAvailable" 2 "InactiveActive_Error" 1 "InactiveActive_Active" 0 "InactiveActive_Inactive" ;
VAL_ 826 RangeInhibit 3 "Inhibit_NotAvailable" 2 "Inhibit_Error" 1 "Inhibit_InhibitActive" 0 "Inhibit_NoInhibit" ;
VAL_ 826 TrailerBrakeNoEbs_stat 3 "InactiveActive_NotAvailable" 2 "InactiveActive_Error" 1 "InactiveActive_Active" 0 "InactiveActive_Inactive" ;
VAL_ 826 LiftAxle1DirectControl_ISig_4 7 "LiftAxleLiftPositionRequest_NotAvailable" 6 "LiftAxleLiftPositionRequest_Error" 5 "LiftAxleLiftPositionRequest_Reserved_02" 4 "LiftAxleLiftPositionRequest_Reserved_01" 3 "LiftAxleLiftPositionRequest_Reserved" 2 "LiftAxleLiftPositionRequest_Up" 1 "LiftAxleLiftPositionRequest_Down" 0 "LiftAxleLiftPositionRequest_Idle" ;
VAL_ 826 DoorsAjar_stat_ISig_4 7 "DoorsAjar_stat_NotAvailable" 6 "DoorsAjar_stat_Error" 5 "DoorsAjar_stat_Spare" 4 "DoorsAjar_stat_BothDoorsAreOpen" 3 "DoorsAjar_stat_PassengerDoorIsOpen" 2 "DoorsAjar_stat_DriverDoorIsOpen" 1 "DoorsAjar_stat_BothDoorsAreClosed" 0 "DoorsAjar_stat_Idle" ;
VAL_ 826 BrakeLight_rqst 7 "BrakeLight_rqst_NotAvailable" 6 "BrakeLight_rqst_SpareValue_03" 5 "BrakeLight_rqst_SpareValue_02" 4 "BrakeLight_rqst_SpareValue_01" 3 "BrakeLight_rqst_SpareValue" 2 "BrakeLight_rqst_EmergencyBrakeLightOn" 1 "BrakeLight_rqst_BrakeLightOn" 0 "BrakeLight_rqst_BrakeLightAndEmergencyBrakeLightOff" ;
VAL_ 826 BlackOutandConvoyMode_rqst 7 "BlackOutandConvoyMode_rqst_NotAvailable" 6 "BlackOutandConvoyMode_rqst_Error" 5 "BlackOutandConvoyMode_rqst_SpareValue_02" 4 "BlackOutandConvoyMode_rqst_SpareValue_01" 3 "BlackOutandConvoyMode_rqst_SpareValue" 2 "BlackOutandConvoyMode_rqst_ConvoyMode" 1 "BlackOutandConvoyMode_rqst_BlackOutMode" 0 "BlackOutandConvoyMode_rqst_NormalMode" ;
VAL_ 826 RevLight_cmd 3 "InactiveActive_NotAvailable" 2 "InactiveActive_Error" 1 "InactiveActive_Active" 0 "InactiveActive_Inactive" ;
VAL_ 826 ECSStandByRequest_ISig_4 7 "ECSStandByRequest_NotAvailable" 6 "ECSStandByRequest_Error" 5 "ECSStandByRequest_Reserved_01" 4 "ECSStandByRequest_Reserved" 3 "ECSStandByRequest_StandbyRequestedWRC" 2 "ECSStandByRequest_StandbyRequestedRCECS" 1 "ECSStandByRequest_Initiate" 0 "ECSStandByRequest_NoRequest" ;
VAL_ 826 ChassisInstepLight_cmd 3 "OffOn_NotAvailable" 2 "OffOn_Error" 1 "OffOn_On" 0 "OffOn_Off" ;
VAL_ 826 BBSlidable5thWheelCmd 3 "NotDriven_Driven_NotAvailable" 2 "NotDriven_Driven_Error" 1 "NotDriven_Driven_Driven" 0 "NotDriven_Driven_NotDriven" ;
VAL_ 826 ParkingBrake_stat_ISig_4 3 "ParkingBrake_stat_NotAvailable" 2 "ParkingBrake_stat_Error" 1 "ParkingBrake_stat_ParkingBrakeActivated" 0 "ParkingBrake_stat_ParkingBrakeReleased" ;
VAL_ 826 MaintBatteryReset 3 "Request_NotAvailable" 2 "Request_Error" 1 "Request_RequestActive" 0 "Request_NotRequested" ;
VAL_ 946 TransferCaseOrSplitboxPTOMode_IS 3 "InactiveActive_NotAvailable" 2 "InactiveActive_Error" 1 "InactiveActive_Active" 0 "InactiveActive_Inactive" ;
VAL_ 946 Pto3Status 3 "InactiveActive_NotAvailable" 2 "InactiveActive_Error" 1 "InactiveActive_Active" 0 "InactiveActive_Inactive" ;
VAL_ 946 RearAxleDiffLockActvnFuncReq_ISi 3 "RearAxleDiffLockActvnFuncReq_TakeNoAction" 2 "RearAxleDiffLockActvnFuncReq_Reserved" 1 "RearAxleDiffLockActvnFuncReq_DisengageDifferentialLock" 0 "RearAxleDiffLockActvnFuncReq_EngageDifferentialLock" ;
VAL_ 946 Pto1Status_ISig_4 3 "InactiveActive_NotAvailable" 2 "InactiveActive_Error" 1 "InactiveActive_Active" 0 "InactiveActive_Inactive" ;
VAL_ 946 ReducedLoadMode_stat_ISig_4 3 "ReducedLoadMode_stat_NotAvailable" 2 "ReducedLoadMode_stat_Error" 1 "ReducedLoadMode_stat_ReducedLoadMode" 0 "ReducedLoadMode_stat_NormalMode" ;
VAL_ 946 RearAxleDiffLockActvnDrvrReq_ISi 3 "DisengageEngage_NotAvailable" 2 "DisengageEngage_Error" 1 "DisengageEngage_Engage" 0 "DisengageEngage_Disengage" ;
VAL_ 946 Pto2DrivingRequest 3 "OffOn_NotAvailable" 2 "OffOn_Error" 1 "OffOn_On" 0 "OffOn_Off" ;
VAL_ 946 RrInterAxlDiffLockActvnFuncReq_I 3 "DisengagedEngaged_NotAvailable" 2 "DisengagedEngaged_Error" 1 "DisengagedEngaged_Engaged" 0 "DisengagedEngaged_Disengaged" ;
VAL_ 946 CartridgeChangedDrvrReset_rqst_I 3 "DisableEnable_NotAvailable" 2 "DisableEnable_Error" 1 "DisableEnable_Enable" 0 "DisableEnable_Disable" ;
VAL_ 946 RrInterAxlDiffLockActvnDrvrReq_I 3 "DisengageEngage_NotAvailable" 2 "DisengageEngage_Error" 1 "DisengageEngage_Engage" 0 "DisengageEngage_Disengage" ;
VAL_ 946 Pto2Status_ISig_4 3 "InactiveActive_NotAvailable" 2 "InactiveActive_Error" 1 "InactiveActive_Active" 0 "InactiveActive_Inactive" ;
VAL_ 946 Pto4Status 3 "InactiveActive_NotAvailable" 2 "InactiveActive_Error" 1 "InactiveActive_Active" 0 "InactiveActive_Inactive" ;
VAL_ 946 Pto1DrivingRequest 3 "OffOn_NotAvailable" 2 "OffOn_Error" 1 "OffOn_On" 0 "OffOn_Off" ;
SIG_GROUP_ 1519 WGTrckTPMThresCfg_sg 1 : WGTrckTPMThresCfg_ExtOverPres WGTrckTPMThresCfg_AxleNr WGTrckTPMThresCfg_ExtUnderPres WGTrckTPMThresCfg_UnderPres WGTrckTPMThresCfg_OverPres;
SIG_GROUP_ 1356 WGTrail5TPMInf_sg 1 : WGTrail5TPMInf_Pressure WGTrail5TPMInf_BatteryStatus WGTrail5TPMInf_TgtPressure WGTrail5TPMInf_Temperature WGTrail5TPMInf_TemperatureStatus WGTrail5TPMInf_PressureStatus WGTrail5TPMInf_FastPressureLoss WGTrail5TPMInf_WheelLocation WGTrail5TPMInf_SensorIDProgStat;
SIG_GROUP_ 1355 WGTrail4TPMInf_sg 1 : WGTrail4TPMInf_Temperature WGTrail4TPMInf_TemperatureStatus WGTrail4TPMInf_PressureStatus WGTrail4TPMInf_Pressure WGTrail4TPMInf_BatteryStatus WGTrail4TPMInf_SensorIDProgStat WGTrail4TPMInf_TgtPressure WGTrail4TPMInf_WheelLocation WGTrail4TPMInf_FastPressureLoss;
SIG_GROUP_ 1354 WGTrail3TPMInf_sg 1 : WGTrail3TPMInf_FastPressureLoss WGTrail3TPMInf_PressureStatus WGTrail3TPMInf_SensorIDProgStat WGTrail3TPMInf_WheelLocation WGTrail3TPMInf_TemperatureStatus WGTrail3TPMInf_Pressure WGTrail3TPMInf_BatteryStatus WGTrail3TPMInf_TgtPressure WGTrail3TPMInf_Temperature;
SIG_GROUP_ 1337 WGTrail2TPMInf_sg 1 : WGTrail2TPMInf_Pressure WGTrail2TPMInf_WheelLocation WGTrail2TPMInf_TgtPressure WGTrail2TPMInf_Temperature WGTrail2TPMInf_PressureStatus WGTrail2TPMInf_FastPressureLoss WGTrail2TPMInf_SensorIDProgStat WGTrail2TPMInf_TemperatureStatus WGTrail2TPMInf_BatteryStatus;
SIG_GROUP_ 1336 WGTrail1TPMInf_sg 1 : WGTrail1TPMInf_BatteryStatus WGTrail1TPMInf_WheelLocation WGTrail1TPMInf_Pressure WGTrail1TPMInf_Temperature WGTrail1TPMInf_TemperatureStatus WGTrail1TPMInf_TgtPressure WGTrail1TPMInf_SensorIDProgStat WGTrail1TPMInf_PressureStatus WGTrail1TPMInf_FastPressureLoss;
SIG_GROUP_ 1283 WGTPMPosOfWMResp_sg 1 : WGTPMPosOfWMResp_VehiclePos WGTPMPosOfWMResp_TireId WGTPMPosOfWMResp_Status;
SIG_GROUP_ 1518 Trail4WGTPMAxlTireCfg_sg 1 : Trail4WGTPMAxlTireCfg_Axle2 Trail4WGTPMAxlTireCfg_Axle3 Trail4WGTPMAxlTireCfg_Axle5 Trail4WGTPMAxlTireCfg_Axle4 Trail4WGTPMAxlTireCfg_Axle1;
SIG_GROUP_ 1518 Trail5WGTPMAxlTireCfg_sg 1 : Trail5WGTPMAxlTireCfg_Axle2 Trail5WGTPMAxlTireCfg_Axle3 Trail5WGTPMAxlTireCfg_Axle4 Trail5WGTPMAxlTireCfg_Axle5 Trail5WGTPMAxlTireCfg_Axle1;
SIG_GROUP_ 1520 Trail3WGTPMAxlTireCfg_sg 1 : Trail3WGTPMAxlTireCfg_Axle2 Trail3WGTPMAxlTireCfg_Axle3 Trail3WGTPMAxlTireCfg_Axle1 Trail3WGTPMAxlTireCfg_Axle4 Trail3WGTPMAxlTireCfg_Axle5;
SIG_GROUP_ 1520 Trail2WGTPMAxlTireCfg_sg 1 : Trail2WGTPMAxlTireCfg_Axle3 Trail2WGTPMAxlTireCfg_Axle2 Trail2WGTPMAxlTireCfg_Axle5 Trail2WGTPMAxlTireCfg_Axle1 Trail2WGTPMAxlTireCfg_Axle4;
SIG_GROUP_ 1520 WGTruckTPMAxlTireCfg_sg 1 : WGTruckTPMAxlTireCfg_Axle5 WGTruckTPMAxlTireCfg_Axle4 WGTruckTPMAxlTireCfg_Axle3 WGTruckTPMAxlTireCfg_Axle2 WGTruckTPMAxlTireCfg_Axle1;
SIG_GROUP_ 1520 Trail1WGTPMAxlTireCfg_sg 1 : Trail1WGTPMAxlTireCfg_Axle4 Trail1WGTPMAxlTireCfg_Axle1 Trail1WGTPMAxlTireCfg_Axle5 Trail1WGTPMAxlTireCfg_Axle3 Trail1WGTPMAxlTireCfg_Axle2;
SIG_GROUP_ 1335 WGTruckTPMInfo_sg 1 : WGTruckTPMInfo_TgtPressure WGTruckTPMInfo_Temperature WGTruckTPMInfo_WheelLocation WGTruckTPMInfo_Pressure WGTruckTPMInfo_TemperatureStatus WGTruckTPMInfo_FastPressureLoss WGTruckTPMInfo_PressureStatus WGTruckTPMInfo_SensorIDProgStat WGTruckTPMInfo_BatteryStatus;
SIG_GROUP_ 1267 KingPinUnlockCmd_sg 1 : KingPinUnlockCmd_CRC KingPinUnlockCmd_SqC KingPinUnlockCmd_Rqst;
SIG_GROUP_ 519 GlareFreeArea02_sg 1 : GlareFreeArea02_LeftAngle GlareFreeArea02_Distance GlareFreeArea02_RightAngle;
SIG_GROUP_ 518 GlareFreeArea01_sg 1 : GlareFreeArea01_Distance GlareFreeArea01_LeftAngle GlareFreeArea01_RightAngle;
SIG_GROUP_ 518 GlareFreeArea03_sg 1 : GlareFreeArea03_Distance GlareFreeArea03_RightAngle GlareFreeArea03_LeftAngle;
SIG_GROUP_ 1370 TPMSetPresThresCfg_sg_ISig_4 1 : TPMSetPresThresCfg_VehiclePos_IS TPMSetPresThresCfg_ExtUnderPres_ TPMSetPresThresCfg_OverPres_ISig TPMSetPresThresCfg_AxleNr_ISig_4 TPMSetPresThresCfg_ExtOverPres_I TPMSetPresThresCfg_UnderPres_ISi;
SIG_GROUP_ 1373 TPMPosOfWMReq_sg_ISig_4 1 : TPMPosOfWMReq_VehiclePos_ISig_4 TPMPosOfWMReq_TireId_ISig_4;
SIG_GROUP_ 1373 TPMSetAxleRefPres_sg_ISig_4 1 : TPMSetAxleRefPres_Axle2_ISig_4 TPMSetAxleRefPres_Axle3_ISig_4 TPMSetAxleRefPres_Axle4_ISig_4 TPMSetAxleRefPres_Axle5_ISig_4 TPMSetAxleRefPres_Axle1_ISig_4 TPMSetAxleRefPres_VehiclePos_ISi;
SIG_GROUP_ 390 LevelRequest_sg_ISig_4 1 : LevelRequest_FrontAxle_ISig_4 LevelRequest_RearAxle_ISig_4 LevelRequest_RollRequest_ISig_4;
